VERSION ""

NS_ :

BS_:

BU_:

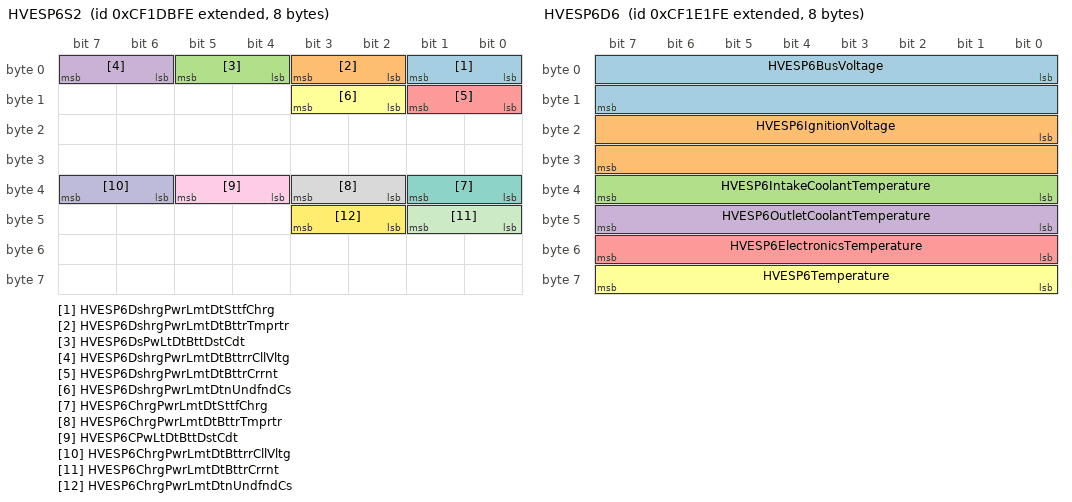
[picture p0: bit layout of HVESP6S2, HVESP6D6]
BO_ 2364660734 HVESP6S2: 8 Vector__XXX
 SG_ HVESP6DshrgPwrLmtDtSttfChrg : 0|2@1+ (1,0) [0|3] "" Vector__XXX
 SG_ HVESP6DshrgPwrLmtDtBttrTmprtr : 2|2@1+ (1,0) [0|3] "" Vector__XXX
 SG_ HVESP6DsPwLtDtBttDstCdt : 4|2@1+ (1,0) [0|3] "" Vector__XXX
 SG_ HVESP6DshrgPwrLmtDtBttrrCllVltg : 6|2@1+ (1,0) [0|3] "" Vector__XXX
 SG_ HVESP6DshrgPwrLmtDtBttrCrrnt : 8|2@1+ (1,0) [0|3] "" Vector__XXX
 SG_ HVESP6DshrgPwrLmtDtnUndfndCs : 10|2@1+ (1,0) [0|3] "" Vector__XXX
 SG_ HVESP6ChrgPwrLmtDtSttfChrg : 32|2@1+ (1,0) [0|3] "" Vector__XXX
 SG_ HVESP6ChrgPwrLmtDtBttrTmprtr : 34|2@1+ (1,0) [0|3] "" Vector__XXX
 SG_ HVESP6CPwLtDtBttDstCdt : 36|2@1+ (1,0) [0|3] "" Vector__XXX
 SG_ HVESP6ChrgPwrLmtDtBttrrCllVltg : 38|2@1+ (1,0) [0|3] "" Vector__XXX
 SG_ HVESP6ChrgPwrLmtDtBttrCrrnt : 40|2@1+ (1,0) [0|3] "" Vector__XXX
 SG_ HVESP6ChrgPwrLmtDtnUndfndCs : 42|2@1+ (1,0) [0|3] "" Vector__XXX

BO_ 2364660990 HVESP6D1: 8 Vector__XXX
 SG_ HVESP6AvailableDischargePower : 0|16@1+ (0.05,0) [0|3212.75] "kW" Vector__XXX
 SG_ HVESP6AvailableChargePower : 16|16@1+ (0.05,0) [0|3212.75] "kW" Vector__XXX
 SG_ HVESP6VoltageLevel : 32|16@1+ (0.05,0) [0|3212.75] "V" Vector__XXX
 SG_ HVESP6Current : 48|16@1+ (0.05,-1600) [-1600|1612.75] "A" Vector__XXX

BO_ 2364661246 HVESP6D2: 8 Vector__XXX
 SG_ HVESP6FastUpdateStateofCharge : 0|16@1+ (0.0015625,0) [0|100.3984375] "%" Vector__XXX
 SG_ HVESP6HighestCellVoltage : 16|16@1+ (0.001,0) [0|64.255] "V" Vector__XXX
 SG_ HVESP6LowestCellVoltage : 32|16@1+ (0.001,0) [0|64.255] "V" Vector__XXX
 SG_ HVESP6CllVltgDffrntlStts : 48|4@1+ (1,0) [0|15] "" Vector__XXX

BO_ 2364661502 HVESP6D3: 8 Vector__XXX
 SG_ HVESP6HighestCellTemperature : 0|16@1+ (0.03125,-273) [-273|1734.96875] "degC" Vector__XXX
 SG_ HVESP6LowestCellTemperature : 16|16@1+ (0.03125,-273) [-273|1734.96875] "degC" Vector__XXX
 SG_ HVESP6AverageCellTemperature : 32|16@1+ (0.03125,-273) [-273|1734.96875] "degC" Vector__XXX
 SG_ HVESP6CllTmprtrDffrntlStts : 48|2@1+ (1,0) [0|3] "" Vector__XXX

BO_ 2364661758 HVESP6D4: 8 Vector__XXX
 SG_ HVESP6DischargeCapacity : 0|16@1+ (0.01,0) [0|642.55] "Ah" Vector__XXX
 SG_ HVESP6ChargeCapacity : 16|16@1+ (0.01,0) [0|642.55] "Ah" Vector__XXX
 SG_ HVESP6CellBalancingCount : 32|16@1+ (1,0) [0|64255] "count" Vector__XXX

BO_ 2364662014 HVESP6D5: 8 Vector__XXX
 SG_ HVESP6DischargeCurrentLimit : 0|16@1+ (0.05,-1600) [-1600|1612.75] "A" Vector__XXX
 SG_ HVESP6ChargeCurrentLimit : 16|16@1+ (0.05,-1600) [-1600|1612.75] "A" Vector__XXX
 SG_ HVESP6LowestCellStateofCharge : 32|16@1+ (0.0015625,0) [0|100.3984375] "%" Vector__XXX
 SG_ HVESP6HighestCellStateofCharge : 48|16@1+ (0.0015625,0) [0|100.3984375] "%" Vector__XXX

BO_ 2364662270 HVESP6D6: 8 Vector__XXX
 SG_ HVESP6BusVoltage : 0|16@1+ (0.05,0) [0|3212.75] "V" Vector__XXX
 SG_ HVESP6IgnitionVoltage : 16|16@1+ (0.01,0) [0|642.55] "V" Vector__XXX
 SG_ HVESP6IntakeCoolantTemperature : 32|8@1+ (1,-40) [-40|210] "degC" Vector__XXX
 SG_ HVESP6OutletCoolantTemperature : 40|8@1+ (1,-40) [-40|210] "degC" Vector__XXX
 SG_ HVESP6ElectronicsTemperature : 48|8@1+ (1,-40) [-40|210] "degC" Vector__XXX
 SG_ HVESP6Temperature : 56|8@1+ (1,-40) [-40|210] "degC" Vector__XXX

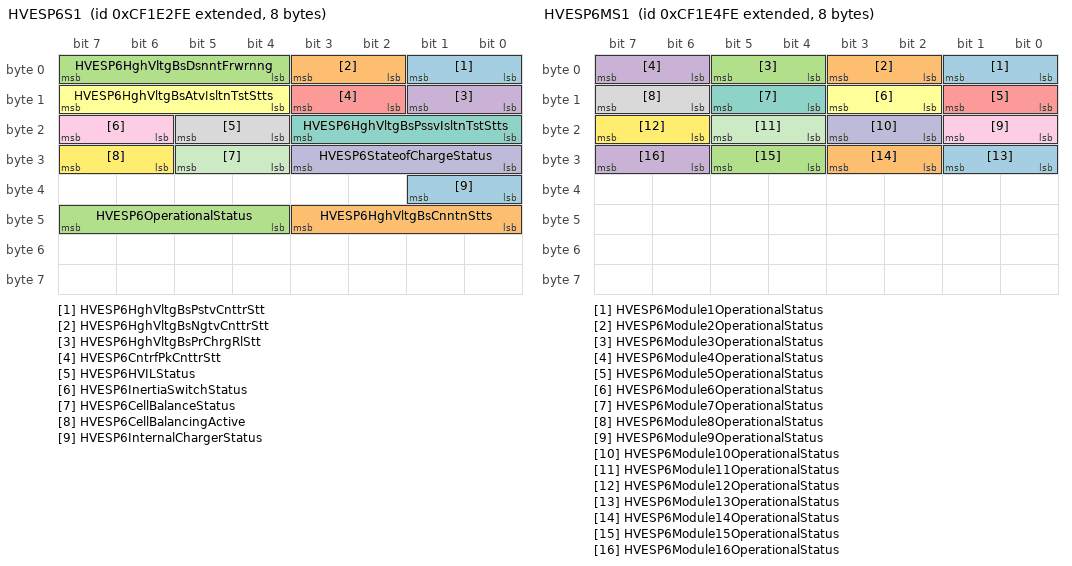
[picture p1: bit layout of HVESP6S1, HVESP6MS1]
BO_ 2364662526 HVESP6S1: 8 Vector__XXX
 SG_ HVESP6HghVltgBsPstvCnttrStt : 0|2@1+ (1,0) [0|3] "" Vector__XXX
 SG_ HVESP6HghVltgBsNgtvCnttrStt : 2|2@1+ (1,0) [0|3] "" Vector__XXX
 SG_ HVESP6HghVltgBsDsnntFrwrnng : 4|4@1+ (1,0) [0|15] "" Vector__XXX
 SG_ HVESP6HghVltgBsPrChrgRlStt : 8|2@1+ (1,0) [0|3] "" Vector__XXX
 SG_ HVESP6CntrfPkCnttrStt : 10|2@1+ (1,0) [0|3] "" Vector__XXX
 SG_ HVESP6HghVltgBsAtvIsltnTstStts : 12|4@1+ (1,0) [0|15] "" Vector__XXX
 SG_ HVESP6HghVltgBsPssvIsltnTstStts : 16|4@1+ (1,0) [0|15] "" Vector__XXX
 SG_ HVESP6HVILStatus : 20|2@1+ (1,0) [0|3] "" Vector__XXX
 SG_ HVESP6InertiaSwitchStatus : 22|2@1+ (1,0) [0|3] "" Vector__XXX
 SG_ HVESP6StateofChargeStatus : 24|4@1+ (1,0) [0|15] "" Vector__XXX
 SG_ HVESP6CellBalanceStatus : 28|2@1+ (1,0) [0|3] "" Vector__XXX
 SG_ HVESP6CellBalancingActive : 30|2@1+ (1,0) [0|3] "" Vector__XXX
 SG_ HVESP6InternalChargerStatus : 32|2@1+ (1,0) [0|3] "" Vector__XXX
 SG_ HVESP6HghVltgBsCnntnStts : 40|4@1+ (1,0) [0|15] "" Vector__XXX
 SG_ HVESP6OperationalStatus : 44|4@1+ (1,0) [0|15] "" Vector__XXX

BO_ 2364662782 HVESP6D7: 8 Vector__XXX
 SG_ HVESP6DischargeEnergyCapacity : 0|24@1+ (0.001,0) [0|16449.535] "kWh" Vector__XXX
 SG_ HVESP6ChargeEnergyCapacity : 24|24@1+ (0.001,0) [0|16449.535] "kWh" Vector__XXX
 SG_ HVESP6MaximumChargeVoltageLimit : 48|16@1+ (0.05,0) [0|3212.75] "V" Vector__XXX

BO_ 2364663038 HVESP6MS1: 8 Vector__XXX
 SG_ HVESP6Module1OperationalStatus : 0|2@1+ (1,0) [0|3] "" Vector__XXX
 SG_ HVESP6Module2OperationalStatus : 2|2@1+ (1,0) [0|3] "" Vector__XXX
 SG_ HVESP6Module3OperationalStatus : 4|2@1+ (1,0) [0|3] "" Vector__XXX
 SG_ HVESP6Module4OperationalStatus : 6|2@1+ (1,0) [0|3] "" Vector__XXX
 SG_ HVESP6Module5OperationalStatus : 8|2@1+ (1,0) [0|3] "" Vector__XXX
 SG_ HVESP6Module6OperationalStatus : 10|2@1+ (1,0) [0|3] "" Vector__XXX
 SG_ HVESP6Module7OperationalStatus : 12|2@1+ (1,0) [0|3] "" Vector__XXX
 SG_ HVESP6Module8OperationalStatus : 14|2@1+ (1,0) [0|3] "" Vector__XXX
 SG_ HVESP6Module9OperationalStatus : 16|2@1+ (1,0) [0|3] "" Vector__XXX
 SG_ HVESP6Module10OperationalStatus : 18|2@1+ (1,0) [0|3] "" Vector__XXX
 SG_ HVESP6Module11OperationalStatus : 20|2@1+ (1,0) [0|3] "" Vector__XXX
 SG_ HVESP6Module12OperationalStatus : 22|2@1+ (1,0) [0|3] "" Vector__XXX
 SG_ HVESP6Module13OperationalStatus : 24|2@1+ (1,0) [0|3] "" Vector__XXX
 SG_ HVESP6Module14OperationalStatus : 26|2@1+ (1,0) [0|3] "" Vector__XXX
 SG_ HVESP6Module15OperationalStatus : 28|2@1+ (1,0) [0|3] "" Vector__XXX
 SG_ HVESP6Module16OperationalStatus : 30|2@1+ (1,0) [0|3] "" Vector__XXX

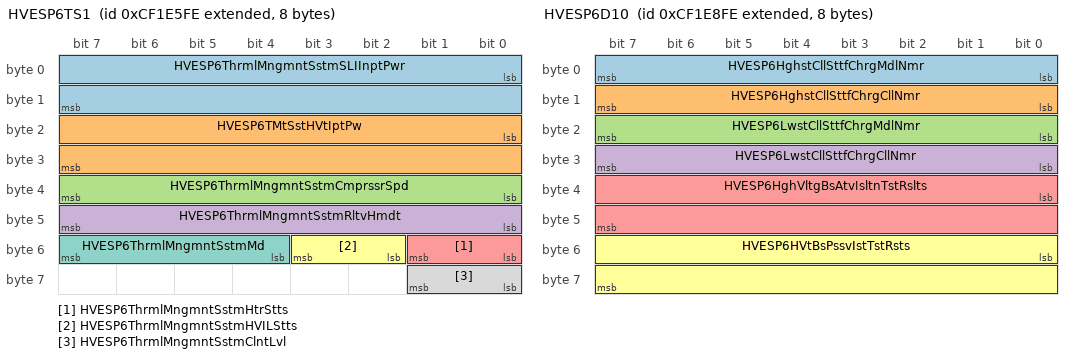
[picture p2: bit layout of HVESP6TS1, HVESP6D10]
BO_ 2364663294 HVESP6TS1: 8 Vector__XXX
 SG_ HVESP6ThrmlMngmntSstmSLIInptPwr : 0|16@1+ (0.5,0) [0|32127.5] "W" Vector__XXX
 SG_ HVESP6TMtSstHVtIptPw : 16|16@1+ (0.5,0) [0|32127.5] "W" Vector__XXX
 SG_ HVESP6ThrmlMngmntSstmCmprssrSpd : 32|8@1+ (32,0) [0|8000] "rpm" Vector__XXX
 SG_ HVESP6ThrmlMngmntSstmRltvHmdt : 40|8@1+ (0.4,0) [0|100] "%" Vector__XXX
 SG_ HVESP6ThrmlMngmntSstmHtrStts : 48|2@1+ (1,0) [0|3] "" Vector__XXX
 SG_ HVESP6ThrmlMngmntSstmHVILStts : 50|2@1+ (1,0) [0|3] "" Vector__XXX
 SG_ HVESP6ThrmlMngmntSstmMd : 52|4@1+ (1,0) [0|15] "" Vector__XXX
 SG_ HVESP6ThrmlMngmntSstmClntLvl : 56|2@1+ (1,0) [0|3] "" Vector__XXX

BO_ 2364663550 HVESP6D8: 8 Vector__XXX
 SG_ HVESP6HghstCllVltgMdlNmr : 0|8@1+ (1,0) [0|250] "count" Vector__XXX
 SG_ HVESP6HghstCllVltgCllNmr : 8|8@1+ (1,0) [0|250] "count" Vector__XXX
 SG_ HVESP6LwstCllVltgMdlNmr : 16|8@1+ (1,0) [0|250] "count" Vector__XXX
 SG_ HVESP6LwstCllVltgCllNmr : 24|8@1+ (1,0) [0|250] "count" Vector__XXX
 SG_ HVESP6AverageCellVoltage : 32|16@1+ (0.001,0) [0|64.255] "V" Vector__XXX

BO_ 2364663806 HVESP6D9: 8 Vector__XXX
 SG_ HVESP6HghstCllTmprtrMdlNmr : 0|8@1+ (1,0) [0|250] "count" Vector__XXX
 SG_ HVESP6HghstCllTmprtrCllNmr : 8|8@1+ (1,0) [0|250] "count" Vector__XXX
 SG_ HVESP6LwstCllTmprtrMdlNmr : 16|8@1+ (1,0) [0|250] "count" Vector__XXX
 SG_ HVESP6LwstCllTmprtrCllNmr : 24|8@1+ (1,0) [0|250] "count" Vector__XXX

BO_ 2364664062 HVESP6D10: 8 Vector__XXX
 SG_ HVESP6HghstCllSttfChrgMdlNmr : 0|8@1+ (1,0) [0|250] "count" Vector__XXX
 SG_ HVESP6HghstCllSttfChrgCllNmr : 8|8@1+ (1,0) [0|250] "count" Vector__XXX
 SG_ HVESP6LwstCllSttfChrgMdlNmr : 16|8@1+ (1,0) [0|250] "count" Vector__XXX
 SG_ HVESP6LwstCllSttfChrgCllNmr : 24|8@1+ (1,0) [0|250] "count" Vector__XXX
 SG_ HVESP6HghVltgBsAtvIsltnTstRslts : 32|16@1+ (0.1,0) [0|6425.5] "ohm/V" Vector__XXX
 SG_ HVESP6HVtBsPssvIstTstRsts : 48|16@1+ (0.1,0) [0|6425.5] "ohm/V" Vector__XXX

BO_ 2364664318 HVESP6D11: 8 Vector__XXX
 SG_ HVESP6BsVltgNgtvtChsssGrndVltg : 0|16@1+ (0.05,0) [0|3212.75] "V" Vector__XXX
 SG_ HVESP6VltgLvlNgtvtChsssGrndVltg : 16|16@1+ (0.05,0) [0|3212.75] "V" Vector__XXX

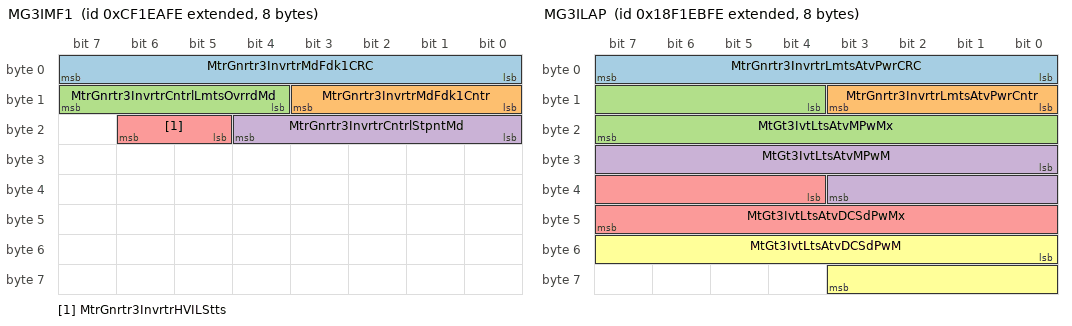
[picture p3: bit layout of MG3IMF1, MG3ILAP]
BO_ 2364664574 MG3IMF1: 8 Vector__XXX
 SG_ MtrGnrtr3InvrtrMdFdk1CRC : 0|8@1+ (1,0) [0|255] "count" Vector__XXX
 SG_ MtrGnrtr3InvrtrMdFdk1Cntr : 8|4@1+ (1,0) [0|15] "" Vector__XXX
 SG_ MtrGnrtr3InvrtrCntrlLmtsOvrrdMd : 12|4@1+ (1,0) [0|15] "" Vector__XXX
 SG_ MtrGnrtr3InvrtrCntrlStpntMd : 16|5@1+ (1,0) [0|31] "" Vector__XXX
 SG_ MtrGnrtr3InvrtrHVILStts : 21|2@1+ (1,0) [0|3] "" Vector__XXX

BO_ 2565991422 MG3ILAP: 8 Vector__XXX
 SG_ MtrGnrtr3InvrtrLmtsAtvPwrCRC : 0|8@1+ (1,0) [0|255] "count" Vector__XXX
 SG_ MtrGnrtr3InvrtrLmtsAtvPwrCntr : 8|4@1+ (1,0) [0|15] "" Vector__XXX
 SG_ MtGt3IvtLtsAtvMPwMx : 12|12@1+ (42370,-125) [-125|125.9375] "%" Vector__XXX
 SG_ MtGt3IvtLtsAtvMPwM : 24|12@1+ (42370,-125) [-125|125.9375] "%" Vector__XXX
 SG_ MtGt3IvtLtsAtvDCSdPwMx : 36|12@1+ (42370,-125) [-125|125.9375] "%" Vector__XXX
 SG_ MtGt3IvtLtsAtvDCSdPwM : 48|12@1+ (42370,-125) [-125|125.9375] "%" Vector__XXX

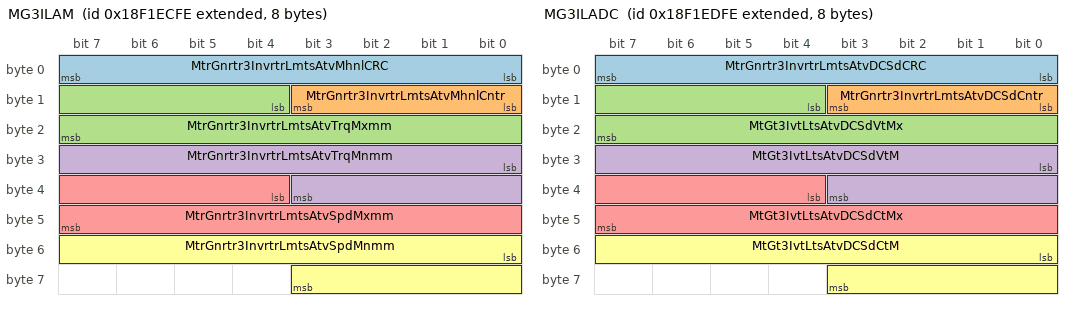
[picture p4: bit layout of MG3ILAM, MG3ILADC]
BO_ 2565991678 MG3ILAM: 8 Vector__XXX
 SG_ MtrGnrtr3InvrtrLmtsAtvMhnlCRC : 0|8@1+ (1,0) [0|255] "count" Vector__XXX
 SG_ MtrGnrtr3InvrtrLmtsAtvMhnlCntr : 8|4@1+ (1,0) [0|15] "" Vector__XXX
 SG_ MtrGnrtr3InvrtrLmtsAtvTrqMxmm : 12|12@1+ (42370,-125) [-125|125.9375] "%" Vector__XXX
 SG_ MtrGnrtr3InvrtrLmtsAtvTrqMnmm : 24|12@1+ (42370,-125) [-125|125.9375] "%" Vector__XXX
 SG_ MtrGnrtr3InvrtrLmtsAtvSpdMxmm : 36|12@1+ (42370,-125) [-125|125.9375] "%" Vector__XXX
 SG_ MtrGnrtr3InvrtrLmtsAtvSpdMnmm : 48|12@1+ (42370,-125) [-125|125.9375] "%" Vector__XXX

BO_ 2565991934 MG3ILADC: 8 Vector__XXX
 SG_ MtrGnrtr3InvrtrLmtsAtvDCSdCRC : 0|8@1+ (1,0) [0|255] "count" Vector__XXX
 SG_ MtrGnrtr3InvrtrLmtsAtvDCSdCntr : 8|4@1+ (1,0) [0|15] "" Vector__XXX
 SG_ MtGt3IvtLtsAtvDCSdVtMx : 12|12@1+ (42370,-125) [-125|125.9375] "%" Vector__XXX
 SG_ MtGt3IvtLtsAtvDCSdVtM : 24|12@1+ (42370,-125) [-125|125.9375] "%" Vector__XXX
 SG_ MtGt3IvtLtsAtvDCSdCtMx : 36|12@1+ (42370,-125) [-125|125.9375] "%" Vector__XXX
 SG_ MtGt3IvtLtsAtvDCSdCtM : 48|12@1+ (42370,-125) [-125|125.9375] "%" Vector__XXX

BO_ 2565992190 MG3ILV: 8 Vector__XXX
 SG_ MtrGnrtr3InvrtrSwthdIgntnVltg : 0|16@1+ (0.05,0) [0|3212.75] "V" Vector__XXX
 SG_ MtrGnrtr3InvrtrUnswthdSLIVltg : 16|16@1+ (0.05,0) [0|3212.75] "V" Vector__XXX

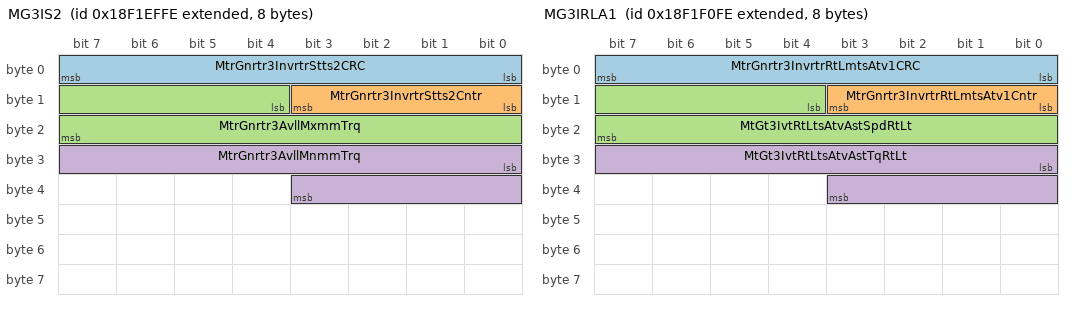
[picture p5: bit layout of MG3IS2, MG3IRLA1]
BO_ 2565992446 MG3IS2: 8 Vector__XXX
 SG_ MtrGnrtr3InvrtrStts2CRC : 0|8@1+ (1,0) [0|255] "count" Vector__XXX
 SG_ MtrGnrtr3InvrtrStts2Cntr : 8|4@1+ (1,0) [0|15] "" Vector__XXX
 SG_ MtrGnrtr3AvllMxmmTrq : 12|12@1+ (42370,-125) [-125|125.9375] "%" Vector__XXX
 SG_ MtrGnrtr3AvllMnmmTrq : 24|12@1+ (42370,-125) [-125|125.9375] "%" Vector__XXX

BO_ 2565992702 MG3IRLA1: 8 Vector__XXX
 SG_ MtrGnrtr3InvrtrRtLmtsAtv1CRC : 0|8@1+ (1,0) [0|255] "count" Vector__XXX
 SG_ MtrGnrtr3InvrtrRtLmtsAtv1Cntr : 8|4@1+ (1,0) [0|15] "" Vector__XXX
 SG_ MtGt3IvtRtLtsAtvAstSpdRtLt : 12|12@1+ (0.25,0) [0|1003.75] "%/s" Vector__XXX
 SG_ MtGt3IvtRtLtsAtvAstTqRtLt : 24|12@1+ (2,0) [0|8030] "%/s" Vector__XXX

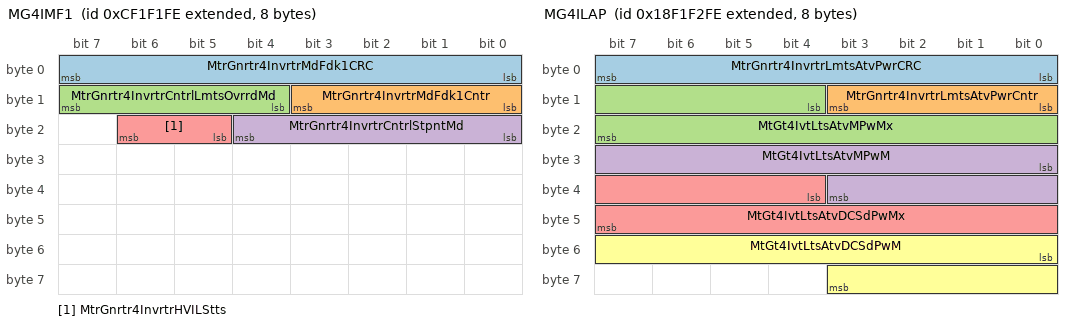
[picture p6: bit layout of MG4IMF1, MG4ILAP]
BO_ 2364666366 MG4IMF1: 8 Vector__XXX
 SG_ MtrGnrtr4InvrtrMdFdk1CRC : 0|8@1+ (1,0) [0|255] "count" Vector__XXX
 SG_ MtrGnrtr4InvrtrMdFdk1Cntr : 8|4@1+ (1,0) [0|15] "" Vector__XXX
 SG_ MtrGnrtr4InvrtrCntrlLmtsOvrrdMd : 12|4@1+ (1,0) [0|15] "" Vector__XXX
 SG_ MtrGnrtr4InvrtrCntrlStpntMd : 16|5@1+ (1,0) [0|31] "" Vector__XXX
 SG_ MtrGnrtr4InvrtrHVILStts : 21|2@1+ (1,0) [0|3] "" Vector__XXX

BO_ 2565993214 MG4ILAP: 8 Vector__XXX
 SG_ MtrGnrtr4InvrtrLmtsAtvPwrCRC : 0|8@1+ (1,0) [0|255] "count" Vector__XXX
 SG_ MtrGnrtr4InvrtrLmtsAtvPwrCntr : 8|4@1+ (1,0) [0|15] "" Vector__XXX
 SG_ MtGt4IvtLtsAtvMPwMx : 12|12@1+ (42370,-125) [-125|125.9375] "%" Vector__XXX
 SG_ MtGt4IvtLtsAtvMPwM : 24|12@1+ (42370,-125) [-125|125.9375] "%" Vector__XXX
 SG_ MtGt4IvtLtsAtvDCSdPwMx : 36|12@1+ (42370,-125) [-125|125.9375] "%" Vector__XXX
 SG_ MtGt4IvtLtsAtvDCSdPwM : 48|12@1+ (42370,-125) [-125|125.9375] "%" Vector__XXX

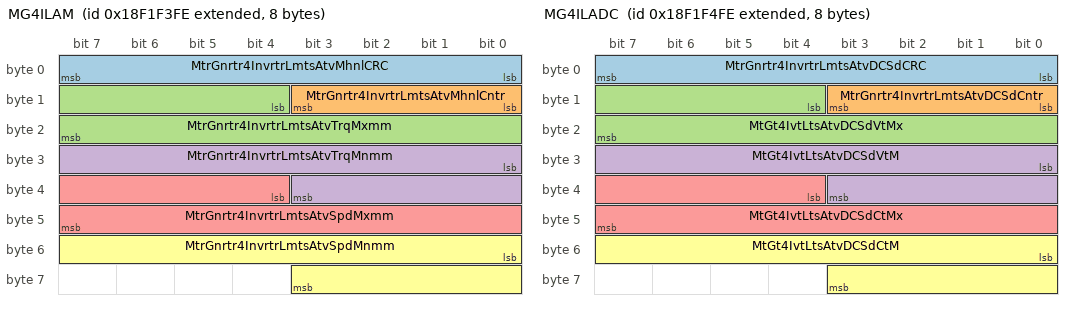
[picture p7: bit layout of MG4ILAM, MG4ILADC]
BO_ 2565993470 MG4ILAM: 8 Vector__XXX
 SG_ MtrGnrtr4InvrtrLmtsAtvMhnlCRC : 0|8@1+ (1,0) [0|255] "count" Vector__XXX
 SG_ MtrGnrtr4InvrtrLmtsAtvMhnlCntr : 8|4@1+ (1,0) [0|15] "" Vector__XXX
 SG_ MtrGnrtr4InvrtrLmtsAtvTrqMxmm : 12|12@1+ (42370,-125) [-125|125.9375] "%" Vector__XXX
 SG_ MtrGnrtr4InvrtrLmtsAtvTrqMnmm : 24|12@1+ (42370,-125) [-125|125.9375] "%" Vector__XXX
 SG_ MtrGnrtr4InvrtrLmtsAtvSpdMxmm : 36|12@1+ (42370,-125) [-125|125.9375] "%" Vector__XXX
 SG_ MtrGnrtr4InvrtrLmtsAtvSpdMnmm : 48|12@1+ (42370,-125) [-125|125.9375] "%" Vector__XXX

BO_ 2565993726 MG4ILADC: 8 Vector__XXX
 SG_ MtrGnrtr4InvrtrLmtsAtvDCSdCRC : 0|8@1+ (1,0) [0|255] "count" Vector__XXX
 SG_ MtrGnrtr4InvrtrLmtsAtvDCSdCntr : 8|4@1+ (1,0) [0|15] "" Vector__XXX
 SG_ MtGt4IvtLtsAtvDCSdVtMx : 12|12@1+ (42370,-125) [-125|125.9375] "%" Vector__XXX
 SG_ MtGt4IvtLtsAtvDCSdVtM : 24|12@1+ (42370,-125) [-125|125.9375] "%" Vector__XXX
 SG_ MtGt4IvtLtsAtvDCSdCtMx : 36|12@1+ (42370,-125) [-125|125.9375] "%" Vector__XXX
 SG_ MtGt4IvtLtsAtvDCSdCtM : 48|12@1+ (42370,-125) [-125|125.9375] "%" Vector__XXX

BO_ 2565993982 MG4ILV: 8 Vector__XXX
 SG_ MtrGnrtr4InvrtrSwthdIgntnVltg : 0|16@1+ (0.05,0) [0|3212.75] "V" Vector__XXX
 SG_ MtrGnrtr4InvrtrUnswthdSLIVltg : 16|16@1+ (0.05,0) [0|3212.75] "V" Vector__XXX

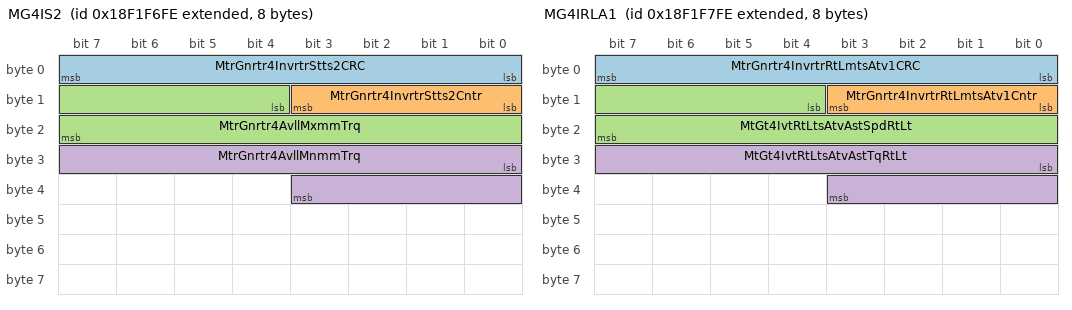
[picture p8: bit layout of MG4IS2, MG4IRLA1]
BO_ 2565994238 MG4IS2: 8 Vector__XXX
 SG_ MtrGnrtr4InvrtrStts2CRC : 0|8@1+ (1,0) [0|255] "count" Vector__XXX
 SG_ MtrGnrtr4InvrtrStts2Cntr : 8|4@1+ (1,0) [0|15] "" Vector__XXX
 SG_ MtrGnrtr4AvllMxmmTrq : 12|12@1+ (42370,-125) [-125|125.9375] "%" Vector__XXX
 SG_ MtrGnrtr4AvllMnmmTrq : 24|12@1+ (42370,-125) [-125|125.9375] "%" Vector__XXX

BO_ 2565994494 MG4IRLA1: 8 Vector__XXX
 SG_ MtrGnrtr4InvrtrRtLmtsAtv1CRC : 0|8@1+ (1,0) [0|255] "count" Vector__XXX
 SG_ MtrGnrtr4InvrtrRtLmtsAtv1Cntr : 8|4@1+ (1,0) [0|15] "" Vector__XXX
 SG_ MtGt4IvtRtLtsAtvAstSpdRtLt : 12|12@1+ (0.25,0) [0|1003.75] "%/s" Vector__XXX
 SG_ MtGt4IvtRtLtsAtvAstTqRtLt : 24|12@1+ (2,0) [0|8030] "%/s" Vector__XXX

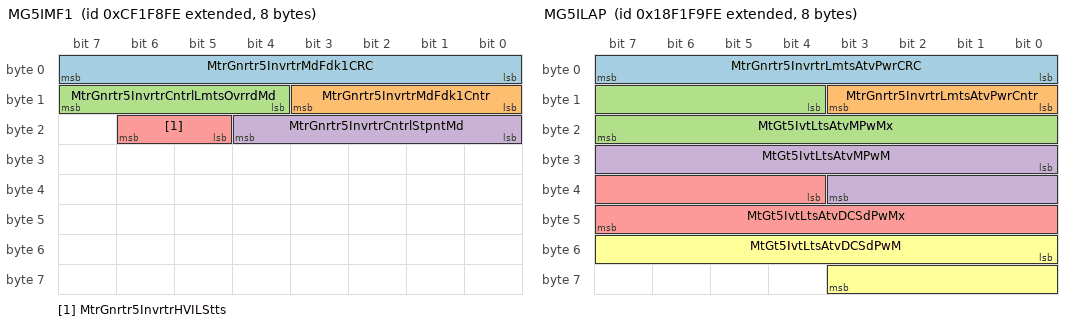
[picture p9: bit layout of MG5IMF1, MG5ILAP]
BO_ 2364668158 MG5IMF1: 8 Vector__XXX
 SG_ MtrGnrtr5InvrtrMdFdk1CRC : 0|8@1+ (1,0) [0|255] "count" Vector__XXX
 SG_ MtrGnrtr5InvrtrMdFdk1Cntr : 8|4@1+ (1,0) [0|15] "" Vector__XXX
 SG_ MtrGnrtr5InvrtrCntrlLmtsOvrrdMd : 12|4@1+ (1,0) [0|15] "" Vector__XXX
 SG_ MtrGnrtr5InvrtrCntrlStpntMd : 16|5@1+ (1,0) [0|31] "" Vector__XXX
 SG_ MtrGnrtr5InvrtrHVILStts : 21|2@1+ (1,0) [0|3] "" Vector__XXX

BO_ 2565995006 MG5ILAP: 8 Vector__XXX
 SG_ MtrGnrtr5InvrtrLmtsAtvPwrCRC : 0|8@1+ (1,0) [0|255] "count" Vector__XXX
 SG_ MtrGnrtr5InvrtrLmtsAtvPwrCntr : 8|4@1+ (1,0) [0|15] "" Vector__XXX
 SG_ MtGt5IvtLtsAtvMPwMx : 12|12@1+ (42370,-125) [-125|125.9375] "%" Vector__XXX
 SG_ MtGt5IvtLtsAtvMPwM : 24|12@1+ (42370,-125) [-125|125.9375] "%" Vector__XXX
 SG_ MtGt5IvtLtsAtvDCSdPwMx : 36|12@1+ (42370,-125) [-125|125.9375] "%" Vector__XXX
 SG_ MtGt5IvtLtsAtvDCSdPwM : 48|12@1+ (42370,-125) [-125|125.9375] "%" Vector__XXX

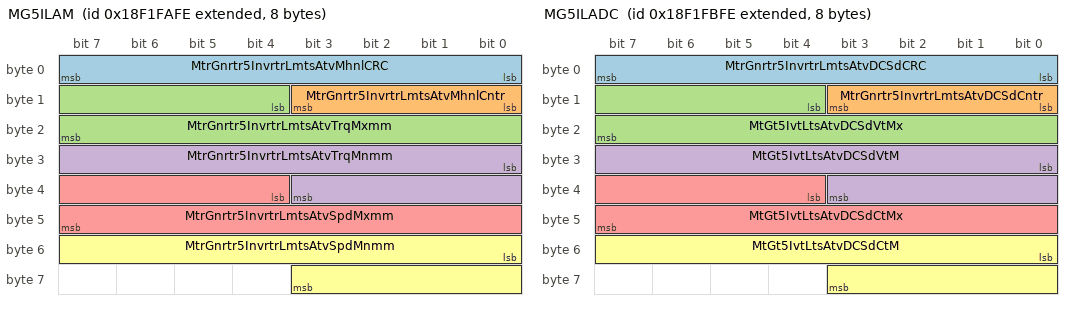
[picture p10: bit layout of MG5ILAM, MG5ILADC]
BO_ 2565995262 MG5ILAM: 8 Vector__XXX
 SG_ MtrGnrtr5InvrtrLmtsAtvMhnlCRC : 0|8@1+ (1,0) [0|255] "count" Vector__XXX
 SG_ MtrGnrtr5InvrtrLmtsAtvMhnlCntr : 8|4@1+ (1,0) [0|15] "" Vector__XXX
 SG_ MtrGnrtr5InvrtrLmtsAtvTrqMxmm : 12|12@1+ (42370,-125) [-125|125.9375] "%" Vector__XXX
 SG_ MtrGnrtr5InvrtrLmtsAtvTrqMnmm : 24|12@1+ (42370,-125) [-125|125.9375] "%" Vector__XXX
 SG_ MtrGnrtr5InvrtrLmtsAtvSpdMxmm : 36|12@1+ (42370,-125) [-125|125.9375] "%" Vector__XXX
 SG_ MtrGnrtr5InvrtrLmtsAtvSpdMnmm : 48|12@1+ (42370,-125) [-125|125.9375] "%" Vector__XXX

BO_ 2565995518 MG5ILADC: 8 Vector__XXX
 SG_ MtrGnrtr5InvrtrLmtsAtvDCSdCRC : 0|8@1+ (1,0) [0|255] "count" Vector__XXX
 SG_ MtrGnrtr5InvrtrLmtsAtvDCSdCntr : 8|4@1+ (1,0) [0|15] "" Vector__XXX
 SG_ MtGt5IvtLtsAtvDCSdVtMx : 12|12@1+ (42370,-125) [-125|125.9375] "%" Vector__XXX
 SG_ MtGt5IvtLtsAtvDCSdVtM : 24|12@1+ (42370,-125) [-125|125.9375] "%" Vector__XXX
 SG_ MtGt5IvtLtsAtvDCSdCtMx : 36|12@1+ (42370,-125) [-125|125.9375] "%" Vector__XXX
 SG_ MtGt5IvtLtsAtvDCSdCtM : 48|12@1+ (42370,-125) [-125|125.9375] "%" Vector__XXX

BO_ 2565995774 MG5ILV: 8 Vector__XXX
 SG_ MtrGnrtr5InvrtrSwthdIgntnVltg : 0|16@1+ (0.05,0) [0|3212.75] "V" Vector__XXX
 SG_ MtrGnrtr5InvrtrUnswthdSLIVltg : 16|16@1+ (0.05,0) [0|3212.75] "V" Vector__XXX

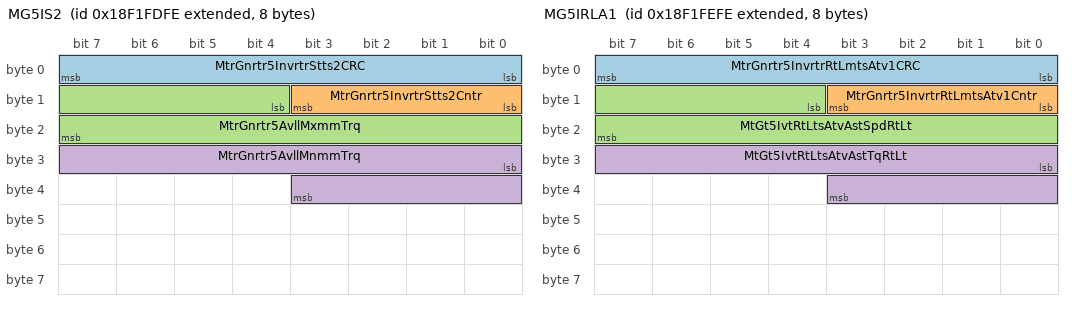
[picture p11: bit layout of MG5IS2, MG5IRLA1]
BO_ 2565996030 MG5IS2: 8 Vector__XXX
 SG_ MtrGnrtr5InvrtrStts2CRC : 0|8@1+ (1,0) [0|255] "count" Vector__XXX
 SG_ MtrGnrtr5InvrtrStts2Cntr : 8|4@1+ (1,0) [0|15] "" Vector__XXX
 SG_ MtrGnrtr5AvllMxmmTrq : 12|12@1+ (42370,-125) [-125|125.9375] "%" Vector__XXX
 SG_ MtrGnrtr5AvllMnmmTrq : 24|12@1+ (42370,-125) [-125|125.9375] "%" Vector__XXX

BO_ 2565996286 MG5IRLA1: 8 Vector__XXX
 SG_ MtrGnrtr5InvrtrRtLmtsAtv1CRC : 0|8@1+ (1,0) [0|255] "count" Vector__XXX
 SG_ MtrGnrtr5InvrtrRtLmtsAtv1Cntr : 8|4@1+ (1,0) [0|15] "" Vector__XXX
 SG_ MtGt5IvtRtLtsAtvAstSpdRtLt : 12|12@1+ (0.25,0) [0|1003.75] "%/s" Vector__XXX
 SG_ MtGt5IvtRtLtsAtvAstTqRtLt : 24|12@1+ (2,0) [0|8030] "%/s" Vector__XXX

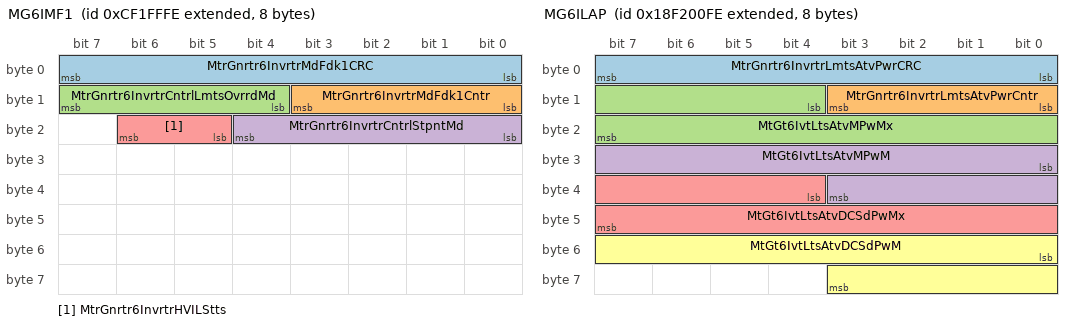
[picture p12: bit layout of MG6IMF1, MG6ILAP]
BO_ 2364669950 MG6IMF1: 8 Vector__XXX
 SG_ MtrGnrtr6InvrtrMdFdk1CRC : 0|8@1+ (1,0) [0|255] "count" Vector__XXX
 SG_ MtrGnrtr6InvrtrMdFdk1Cntr : 8|4@1+ (1,0) [0|15] "" Vector__XXX
 SG_ MtrGnrtr6InvrtrCntrlLmtsOvrrdMd : 12|4@1+ (1,0) [0|15] "" Vector__XXX
 SG_ MtrGnrtr6InvrtrCntrlStpntMd : 16|5@1+ (1,0) [0|31] "" Vector__XXX
 SG_ MtrGnrtr6InvrtrHVILStts : 21|2@1+ (1,0) [0|3] "" Vector__XXX

BO_ 2565996798 MG6ILAP: 8 Vector__XXX
 SG_ MtrGnrtr6InvrtrLmtsAtvPwrCRC : 0|8@1+ (1,0) [0|255] "count" Vector__XXX
 SG_ MtrGnrtr6InvrtrLmtsAtvPwrCntr : 8|4@1+ (1,0) [0|15] "" Vector__XXX
 SG_ MtGt6IvtLtsAtvMPwMx : 12|12@1+ (42370,-125) [-125|125.9375] "%" Vector__XXX
 SG_ MtGt6IvtLtsAtvMPwM : 24|12@1+ (42370,-125) [-125|125.9375] "%" Vector__XXX
 SG_ MtGt6IvtLtsAtvDCSdPwMx : 36|12@1+ (42370,-125) [-125|125.9375] "%" Vector__XXX
 SG_ MtGt6IvtLtsAtvDCSdPwM : 48|12@1+ (42370,-125) [-125|125.9375] "%" Vector__XXX

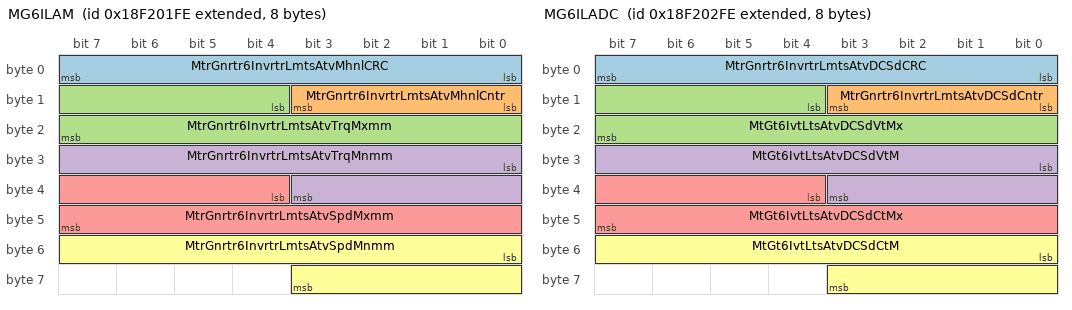
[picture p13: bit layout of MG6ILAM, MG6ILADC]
BO_ 2565997054 MG6ILAM: 8 Vector__XXX
 SG_ MtrGnrtr6InvrtrLmtsAtvMhnlCRC : 0|8@1+ (1,0) [0|255] "count" Vector__XXX
 SG_ MtrGnrtr6InvrtrLmtsAtvMhnlCntr : 8|4@1+ (1,0) [0|15] "" Vector__XXX
 SG_ MtrGnrtr6InvrtrLmtsAtvTrqMxmm : 12|12@1+ (42370,-125) [-125|125.9375] "%" Vector__XXX
 SG_ MtrGnrtr6InvrtrLmtsAtvTrqMnmm : 24|12@1+ (42370,-125) [-125|125.9375] "%" Vector__XXX
 SG_ MtrGnrtr6InvrtrLmtsAtvSpdMxmm : 36|12@1+ (42370,-125) [-125|125.9375] "%" Vector__XXX
 SG_ MtrGnrtr6InvrtrLmtsAtvSpdMnmm : 48|12@1+ (42370,-125) [-125|125.9375] "%" Vector__XXX

BO_ 2565997310 MG6ILADC: 8 Vector__XXX
 SG_ MtrGnrtr6InvrtrLmtsAtvDCSdCRC : 0|8@1+ (1,0) [0|255] "count" Vector__XXX
 SG_ MtrGnrtr6InvrtrLmtsAtvDCSdCntr : 8|4@1+ (1,0) [0|15] "" Vector__XXX
 SG_ MtGt6IvtLtsAtvDCSdVtMx : 12|12@1+ (42370,-125) [-125|125.9375] "%" Vector__XXX
 SG_ MtGt6IvtLtsAtvDCSdVtM : 24|12@1+ (42370,-125) [-125|125.9375] "%" Vector__XXX
 SG_ MtGt6IvtLtsAtvDCSdCtMx : 36|12@1+ (42370,-125) [-125|125.9375] "%" Vector__XXX
 SG_ MtGt6IvtLtsAtvDCSdCtM : 48|12@1+ (42370,-125) [-125|125.9375] "%" Vector__XXX

BO_ 2565997566 MG6ILV: 8 Vector__XXX
 SG_ MtrGnrtr6InvrtrSwthdIgntnVltg : 0|16@1+ (0.05,0) [0|3212.75] "V" Vector__XXX
 SG_ MtrGnrtr6InvrtrUnswthdSLIVltg : 16|16@1+ (0.05,0) [0|3212.75] "V" Vector__XXX

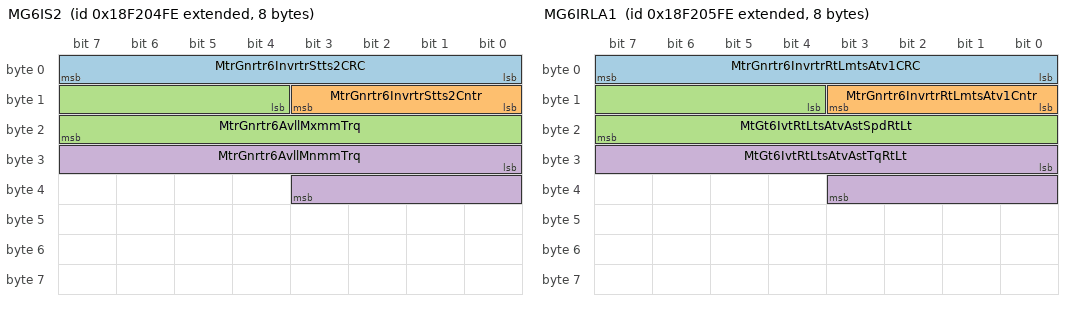
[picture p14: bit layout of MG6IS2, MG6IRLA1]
BO_ 2565997822 MG6IS2: 8 Vector__XXX
 SG_ MtrGnrtr6InvrtrStts2CRC : 0|8@1+ (1,0) [0|255] "count" Vector__XXX
 SG_ MtrGnrtr6InvrtrStts2Cntr : 8|4@1+ (1,0) [0|15] "" Vector__XXX
 SG_ MtrGnrtr6AvllMxmmTrq : 12|12@1+ (42370,-125) [-125|125.9375] "%" Vector__XXX
 SG_ MtrGnrtr6AvllMnmmTrq : 24|12@1+ (42370,-125) [-125|125.9375] "%" Vector__XXX

BO_ 2565998078 MG6IRLA1: 8 Vector__XXX
 SG_ MtrGnrtr6InvrtrRtLmtsAtv1CRC : 0|8@1+ (1,0) [0|255] "count" Vector__XXX
 SG_ MtrGnrtr6InvrtrRtLmtsAtv1Cntr : 8|4@1+ (1,0) [0|15] "" Vector__XXX
 SG_ MtGt6IvtRtLtsAtvAstSpdRtLt : 12|12@1+ (0.25,0) [0|1003.75] "%/s" Vector__XXX
 SG_ MtGt6IvtRtLtsAtvAstTqRtLt : 24|12@1+ (2,0) [0|8030] "%/s" Vector__XXX

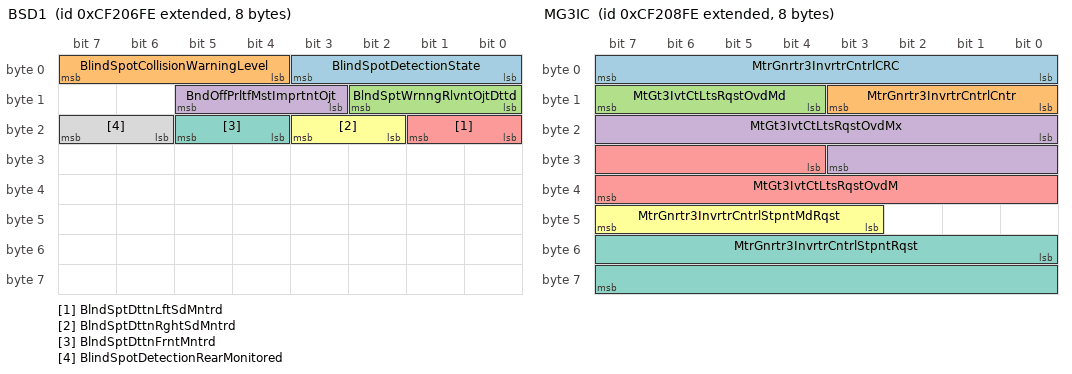
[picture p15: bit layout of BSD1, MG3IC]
BO_ 2364671742 BSD1: 8 Vector__XXX
 SG_ BlindSpotDetectionState : 0|4@1+ (1,0) [0|15] "" Vector__XXX
 SG_ BlindSpotCollisionWarningLevel : 4|4@1+ (1,0) [0|15] "" Vector__XXX
 SG_ BlndSptWrnngRlvntOjtDttd : 8|3@1+ (1,0) [0|7] "" Vector__XXX
 SG_ BndOffPrltfMstImprtntOjt : 11|3@1+ (1,0) [0|7] "" Vector__XXX
 SG_ BlndSptDttnLftSdMntrd : 16|2@1+ (1,0) [0|3] "" Vector__XXX
 SG_ BlndSptDttnRghtSdMntrd : 18|2@1+ (1,0) [0|3] "" Vector__XXX
 SG_ BlndSptDttnFrntMntrd : 20|2@1+ (1,0) [0|3] "" Vector__XXX
 SG_ BlindSpotDetectionRearMonitored : 22|2@1+ (1,0) [0|3] "" Vector__XXX

BO_ 2364671998 WINCH1: 8 Vector__XXX
 SG_ WinchMotorEncoderPosition : 0|16@1+ (1,0) [0|64255] "count" Vector__XXX
 SG_ WinchRevolutionCounter : 16|16@1+ (1,-32128) [-32128|32127] "count" Vector__XXX

BO_ 2364672254 MG3IC: 8 Vector__XXX
 SG_ MtrGnrtr3InvrtrCntrlCRC : 0|8@1+ (1,0) [0|255] "count" Vector__XXX
 SG_ MtrGnrtr3InvrtrCntrlCntr : 8|4@1+ (1,0) [0|15] "" Vector__XXX
 SG_ MtGt3IvtCtLtsRqstOvdMd : 12|4@1+ (1,0) [0|15] "" Vector__XXX
 SG_ MtGt3IvtCtLtsRqstOvdMx : 16|12@1+ (42370,-125) [-125|125.9375] "%" Vector__XXX
 SG_ MtGt3IvtCtLtsRqstOvdM : 28|12@1+ (42370,-125) [-125|125.9375] "%" Vector__XXX
 SG_ MtrGnrtr3InvrtrCntrlStpntMdRqst : 43|5@1+ (1,0) [0|31] "" Vector__XXX
 SG_ MtrGnrtr3InvrtrCntrlStpntRqst : 48|16@1+ (0.00390625,-125) [-125|125.99609375] "%" Vector__XXX

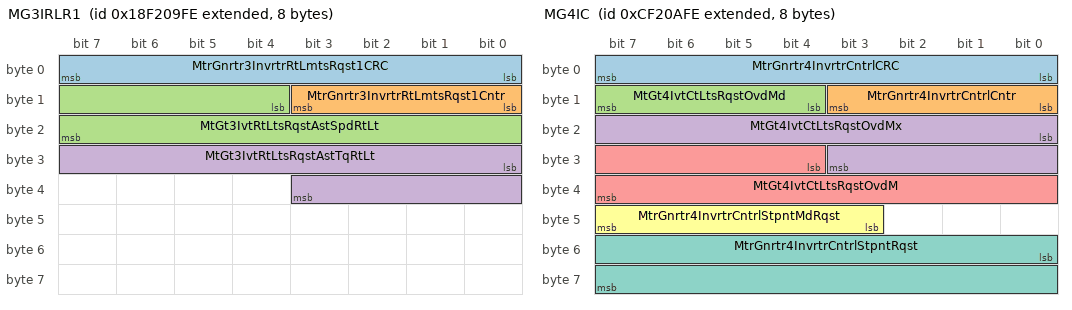
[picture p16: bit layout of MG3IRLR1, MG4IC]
BO_ 2565999102 MG3IRLR1: 8 Vector__XXX
 SG_ MtrGnrtr3InvrtrRtLmtsRqst1CRC : 0|8@1+ (1,0) [0|255] "count" Vector__XXX
 SG_ MtrGnrtr3InvrtrRtLmtsRqst1Cntr : 8|4@1+ (1,0) [0|15] "" Vector__XXX
 SG_ MtGt3IvtRtLtsRqstAstSpdRtLt : 12|12@1+ (0.25,0) [0|1003.75] "%/s" Vector__XXX
 SG_ MtGt3IvtRtLtsRqstAstTqRtLt : 24|12@1+ (2,0) [0|8030] "%/s" Vector__XXX

BO_ 2364672766 MG4IC: 8 Vector__XXX
 SG_ MtrGnrtr4InvrtrCntrlCRC : 0|8@1+ (1,0) [0|255] "count" Vector__XXX
 SG_ MtrGnrtr4InvrtrCntrlCntr : 8|4@1+ (1,0) [0|15] "" Vector__XXX
 SG_ MtGt4IvtCtLtsRqstOvdMd : 12|4@1+ (1,0) [0|15] "" Vector__XXX
 SG_ MtGt4IvtCtLtsRqstOvdMx : 16|12@1+ (42370,-125) [-125|125.9375] "%" Vector__XXX
 SG_ MtGt4IvtCtLtsRqstOvdM : 28|12@1+ (42370,-125) [-125|125.9375] "%" Vector__XXX
 SG_ MtrGnrtr4InvrtrCntrlStpntMdRqst : 43|5@1+ (1,0) [0|31] "" Vector__XXX
 SG_ MtrGnrtr4InvrtrCntrlStpntRqst : 48|16@1+ (0.00390625,-125) [-125|125.99609375] "%" Vector__XXX

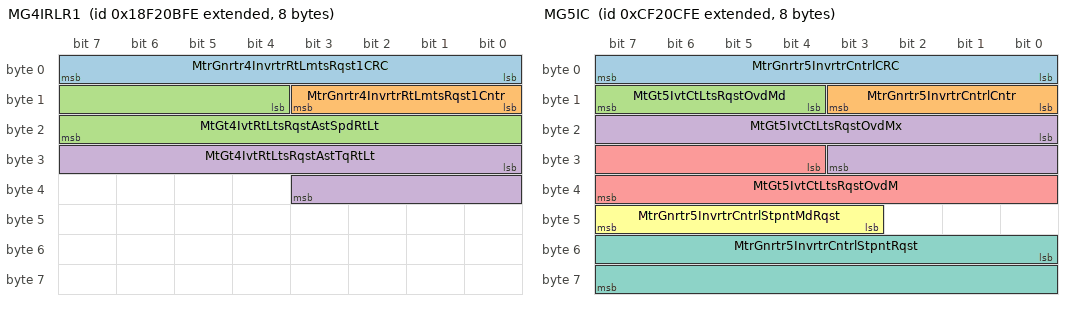
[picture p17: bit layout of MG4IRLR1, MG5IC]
BO_ 2565999614 MG4IRLR1: 8 Vector__XXX
 SG_ MtrGnrtr4InvrtrRtLmtsRqst1CRC : 0|8@1+ (1,0) [0|255] "count" Vector__XXX
 SG_ MtrGnrtr4InvrtrRtLmtsRqst1Cntr : 8|4@1+ (1,0) [0|15] "" Vector__XXX
 SG_ MtGt4IvtRtLtsRqstAstSpdRtLt : 12|12@1+ (0.25,0) [0|1003.75] "%/s" Vector__XXX
 SG_ MtGt4IvtRtLtsRqstAstTqRtLt : 24|12@1+ (2,0) [0|8030] "%/s" Vector__XXX

BO_ 2364673278 MG5IC: 8 Vector__XXX
 SG_ MtrGnrtr5InvrtrCntrlCRC : 0|8@1+ (1,0) [0|255] "count" Vector__XXX
 SG_ MtrGnrtr5InvrtrCntrlCntr : 8|4@1+ (1,0) [0|15] "" Vector__XXX
 SG_ MtGt5IvtCtLtsRqstOvdMd : 12|4@1+ (1,0) [0|15] "" Vector__XXX
 SG_ MtGt5IvtCtLtsRqstOvdMx : 16|12@1+ (42370,-125) [-125|125.9375] "%" Vector__XXX
 SG_ MtGt5IvtCtLtsRqstOvdM : 28|12@1+ (42370,-125) [-125|125.9375] "%" Vector__XXX
 SG_ MtrGnrtr5InvrtrCntrlStpntMdRqst : 43|5@1+ (1,0) [0|31] "" Vector__XXX
 SG_ MtrGnrtr5InvrtrCntrlStpntRqst : 48|16@1+ (0.00390625,-125) [-125|125.99609375] "%" Vector__XXX

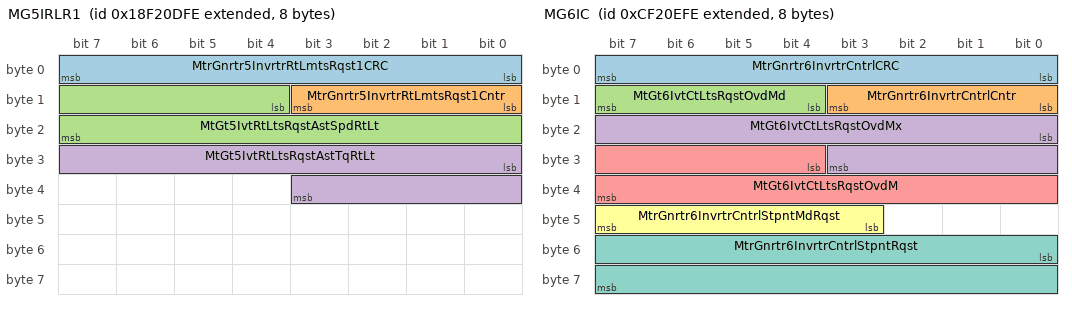
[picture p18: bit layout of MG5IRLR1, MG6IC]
BO_ 2566000126 MG5IRLR1: 8 Vector__XXX
 SG_ MtrGnrtr5InvrtrRtLmtsRqst1CRC : 0|8@1+ (1,0) [0|255] "count" Vector__XXX
 SG_ MtrGnrtr5InvrtrRtLmtsRqst1Cntr : 8|4@1+ (1,0) [0|15] "" Vector__XXX
 SG_ MtGt5IvtRtLtsRqstAstSpdRtLt : 12|12@1+ (0.25,0) [0|1003.75] "%/s" Vector__XXX
 SG_ MtGt5IvtRtLtsRqstAstTqRtLt : 24|12@1+ (2,0) [0|8030] "%/s" Vector__XXX

BO_ 2364673790 MG6IC: 8 Vector__XXX
 SG_ MtrGnrtr6InvrtrCntrlCRC : 0|8@1+ (1,0) [0|255] "count" Vector__XXX
 SG_ MtrGnrtr6InvrtrCntrlCntr : 8|4@1+ (1,0) [0|15] "" Vector__XXX
 SG_ MtGt6IvtCtLtsRqstOvdMd : 12|4@1+ (1,0) [0|15] "" Vector__XXX
 SG_ MtGt6IvtCtLtsRqstOvdMx : 16|12@1+ (42370,-125) [-125|125.9375] "%" Vector__XXX
 SG_ MtGt6IvtCtLtsRqstOvdM : 28|12@1+ (42370,-125) [-125|125.9375] "%" Vector__XXX
 SG_ MtrGnrtr6InvrtrCntrlStpntMdRqst : 43|5@1+ (1,0) [0|31] "" Vector__XXX
 SG_ MtrGnrtr6InvrtrCntrlStpntRqst : 48|16@1+ (0.00390625,-125) [-125|125.99609375] "%" Vector__XXX

BO_ 2566000638 MG6IRLR1: 8 Vector__XXX
 SG_ MtrGnrtr6InvrtrRtLmtsRqst1CRC : 0|8@1+ (1,0) [0|255] "count" Vector__XXX
 SG_ MtrGnrtr6InvrtrRtLmtsRqst1Cntr : 8|4@1+ (1,0) [0|15] "" Vector__XXX
 SG_ MtGt6IvtRtLtsRqstAstSpdRtLt : 12|12@1+ (0.25,0) [0|1003.75] "%/s" Vector__XXX
 SG_ MtGt6IvtRtLtsRqstAstTqRtLt : 24|12@1+ (2,0) [0|8030] "%/s" Vector__XXX

BO_ 2566574078 EVCC1D1: 200 Vector__XXX
 SG_ EVCC1ControlPilotmaximumvoltage : 0|16@1+ (0.05,-1606) [-1606|1606.75] "V" Vector__XXX
 SG_ EVCC1ControlPilotminimumvoltage : 16|16@1+ (0.05,-1606) [-1606|1606.75] "V" Vector__XXX
 SG_ EVCC1ControlPilotPWMfrequency : 32|16@1+ (1,0) [0|64255] "Hz" Vector__XXX
 SG_ EVCC1ControlPilotDutyCycle : 48|8@1+ (0.5,0) [0|125] "%" Vector__XXX
 SG_ EVCC1ControlPilotState : 56|4@1+ (1,0) [0|15] "" Vector__XXX
 SG_ EVCC1ControlPilotSubState : 60|4@1+ (1,0) [0|15] "" Vector__XXX
 SG_ EVCC1Proximitycircuitvoltage : 64|16@1+ (0.01,0) [0|642.55] "V" Vector__XXX
 SG_ EVCC1Inletconnectortemperature : 80|8@1+ (1,-40) [-40|210] "degC" Vector__XXX
 SG_ EVCC1CompatibilityCode : 88|4@1+ (1,0) [0|15] "" Vector__XXX

BO_ 2499465470 CDC2: 8 Vector__XXX
 SG_ Mirror1LeftRightSelection : 0|3@1+ (1,0) [0|7] "" Vector__XXX
 SG_ Mirror2LeftRightSelection : 3|3@1+ (1,0) [0|7] "" Vector__XXX
 SG_ MirrorPrimarySecondarySelection : 8|3@1+ (1,0) [0|7] "" Vector__XXX

BO_ 2499465726 EAI2: 8 Vector__XXX
 SG_ EngnClndrTmprtrAvrg : 0|16@1+ (0.03125,-273) [-273|1734.96875] "degC" Vector__XXX
 SG_ EngnClndrBnk1TmprtrAvrg : 16|16@1+ (0.03125,-273) [-273|1734.96875] "degC" Vector__XXX
 SG_ EngnClndrBnk2TmprtrAvrg : 32|16@1+ (0.03125,-273) [-273|1734.96875] "degC" Vector__XXX

BO_ 2566574846 TCI81: 8 Vector__XXX
 SG_ EngnTrhrgr3OlTmprtr : 0|16@1+ (0.03125,-273) [-273|1734.96875] "degC" Vector__XXX
 SG_ EngnTrhrgr4OlTmprtr : 16|16@1+ (0.03125,-273) [-273|1734.96875] "degC" Vector__XXX
 SG_ EngnTrhrgr5OlTmprtr : 32|16@1+ (0.03125,-273) [-273|1734.96875] "degC" Vector__XXX
 SG_ EngnTrhrgr6OlTmprtr : 48|16@1+ (0.03125,-273) [-273|1734.96875] "degC" Vector__XXX

BO_ 2566575102 ADSC: 8 Vector__XXX
 SG_ TSC1CntrlPrpsP7InhtCmmnd : 0|2@1+ (1,0) [0|3] "" Vector__XXX

BO_ 2566575358 EVSE1ACS2: 8 Vector__XXX
 SG_ EVSE1ACRMSCurrent : 0|16@1+ (0.05,-1600) [-1600|1612.75] "A" Vector__XXX
 SG_ EVSE1ACRMSVoltage : 16|16@1+ (0.05,0) [0|3212.75] "V" Vector__XXX

BO_ 2566575614 EVSE1ACS1: 8 Vector__XXX
 SG_ EVSE1ACRMSCurrentLimit : 0|16@1+ (0.0625,0) [0|4015.9375] "A" Vector__XXX

BO_ 2566575870 EVSE1S1: 8 Vector__XXX
 SG_ EVSE1ConnectorReleaseLatch : 0|2@1+ (1,0) [0|3] "" Vector__XXX
 SG_ EVSE1ManualOverride : 2|2@1+ (1,0) [0|3] "" Vector__XXX
 SG_ EVSE1ConnectorLockState : 4|3@1+ (1,0) [0|7] "" Vector__XXX

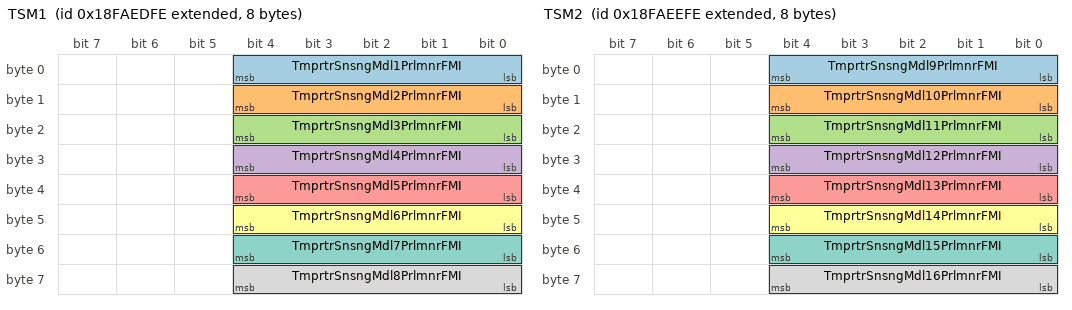
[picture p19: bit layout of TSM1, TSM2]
BO_ 2566581758 TSM1: 8 Vector__XXX
 SG_ TmprtrSnsngMdl1PrlmnrFMI : 0|5@1+ (1,0) [0|31] "binary" Vector__XXX
 SG_ TmprtrSnsngMdl2PrlmnrFMI : 8|5@1+ (1,0) [0|31] "binary" Vector__XXX
 SG_ TmprtrSnsngMdl3PrlmnrFMI : 16|5@1+ (1,0) [0|31] "binary" Vector__XXX
 SG_ TmprtrSnsngMdl4PrlmnrFMI : 24|5@1+ (1,0) [0|31] "binary" Vector__XXX
 SG_ TmprtrSnsngMdl5PrlmnrFMI : 32|5@1+ (1,0) [0|31] "binary" Vector__XXX
 SG_ TmprtrSnsngMdl6PrlmnrFMI : 40|5@1+ (1,0) [0|31] "binary" Vector__XXX
 SG_ TmprtrSnsngMdl7PrlmnrFMI : 48|5@1+ (1,0) [0|31] "binary" Vector__XXX
 SG_ TmprtrSnsngMdl8PrlmnrFMI : 56|5@1+ (1,0) [0|31] "binary" Vector__XXX

BO_ 2566582014 TSM2: 8 Vector__XXX
 SG_ TmprtrSnsngMdl9PrlmnrFMI : 0|5@1+ (1,0) [0|31] "binary" Vector__XXX
 SG_ TmprtrSnsngMdl10PrlmnrFMI : 8|5@1+ (1,0) [0|31] "binary" Vector__XXX
 SG_ TmprtrSnsngMdl11PrlmnrFMI : 16|5@1+ (1,0) [0|31] "binary" Vector__XXX
 SG_ TmprtrSnsngMdl12PrlmnrFMI : 24|5@1+ (1,0) [0|31] "binary" Vector__XXX
 SG_ TmprtrSnsngMdl13PrlmnrFMI : 32|5@1+ (1,0) [0|31] "binary" Vector__XXX
 SG_ TmprtrSnsngMdl14PrlmnrFMI : 40|5@1+ (1,0) [0|31] "binary" Vector__XXX
 SG_ TmprtrSnsngMdl15PrlmnrFMI : 48|5@1+ (1,0) [0|31] "binary" Vector__XXX
 SG_ TmprtrSnsngMdl16PrlmnrFMI : 56|5@1+ (1,0) [0|31] "binary" Vector__XXX

BO_ 2566582270 A2SCRSI3: 8 Vector__XXX
 SG_ Aftrtrtmnt2SCRNrmlzdCnvrsnEffn : 0|8@1+ (0.4,0) [0|100] "%" Vector__XXX

BO_ 2566582526 A1SCRSI3: 8 Vector__XXX
 SG_ Aftrtrtmnt1SCRNrmlzdCnvrsnEffn : 0|8@1+ (0.4,0) [0|100] "%" Vector__XXX

BO_ 2566582782 PSATL: 200 Vector__XXX
 SG_ HrdLftmPrplsnSstmAtvTm : 0|32@1+ (1,0) [0|4211081215] "s" Vector__XXX
 SG_ HrdLftmIdlPrplsnSstmAtvTm : 32|32@1+ (1,0) [0|4211081215] "s" Vector__XXX
 SG_ HrdLftmUrnPrplsnSstmAtvTm : 64|32@1+ (1,0) [0|4211081215] "s" Vector__XXX

BO_ 2566583038 PSATS: 200 Vector__XXX
 SG_ HrdStrd100HrRntPrplsnSstmAtvTm : 0|16@1+ (10,0) [0|642550] "s" Vector__XXX
 SG_ HrdStrd100HrIdlPrplsnSstmAtvTm : 16|16@1+ (10,0) [0|642550] "s" Vector__XXX
 SG_ HrdStrd100HrUrnPrplsnSstmAtvTm : 32|16@1+ (10,0) [0|642550] "s" Vector__XXX

BO_ 2566583294 PSATA: 200 Vector__XXX
 SG_ HrdAtv100HrPrplsnSstmAtvTm : 0|16@1+ (10,0) [0|642550] "s" Vector__XXX
 SG_ HrdAtv100HrIdlPrplsnSstmAtvTm : 16|16@1+ (10,0) [0|642550] "s" Vector__XXX
 SG_ HrdAtv100HrUrnPrplsnSstmAtvTm : 32|16@1+ (10,0) [0|642550] "s" Vector__XXX

BO_ 2566583550 HCDIOL: 200 Vector__XXX
 SG_ HdLtDstTvdCDptOptwtE : 0|32@1+ (5,0) [0|21055406075] "m" Vector__XXX
 SG_ HdLtDstTvdCDptOptwtER : 32|32@1+ (5,0) [0|21055406075] "m" Vector__XXX
 SG_ HdLtDstTvdDvStCIsOpt : 64|32@1+ (5,0) [0|21055406075] "m" Vector__XXX
 SG_ HrdLftmFlCnsmdnChrgDpltngOprtn : 96|32@1+ (0.5,0) [0|2105540607.5] "l" Vector__XXX
 SG_ HdLtFCsdDvStCIsOpt : 128|32@1+ (0.5,0) [0|2105540607.5] "l" Vector__XXX
 SG_ HdLtGdECsdCDptOptwtE : 160|32@1+ (1,0) [0|4211081215] "kWh" Vector__XXX
 SG_ HdLtGdECsdCDptOptwtER : 192|32@1+ (1,0) [0|4211081215] "kWh" Vector__XXX
 SG_ HrdLftmGrdEnrgntthBttr : 224|32@1+ (1,0) [0|4211081215] "kWh" Vector__XXX

BO_ 2566583806 HCDIOS: 200 Vector__XXX
 SG_ HdStd100HDstTvdCDptOptwtE : 0|16@1+ (0.25,0) [0|16063.75] "km" Vector__XXX
 SG_ HdStd100HDstTvdCDptOptwtER : 16|16@1+ (0.25,0) [0|16063.75] "km" Vector__XXX
 SG_ HdStd100HDstTvdDvStCIsOpt : 32|16@1+ (0.25,0) [0|16063.75] "km" Vector__XXX
 SG_ HdStd100HFCsdCDptOpt : 48|16@1+ (0.5,0) [0|32127.5] "l" Vector__XXX
 SG_ HdStd100HFCsdDvStCIsOpt : 64|16@1+ (0.5,0) [0|32127.5] "l" Vector__XXX
 SG_ HdStd100HGdECsdCDptOptwtE : 80|16@1+ (1,0) [0|64255] "kWh" Vector__XXX
 SG_ HdStd100HGdECsdCDptOptwtER : 96|16@1+ (1,0) [0|64255] "kWh" Vector__XXX
 SG_ HrdStrd100HrGrdEnrgntthBttr : 112|16@1+ (1,0) [0|64255] "kWh" Vector__XXX

BO_ 2566584062 HCDIOA: 200 Vector__XXX
 SG_ HdAtv100HDstTvdCDptOptwtE : 0|16@1+ (0.25,0) [0|16063.75] "km" Vector__XXX
 SG_ HdAtv100HDstTvdCDptOptwtER : 16|16@1+ (0.25,0) [0|16063.75] "km" Vector__XXX
 SG_ HdAtv100HDstTvdDvStCIsOpt : 32|16@1+ (0.25,0) [0|16063.75] "km" Vector__XXX
 SG_ HdAtv100HFCsdCDptOpt : 48|16@1+ (0.5,0) [0|32127.5] "l" Vector__XXX
 SG_ HdAtv100HFCsdDvStCIsOpt : 64|16@1+ (0.5,0) [0|32127.5] "l" Vector__XXX
 SG_ HdAtv100HGdECsdCDptOptwtE : 80|16@1+ (1,0) [0|64255] "kWh" Vector__XXX
 SG_ HdAtv100HGdECsdCDptOptwtER : 96|16@1+ (1,0) [0|64255] "kWh" Vector__XXX
 SG_ HrdAtv100HrGrdEnrgntthBttr : 112|16@1+ (1,0) [0|64255] "kWh" Vector__XXX

BO_ 2566584318 AT1HI3: 200 Vector__XXX
 SG_ Atttt1DPFRCptSttEVDst1 : 0|32@1+ (5,0) [0|21055406075] "m" Vector__XXX
 SG_ Atttt1DPFRCptEdEVDst1 : 32|32@1+ (5,0) [0|21055406075] "m" Vector__XXX
 SG_ Atttt1DPFRCptSttEVDst2 : 64|32@1+ (5,0) [0|21055406075] "m" Vector__XXX
 SG_ Atttt1DPFRCptEdEVDst2 : 96|32@1+ (0.125,0) [0|526385151.875] "km" Vector__XXX
 SG_ Atttt1DPFRCptSttEVDst3 : 128|32@1+ (5,0) [0|21055406075] "m" Vector__XXX
 SG_ Atttt1DPFRCptEdEVDst3 : 160|32@1+ (5,0) [0|21055406075] "m" Vector__XXX
 SG_ Atttt1TtERtWtNDEFDv : 192|32@1+ (1,0) [0|4211081215] "s" Vector__XXX
 SG_ Atttt1TtTSCRItBw200Css : 224|32@1+ (1,0) [0|4211081215] "s" Vector__XXX

BO_ 2566584830 ATNXMS2: 8 Vector__XXX
 SG_ Aftrtrtmnt1SCR2InltNOxMssFlw : 0|16@1+ (0.0001,0) [0|6.4255] "g/s" Vector__XXX
 SG_ Aftrtrtmnt1SCR2OtltNOxMssFlw : 16|16@1+ (0.0001,0) [0|6.4255] "g/s" Vector__XXX
 SG_ Aftrtrtmnt1SCR2MdldNH3StrgLvl : 32|16@1+ (1,0) [0|64255] "mg/l" Vector__XXX
 SG_ Aftrtrtmnt1SCR2TrgtNH3StrgLvl : 48|16@1+ (1,0) [0|64255] "mg/l" Vector__XXX

BO_ 2566585086 ATNXMS1: 8 Vector__XXX
 SG_ Atttt1SCR1EExstNOxMssFw : 0|16@1+ (0.0001,0) [0|6.4255] "g/s" Vector__XXX
 SG_ Aftrtrtmnt1SCR1TlppNOxMssFlw : 16|16@1+ (0.0001,0) [0|6.4255] "g/s" Vector__XXX
 SG_ Aftrtrtmnt1SCR1MdldAtlStrgLvl : 32|16@1+ (1,0) [0|64255] "mg/l" Vector__XXX
 SG_ Aftrtrtmnt1SCR1TrgtNH3StrgLvl : 48|16@1+ (1,0) [0|64255] "mg/l" Vector__XXX

BO_ 2566585342 EVAP1: 200 Vector__XXX
 SG_ EVAPSystemPurgePressure : 0|16@1+ (4,0) [0|257] "Pa" Vector__XXX
 SG_ EVAPSystemVaporPressure : 16|16@1+ (4,0) [0|257] "Pa" Vector__XXX
 SG_ EVAPSystemPurgeValveCommand : 32|8@1+ (0.4,0) [0|100] "%" Vector__XXX
 SG_ EVAPSystemPurgeValvePosition : 40|8@1+ (0.4,0) [0|100] "%" Vector__XXX

BO_ 2566585598 GHGTL: 200 Vector__XXX
 SG_ GHGTrkngLftmEngnRnTm : 0|32@1+ (1,0) [0|4211081215] "s" Vector__XXX
 SG_ GHGTrkngLftmVhlDstn : 32|32@1+ (5,0) [0|21055406075] "m" Vector__XXX
 SG_ GHGTrkngLftmVhlFlCnsmptn : 64|32@1+ (0.05,0) [0|210554060.75] "l" Vector__XXX
 SG_ GHGTrkngLftmEngnFlCnsmptn : 96|32@1+ (0.05,0) [0|210554060.75] "l" Vector__XXX
 SG_ GHGTrkngLftmEngnOtptEnrg : 128|32@1+ (1,0) [0|4211081215] "kWh" Vector__XXX
 SG_ GHGTrkngLftmPstvKntEnrgNmrtr : 160|32@1+ (5,0) [0|21055406075] "(km*km)/(h*h)" Vector__XXX
 SG_ GHGTrkngLftmUrnSpdRnTm : 192|32@1+ (1,0) [0|4211081215] "s" Vector__XXX
 SG_ GHGTrackingLifetimeIdleRunTime : 224|32@1+ (1,0) [0|4211081215] "s" Vector__XXX
 SG_ GHGTrkngLftmEngnIdlFlCnsmptn : 256|32@1+ (0.05,0) [0|210554060.75] "l" Vector__XXX
 SG_ GHGTrkngLftmEngnPwrTkOffRnTm : 288|32@1+ (1,0) [0|4211081215] "s" Vector__XXX
 SG_ GHGTLtEPwTOFCspt : 320|32@1+ (0.05,0) [0|210554060.75] "l" Vector__XXX
 SG_ GHGTLtAttEStdwTAtvtCt : 352|16@1+ (1,0) [0|64255] "count" Vector__XXX
 SG_ GHGTrkngLftmStpStrtThnlgRnTm : 384|32@1+ (1,0) [0|4211081215] "s" Vector__XXX

BO_ 2566585854 GHGTS1: 200 Vector__XXX
 SG_ GHGTrkngStrd100HrEngnRnTm : 0|16@1+ (10,0) [0|642550] "s" Vector__XXX
 SG_ GHGTrkngStrd100HrVhlDstn : 16|16@1+ (0.25,0) [0|16063.75] "km" Vector__XXX
 SG_ GHGTrkngStrd100HrVhlFlCnsmptn : 32|16@1+ (0.5,0) [0|32127.5] "l" Vector__XXX
 SG_ GHGTrkngStrd100HrEngnFlCnsmptn : 48|16@1+ (0.5,0) [0|32127.5] "l" Vector__XXX
 SG_ GHGTrkngStrd100HrEngnOtptEnrg : 64|16@1+ (1,0) [0|64255] "kWh" Vector__XXX
 SG_ GHGTStd100HPstvKtENt : 80|32@1+ (1,0) [0|4211081215] "(km*km)/(h*h)" Vector__XXX
 SG_ GHGTrkngStrd100HrUrnSpdRnTm : 112|16@1+ (10,0) [0|642550] "s" Vector__XXX
 SG_ GHGTrkngStrd100HrIdlRnTm : 128|16@1+ (10,0) [0|642550] "s" Vector__XXX
 SG_ GHGTStd100HEIdFCspt : 144|16@1+ (0.5,0) [0|32127.5] "l" Vector__XXX
 SG_ GHGTStd100HEPwTORT : 160|16@1+ (10,0) [0|642550] "s" Vector__XXX
 SG_ GHGTStd100HEPwTOFCspt : 176|16@1+ (0.5,0) [0|32127.5] "l" Vector__XXX
 SG_ GHGTStd100HAttEStdwTAtvtCt : 192|16@1+ (1,0) [0|64255] "count" Vector__XXX
 SG_ GHGTStd100HStpSttTRT : 208|16@1+ (10,0) [0|642550] "s" Vector__XXX

BO_ 2566586110 GHGTA1: 200 Vector__XXX
 SG_ GHGTrkngAtv100HrEngnRnTm : 0|16@1+ (10,0) [0|642550] "s" Vector__XXX
 SG_ GHGTrkngAtv100HrVhlDstn : 16|16@1+ (0.25,0) [0|16063.75] "km" Vector__XXX
 SG_ GHGTrkngAtv100HrVhlFlCnsmptn : 32|16@1+ (0.5,0) [0|32127.5] "l" Vector__XXX
 SG_ GHGTrkngAtv100HrEngnFlCnsmptn : 48|16@1+ (0.5,0) [0|32127.5] "l" Vector__XXX
 SG_ GHGTrkngAtv100HrEngnOtptEnrg : 64|16@1+ (1,0) [0|64255] "kWh" Vector__XXX
 SG_ GHGTAtv100HPstvKtENt : 80|32@1+ (1,0) [0|4211081215] "(km*km)/(h*h)" Vector__XXX
 SG_ GHGTrkngAtv100HrUrnSpdRnTm : 112|16@1+ (10,0) [0|642550] "s" Vector__XXX
 SG_ GHGTrkngAtv100HrIdlRnTm : 128|16@1+ (10,0) [0|642550] "s" Vector__XXX
 SG_ GHGTAtv100HEIdFCspt : 144|16@1+ (0.5,0) [0|32127.5] "l" Vector__XXX
 SG_ GHGTAtv100HEPwTORT : 160|16@1+ (10,0) [0|642550] "s" Vector__XXX
 SG_ GHGTAtv100HEPwTOFCspt : 176|16@1+ (0.5,0) [0|32127.5] "l" Vector__XXX
 SG_ GHGTAtv100HAttEStdwTAtvtCt : 192|16@1+ (1,0) [0|64255] "count" Vector__XXX
 SG_ GHGTAtv100HStpSttTRT : 208|16@1+ (10,0) [0|642550] "s" Vector__XXX

BO_ 2566587134 NTFCEA: 200 Vector__XXX
 SG_ NOxTEAtvtLtFCsptB1Tt : 0|32@1+ (0.05,0) [0|210554060.75] "l" Vector__XXX
 SG_ NOxTEAtvtLtFCsptB2 : 32|32@1+ (0.05,0) [0|210554060.75] "l" Vector__XXX
 SG_ NOxTEAtvtLtFCsptB3 : 64|32@1+ (0.05,0) [0|210554060.75] "l" Vector__XXX
 SG_ NOxTEAtvtLtFCsptB4 : 96|32@1+ (0.05,0) [0|210554060.75] "l" Vector__XXX
 SG_ NOxTEAtvtLtFCsptB5 : 128|32@1+ (0.05,0) [0|210554060.75] "l" Vector__XXX
 SG_ NOxTEAtvtLtFCsptB6 : 160|32@1+ (0.05,0) [0|210554060.75] "l" Vector__XXX
 SG_ NOxTEAtvtLtFCsptB7 : 192|32@1+ (0.05,0) [0|210554060.75] "l" Vector__XXX
 SG_ NOxTEAtvtLtFCsptB8 : 224|32@1+ (0.05,0) [0|210554060.75] "l" Vector__XXX
 SG_ NOxTEAtvtLtFCsptB9 : 256|32@1+ (0.05,0) [0|210554060.75] "l" Vector__XXX
 SG_ NOxTEAtvtLtFCsptB10 : 288|32@1+ (0.05,0) [0|210554060.75] "l" Vector__XXX
 SG_ NOxTEAtvtLtFCsptB11 : 320|32@1+ (0.05,0) [0|210554060.75] "l" Vector__XXX
 SG_ NOxTEAtvtLtFCsptB12 : 352|32@1+ (0.05,0) [0|210554060.75] "l" Vector__XXX
 SG_ NOxTEAtvtLtFCsptB13 : 384|32@1+ (0.05,0) [0|210554060.75] "l" Vector__XXX
 SG_ NOxTEAtvtLtFCsptB14 : 416|32@1+ (0.05,0) [0|210554060.75] "l" Vector__XXX
 SG_ NOxTEAtvtLtFCsptB15NTEBIN : 448|32@1+ (0.05,0) [0|210554060.75] "l" Vector__XXX
 SG_ NOxTEAtvtLtFCsptB16RB : 480|32@1+ (0.05,0) [0|210554060.75] "l" Vector__XXX
 SG_ NOxTEAtvtLtFCsptB17MILOB : 512|32@1+ (0.05,0) [0|210554060.75] "l" Vector__XXX

CM_ BO_ 2364660734 "High Voltage Energy Storage Pack 6 Status 2";
CM_ SG_ 2364660734 HVESP6DshrgPwrLmtDtSttfChrg "HVESP6 Discharge Power Limit Due to State of Charge: Indicates whether or not discharge power of this HVES instance is being limited due to state of charge.This parameter is for one of multiple packs in an HVESS.  If there is only one pack in the sys...";
CM_ SG_ 2364660734 HVESP6DshrgPwrLmtDtBttrTmprtr "HVESP6 Discharge Power Limit Due to Battery Temperature: Indicates whether or not discharge power of this HVES instance is being limited due to battery temperature.This parameter is for one of multiple packs in an HVESS.  If there is only one pack in...";
CM_ SG_ 2364660734 HVESP6DsPwLtDtBttDstCdt "HVESP6 Discharge Power Limit Due to Battery Diagnostic Condition: Indicates whether or not discharge power of this HVES instance is being limited due to a battery diagnostic condition.This parameter is for one of multiple packs in an HVESS.  If there...";
CM_ SG_ 2364660734 HVESP6DshrgPwrLmtDtBttrrCllVltg "HVESP6 Discharge Power Limit Due to Battery or Cell Voltage: Indicates whether or not discharge power of this HVES instance is being limited due to a battery or cell voltage level.This parameter is for one of multiple packs in an HVESS.  If there is ...";
CM_ SG_ 2364660734 HVESP6DshrgPwrLmtDtBttrCrrnt "HVESP6 Discharge Power Limit Due to Battery Current: Indicates whether or not discharge power of this HVES instance is being limited due to battery current.This parameter is for one of multiple packs in an HVESS.  If there is only one pack in the sys...";
CM_ SG_ 2364660734 HVESP6DshrgPwrLmtDtnUndfndCs "HVESP6 Discharge Power Limit Due to an Undefined Cause: Indicates whether or not discharge power of this HVES instance is being limited due to an undefined cause.This parameter is for one of multiple packs in an HVESS.  If there is only one pack in t...";
CM_ SG_ 2364660734 HVESP6ChrgPwrLmtDtSttfChrg "HVESP6 Charge Power Limit Due to State of Charge: Indicates whether or not charge power of this HVES instance is being limited due to state of charge.This parameter is for one of multiple packs in an HVESS.  If there is only one pack in the system, t...";
CM_ SG_ 2364660734 HVESP6ChrgPwrLmtDtBttrTmprtr "HVESP6 Charge Power Limit Due to Battery Temperature: Indicates whether or not charge power of this HVES instance is being limited due to battery temperature.This parameter is for one of multiple packs in an HVESS.  If there is only one pack in the s...";
CM_ SG_ 2364660734 HVESP6CPwLtDtBttDstCdt "HVESP6 Charge Power Limit Due to Battery Diagnostic Condition: Indicates whether or not charge power of this HVES instance is being limited due to a battery diagnostic condition.This parameter is for one of multiple packs in an HVESS.  If there is on...";
CM_ SG_ 2364660734 HVESP6ChrgPwrLmtDtBttrrCllVltg "HVESP6 Charge Power Limit Due to Battery or Cell Voltage: Indicates whether or not charge power of this HVES instance is being limited due to a battery or cell voltage level.This parameter is for one of multiple packs in an HVESS.  If there is only o...";
CM_ SG_ 2364660734 HVESP6ChrgPwrLmtDtBttrCrrnt "HVESP6 Charge Power Limit Due to Battery Current: Indicates whether or not charge power of this HVES instance is being limited due to battery current.This parameter is for one of multiple packs in an HVESS.  If there is only one pack in the system, t...";
CM_ SG_ 2364660734 HVESP6ChrgPwrLmtDtnUndfndCs "HVESP6 Charge Power Limit Due to an Undefined Cause: Indicates whether or not charge power of this HVES instance is being limited due to an undefined cause.This parameter is for one of multiple packs in an HVESS.  If there is only one pack in the sys...";
CM_ BO_ 2364660990 "High Voltage Energy Storage Pack 6 Data 1";
CM_ SG_ 2364660990 HVESP6AvailableDischargePower "HVESP6 Available Discharge Power: The rate at which this High Voltage Energy Storage Pack instance can currently provide energy for propulsion or other uses.This parameter is for one of multiple packs in an HVESS.  If there is only one pack in the sy...";
CM_ SG_ 2364660990 HVESP6AvailableChargePower "HVESP6 Available Charge Power: The rate at which this High Voltage Energy Storage Pack instance can currently receive energy from a regenerative or recharging system.This parameter is for one of multiple packs in an HVESS.  If there is only one pack ...";
CM_ SG_ 2364660990 HVESP6VoltageLevel "HVESP6 Voltage Level: The voltage level of this High Voltage Energy Storage Pack instance. This parameter should be synchronized with SPN 11633 (HVESP6 Current) such that a realized power value can be calculated.  If the HVES component physically con...";
CM_ SG_ 2364660990 HVESP6Current "HVESP6 Current: The current in or out of this High Voltage Energy Storage Pack instance. This parameter should be synchronized with SPN 11632 (HVESP6 Voltage Level) such that a realized power value can be calculated.  This parameter is defined from t...";
CM_ BO_ 2364661246 "High Voltage Energy Storage Pack 6 Data 2";
CM_ SG_ 2364661246 HVESP6FastUpdateStateofCharge "HVESP6 Fast Update State of Charge: Indicates this High Voltage Energy Storage Pack instance state of charge.  0% means no charge remaining, 100% means the system is fully charged in terms of physical limits of this energy storage pack instance.  Acc...";
CM_ SG_ 2364661246 HVESP6HighestCellVoltage "HVESP6 Highest Cell Voltage: The highest voltage level reported by any cell in this High Voltage Energy Storage Pack instance. If a single voltage sensor covers more than one cell, the value in this parameter is for the smallest group of cells measur...";
CM_ SG_ 2364661246 HVESP6LowestCellVoltage "HVESP6 Lowest Cell Voltage: The lowest voltage level reported by any cell in this High Voltage Energy Storage Pack instance. If a single voltage sensor covers more than one cell, the value in this parameter is for the smallest group of cells measured...";
CM_ SG_ 2364661246 HVESP6CllVltgDffrntlStts "HVESP6 Cell Voltage Differential Status: Indicates whether or not the differential between the highest and lowest cell voltages are within acceptable limits, according to this High Voltage Energy Storage Pack instance. The actual voltage differential...";
CM_ BO_ 2364661502 "High Voltage Energy Storage Pack 6 Data 3";
CM_ SG_ 2364661502 HVESP6HighestCellTemperature "HVESP6 Highest Cell Temperature: The highest temperature level reported by any cell in this High Voltage Energy Storage Pack instance.  If a single temperature sensor covers more than one cell, the value in this parameter is for the smallest group of...";
CM_ SG_ 2364661502 HVESP6LowestCellTemperature "HVESP6 Lowest Cell Temperature: The lowest temperature level reported by any cell in this High Voltage Energy Storage Pack instance.  If a single temperature sensor covers more than one cell, the value in this parameter is for the smallest group of c...";
CM_ SG_ 2364661502 HVESP6AverageCellTemperature "HVESP6 Average Cell Temperature: The average temperature level of all cells in this High Voltage Energy Storage Pack instance.This parameter is for one of multiple packs in an HVESS.  If there is only one pack in the system, the HVESS parameters shou...";
CM_ SG_ 2364661502 HVESP6CllTmprtrDffrntlStts "HVESP6 Cell Temperature Differential Status: Indicates whether or not the differential between the highest and lowest cell temperatures are within acceptable limits per this High Voltage Energy Storage Pack instance.  The actual temperature different...";
CM_ BO_ 2364661758 "High Voltage Energy Storage Pack 6 Data 4";
CM_ SG_ 2364661758 HVESP6DischargeCapacity "HVESP6 Discharge Capacity: The amount of stored electrical charge in this High Voltage Energy Storage Pack instance that is available for use by the hybrid system, i.e. “how full is the tank”.  See SPN 11670 (HVESP6 Discharge Energy Capacity) for kil...";
CM_ SG_ 2364661758 HVESP6ChargeCapacity "HVESP6 Charge Capacity: The amount of unused electrical charge storage in this High Voltage Energy Storage Pack instance that is available to be filled by charging, i.e. “how much empty space is remaining in the tank”.  See SPN 11671 (HVESP6 Charge E...";
CM_ SG_ 2364661758 HVESP6CellBalancingCount "HVESP6 Cell Balancing Count: The number of cells that are currently being balanced in this High Voltage Energy Storage Pack instance.This parameter is for one of multiple packs in an HVESS.  If there is only one pack in the system, the HVESS paramete...";
CM_ BO_ 2364662014 "High Voltage Energy Storage Pack 6 Data 5";
CM_ SG_ 2364662014 HVESP6DischargeCurrentLimit "HVESP6 Discharge Current Limit: The maximum permissible current flow out of this High Voltage Energy Storage Pack instance. This parameter is defined from the high voltage energy storage pack's point of view.A negative value represents current flowin...";
CM_ SG_ 2364662014 HVESP6ChargeCurrentLimit "HVESP6 Charge Current Limit: The maximum permissible current flow into this High Voltage Energy Storage Pack instance. This parameter is defined from the high voltage energy storage pack's point of view.A positive value represents current flowing int...";
CM_ SG_ 2364662014 HVESP6LowestCellStateofCharge "HVESP6 Lowest Cell State of Charge: Indicates the state of charge of the lowest-charged cell in this High Voltage Energy Storage Pack instance.  0% means no charge remaining, 100% means the cell is fully charged.   If a single state of charge value c...";
CM_ SG_ 2364662014 HVESP6HighestCellStateofCharge "HVESP6 Highest Cell State of Charge: Indicates the state of charge of the highest-charged cell in this High Voltage Energy Storage Pack instance.  0% means no charge remaining, 100% means the cell is fully charged.  If a single state of charge value ...";
CM_ BO_ 2364662270 "High Voltage Energy Storage Pack 6 Data 6";
CM_ SG_ 2364662270 HVESP6BusVoltage "HVESP6 Bus Voltage: The voltage level of the high voltage bus, as measured by this High Voltage Energy Storage Pack instance on the bus side (not the battery side) of its contactors.This parameter is for one of multiple packs in an HVESS.  If there i...";
CM_ SG_ 2364662270 HVESP6IgnitionVoltage "HVESP6 Ignition Voltage: The voltage level at the ignition input of this High Voltage Energy Storage Pack controller.This parameter is for one of multiple packs in an HVESS.  If there is only one pack in the system, the HVESS parameters should be use...";
CM_ SG_ 2364662270 HVESP6IntakeCoolantTemperature "HVESP6 Intake Coolant Temperature: The temperature of liquid coolant as it enters this High Voltage Energy Storage Pack instance.This parameter is for one of multiple packs in an HVESS.  If there is only one pack in the system, the HVESS parameters s...";
CM_ SG_ 2364662270 HVESP6OutletCoolantTemperature "HVESP6 Outlet Coolant Temperature: The temperature of liquid coolant as it exits this High Voltage Energy Storage Pack instance.This parameter is for one of multiple packs in an HVESS.  If there is only one pack in the system, the HVESS parameters sh...";
CM_ SG_ 2364662270 HVESP6ElectronicsTemperature "HVESP6 Electronics Temperature: The temperature of the electronics or control modules in this High Voltage Energy Storage Pack instance.  If there are multiple temperature sensors then this parameter would be set to the maximum sensor reading.This pa...";
CM_ SG_ 2364662270 HVESP6Temperature "HVESP6 Temperature: The temperature of this High Voltage Energy Storage Pack instance. The value may be determined from a unique sensor specifically for this purpose, or by aggregating various temperature sensor readings within the pack.This paramete...";
CM_ BO_ 2364662526 "High Voltage Energy Storage Pack 6 Status 1";
CM_ SG_ 2364662526 HVESP6HghVltgBsPstvCnttrStt "HVESP6 High-Voltage Bus (Positive) Contactor State: Position of this High Voltage Energy Storage Pack instance positive side bus contactor.  When this contactor is closed, the positive side of this HVES instance is connected to the positive side of t...";
CM_ SG_ 2364662526 HVESP6HghVltgBsNgtvCnttrStt "HVESP6 High-Voltage Bus (Negative) Contactor State: Position of this High Voltage Energy Storage Pack instance negative side bus contactor.  When this contactor is closed, the negative side of this HVES instance is connected to the negative side of t...";
CM_ SG_ 2364662526 HVESP6HghVltgBsDsnntFrwrnng "HVESP6 High-Voltage Bus Disconnect Forewarning: Indicates that this High Voltage Energy Storage Pack instance is about to disconnect from the high voltage bus due to unacceptable conditions.This parameter is for one of multiple packs in an HVESS. If ...";
CM_ SG_ 2364662526 HVESP6HghVltgBsPrChrgRlStt "HVESP6 High-Voltage Bus Pre-Charge Relay State: Position of the high-voltage bus contactor pre-charge relay.  When this relay is closed, this High Voltage Energy Storage Pack instance is bringing the high-voltage bus up to its operating level.This pa...";
CM_ SG_ 2364662526 HVESP6CntrfPkCnttrStt "HVESP6 Center of Pack Contactor State: Position of the center high-voltage contactor.  When this contactor is closed, the positive half of this High Voltage Energy Storage Pack instance is connected to the negative half.  If a system controls the pos...";
CM_ SG_ 2364662526 HVESP6HghVltgBsAtvIsltnTstStts "HVESP6 High-Voltage Bus Active Isolation Test Status: Status of the high-voltage bus electrical active isolation test as performed by this High Voltage Energy Storage Pack instance.This parameter is for one of multiple packs in an HVESS. If there is ...";
CM_ SG_ 2364662526 HVESP6HghVltgBsPssvIsltnTstStts "HVESP6 High-Voltage Bus Passive Isolation Test Status: Status of the high-voltage bus electrical passive isolation test as performed by this High Voltage Energy Storage Pack instance.This parameter is for one of multiple packs in an HVESS. If there i...";
CM_ SG_ 2364662526 HVESP6HVILStatus "HVESP6 HVIL Status: Status of the High Voltage Interlock Loop from the viewpoint of this High Voltage Energy Storage Pack instance.This parameter is for one of multiple packs in an HVESS. If there is only one pack in the system, the HVESS parameters ...";
CM_ SG_ 2364662526 HVESP6InertiaSwitchStatus "HVESP6 Inertia Switch Status: Switch indicating that an impact has been sensed by this High Voltage Energy Storage Pack instance. The impact indication may require action by another controller, or by this HVES instance itself.  For example, a control...";
CM_ SG_ 2364662526 HVESP6StateofChargeStatus "HVESP6 State of Charge Status: Status of this High Voltage Energy Storage Pack instance State of Charge (SOC).  Note:  A given HVES controller may not support all of the states.This parameter is for one of multiple packs in an HVESS.  If there is onl...";
CM_ SG_ 2364662526 HVESP6CellBalanceStatus "HVESP6 Cell Balance Status: Indicates whether or not the cells in this High Voltage Energy Storage Pack instance are balanced.This parameter is for one of multiple packs in an HVESS.  If there is only one pack in the system, the HVESS parameters shou...";
CM_ SG_ 2364662526 HVESP6CellBalancingActive "HVESP6 Cell Balancing Active: Indicates whether or not the cells in this High Voltage Energy Storage Pack instance are currently being balanced.This parameter is for one of multiple packs in an HVESS.  If there is only one pack in the system, the HVE...";
CM_ SG_ 2364662526 HVESP6InternalChargerStatus "HVESP6 Internal Charger Status: Indicates that the charger in this HVES instance is on.  External chargers may use the External Energy Source Connection Status (SPN 7898) and related SPs.This parameter is for one of multiple packs in an HVESS. If the...";
CM_ SG_ 2364662526 HVESP6HghVltgBsCnntnStts "HVESP6 High-Voltage Bus Connection Status: This parameter provides high level feedback on this High Voltage Energy Storage Pack instance high voltage bus connection.  For specific contactor information, see SPN 11655 (HVESP6 High-Voltage Bus (Positiv...";
CM_ SG_ 2364662526 HVESP6OperationalStatus "HVESP6 Operational Status: Provides feedback on where this High Voltage Energy Storage Pack instance is in its operating spectrum, and includes feedback in response to the Operation Consent [i.e. SPN 11615 (HVESP6 Operation Consent)] and Power Down C...";
CM_ BO_ 2364662782 "High Voltage Energy Storage Pack 6 Data 7";
CM_ SG_ 2364662782 HVESP6DischargeEnergyCapacity "HVESP6 Discharge Energy Capacity: The amount of stored electrical energy in this High Voltage Energy Storage Pack instance that is available for use by the hybrid system, i.e. “how full is the tank”.  See SPN 11642 (HVESP6 Discharge Capacity) for Amp...";
CM_ SG_ 2364662782 HVESP6ChargeEnergyCapacity "HVESP6 Charge Energy Capacity: The amount of unused electrical energy storage available to be filled by charging this High Voltage Energy Storage Pack instance, i.e. “how much empty space is remaining in the tank”.  See SPN 11643 (HVESP6 Charge Capac...";
CM_ SG_ 2364662782 HVESP6MaximumChargeVoltageLimit "HVESP6 Maximum Charge Voltage Limit: The maximum voltage level not to be exceeded while charging this High Voltage Energy Storage Pack instance.  If this parameter is not supported, the maximum charge voltage should be limited to SPN 11714 (HVESP6 Re...";
CM_ BO_ 2364663038 "High Voltage Energy Storage Pack 6 Module Status 1";
CM_ SG_ 2364663038 HVESP6Module1OperationalStatus "HVESP6 Module 1 Operational Status: Operational Status of Module 1 in this High Voltage Energy Storage Pack Instance.  Not Operational is used when the module is initializing or not able to function (e.g. internal module level monitors have failed). ...";
CM_ SG_ 2364663038 HVESP6Module2OperationalStatus "HVESP6 Module 2 Operational Status: Operational Status of Module 2 in this High Voltage Energy Storage Pack Instance.  Not Operational is used when the module is initializing or not able to function (e.g. internal module level monitors have failed). ...";
CM_ SG_ 2364663038 HVESP6Module3OperationalStatus "HVESP6 Module 3 Operational Status: Operational Status of Module 3 in this High Voltage Energy Storage Pack Instance.  Not Operational is used when the module is initializing or not able to function (e.g. internal module level monitors have failed). ...";
CM_ SG_ 2364663038 HVESP6Module4OperationalStatus "HVESP6 Module 4 Operational Status: Operational Status of Module 4 in this High Voltage Energy Storage Pack Instance.  Not Operational is used when the module is initializing or not able to function (e.g. internal module level monitors have failed). ...";
CM_ SG_ 2364663038 HVESP6Module5OperationalStatus "HVESP6 Module 5 Operational Status: Operational Status of Module 5 in this High Voltage Energy Storage Pack Instance.  Not Operational is used when the module is initializing or not able to function (e.g. internal module level monitors have failed). ...";
CM_ SG_ 2364663038 HVESP6Module6OperationalStatus "HVESP6 Module 6 Operational Status: Operational Status of Module 6 in this High Voltage Energy Storage Pack Instance.  Not Operational is used when the module is initializing or not able to function (e.g. internal module level monitors have failed). ...";
CM_ SG_ 2364663038 HVESP6Module7OperationalStatus "HVESP6 Module 7 Operational Status: Operational Status of Module 7 in this High Voltage Energy Storage Pack Instance.  Not Operational is used when the module is initializing or not able to function (e.g. internal module level monitors have failed). ...";
CM_ SG_ 2364663038 HVESP6Module8OperationalStatus "HVESP6 Module 8 Operational Status: Operational Status of Module 8 in this High Voltage Energy Storage Pack Instance.  Not Operational is used when the module is initializing or not able to function (e.g. internal module level monitors have failed). ...";
CM_ SG_ 2364663038 HVESP6Module9OperationalStatus "HVESP6 Module 9 Operational Status: Operational Status of Module 9 in this High Voltage Energy Storage Pack Instance.  Not Operational is used when the module is initializing or not able to function (e.g. internal module level monitors have failed). ...";
CM_ SG_ 2364663038 HVESP6Module10OperationalStatus "HVESP6 Module 10 Operational Status: Operational Status of Module 10 in this High Voltage Energy Storage Pack Instance.  Not Operational is used when the module is initializing or not able to function (e.g. internal module level monitors have failed)...";
CM_ SG_ 2364663038 HVESP6Module11OperationalStatus "HVESP6 Module 11 Operational Status: Operational Status of Module 11 in this High Voltage Energy Storage Pack Instance.  Not Operational is used when the module is initializing or not able to function (e.g. internal module level monitors have failed)...";
CM_ SG_ 2364663038 HVESP6Module12OperationalStatus "HVESP6 Module 12 Operational Status: Operational Status of Module 12 in this High Voltage Energy Storage Pack Instance.  Not Operational is used when the module is initializing or not able to function (e.g. internal module level monitors have failed)...";
CM_ SG_ 2364663038 HVESP6Module13OperationalStatus "HVESP6 Module 13 Operational Status: Operational Status of Module 13 in this High Voltage Energy Storage Pack Instance.  Not Operational is used when the module is initializing or not able to function (e.g. internal module level monitors have failed)...";
CM_ SG_ 2364663038 HVESP6Module14OperationalStatus "HVESP6 Module 14 Operational Status: Operational Status of Module 14 in this High Voltage Energy Storage Pack Instance.  Not Operational is used when the module is initializing or not able to function (e.g. internal module level monitors have failed)...";
CM_ SG_ 2364663038 HVESP6Module15OperationalStatus "HVESP6 Module 15 Operational Status: Operational Status of Module 15 in this High Voltage Energy Storage Pack Instance.  Not Operational is used when the module is initializing or not able to function (e.g. internal module level monitors have failed)...";
CM_ SG_ 2364663038 HVESP6Module16OperationalStatus "HVESP6 Module 16 Operational Status: Operational Status of Module 16 in this High Voltage Energy Storage Pack Instance.  Not Operational is used when the module is initializing or not able to function (e.g. internal module level monitors have failed)...";
CM_ BO_ 2364663294 "High Voltage Energy Storage Pack 6 Thermal Management System Status 1";
CM_ SG_ 2364663294 HVESP6ThrmlMngmntSstmSLIInptPwr "HVESP6 Thermal Management System SLI Input Power: This is the low-voltage power consumed by this HVES Thermal Management System (TMS).This parameter is for one of multiple packs in an HVESS.  If there is only one pack in the system, the HVESS paramet...";
CM_ SG_ 2364663294 HVESP6TMtSstHVtIptPw "HVESP6 Thermal Management System High-Voltage Input Power: This is the high-voltage power consumed by this HVES Thermal Management System (TMS).This parameter is for one of multiple packs in an HVESS.  If there is only one pack in the system, the HVE...";
CM_ SG_ 2364663294 HVESP6ThrmlMngmntSstmCmprssrSpd "HVESP6 Thermal Management System Compressor Speed: When this High Voltage Energy Storage Pack Thermal Management System is equipped with an active cooling system (e.g. air conditioner), this is the Compressor Speed.This parameter is for one of multip...";
CM_ SG_ 2364663294 HVESP6ThrmlMngmntSstmRltvHmdt "HVESP6 Thermal Management System Relative Humidty: When this High Voltage Energy Storage Pack Thermal Management System is equipped with a relative humidity sensor, this is the  measured Relative Humidity.This parameter is for one of multiple packs i...";
CM_ SG_ 2364663294 HVESP6ThrmlMngmntSstmHtrStts "HVESP6 Thermal Management System Heater Status: The state of this High Voltage Energy Storage Pack heaterThis parameter is for one of multiple packs in an HVESS.  If there is only one pack in the system, the HVESS parameters should be used. If there ...";
CM_ SG_ 2364663294 HVESP6ThrmlMngmntSstmHVILStts "HVESP6 Thermal Management System HVIL Status: In multiple HVES configurations, this is the status of the High Voltage Interlock Loop from the viewpoint of this Thermal Management System.00b = HVIL Closed01b = HVIL Open10b = Error11b = Not AvailableTh...";
CM_ SG_ 2364663294 HVESP6ThrmlMngmntSstmMd "HVESP6 Thermal Management System Mode: Indicates the operating mode of the Thermal Management System.  The heat transfer medium may be (e.g. liquid or air).  The cooling system may be fans, liquid coolant, or a combination of mediums.  The system may...";
CM_ SG_ 2364663294 HVESP6ThrmlMngmntSstmClntLvl "HVESP6 Thermal Management System Coolant Level: Indicates the coolant level in this HVES Thermal Management System (TMS).This parameter is for one of multiple packs in an HVESS.  If there is only one pack in the system, the HVESS parameters should be...";
CM_ BO_ 2364663550 "High Voltage Energy Storage Pack 6 Data 8";
CM_ SG_ 2364663550 HVESP6HghstCllVltgMdlNmr "HVESP6 Highest Cell Voltage Module Number: Identifies the location of the module containing SPN 11635 (HVESP6 Highest Cell Voltage).This parameter is for one of multiple packs in an HVESS.  If there is only one pack in the system, the HVESS parameter...";
CM_ SG_ 2364663550 HVESP6HghstCllVltgCllNmr "HVESP6 Highest Cell Voltage Cell Number: Identifies the location of SPN 11635 (HVESP6 Highest Cell Voltage) within SPN 11695 (HVESP6 Highest Cell Voltage Module Number).This parameter is for one of multiple packs in an HVESS.  If there is only one pa...";
CM_ SG_ 2364663550 HVESP6LwstCllVltgMdlNmr "HVESP6 Lowest Cell Voltage Module Number: Identifies the location of the module containing SPN 11636 (HVESP6 Lowest Cell Voltage).This parameter is for one of multiple packs in an HVESS.  If there is only one pack in the system, the HVESS parameters ...";
CM_ SG_ 2364663550 HVESP6LwstCllVltgCllNmr "HVESP6 Lowest Cell Voltage Cell Number: Identifies the location of SPN 11636 (HVESP6 Lowest Cell Voltage) within SPN 11697 (HVESP6 Lowest Cell Voltage Module Number).This parameter is for one of multiple packs in an HVESS.  If there is only one pack ...";
CM_ SG_ 2364663550 HVESP6AverageCellVoltage "HVESP6 Average Cell Voltage: The average cell voltage in this High Voltage Energy Storage Pack instance.This parameter is for one of multiple packs in an HVESS.  If there is only one pack in the system, the HVESS parameters should be used. If there a...";
CM_ BO_ 2364663806 "High Voltage Energy Storage Pack 6 Data 9";
CM_ SG_ 2364663806 HVESP6HghstCllTmprtrMdlNmr "HVESP6 Highest Cell Temperature Module Number: Identifies the location of the module containing SPN 11638 (HVESP6 Highest Cell Temperature).This parameter is for one of multiple packs in an HVESS.  If there is only one pack in the system, the HVESS p...";
CM_ SG_ 2364663806 HVESP6HghstCllTmprtrCllNmr "HVESP6 Highest Cell Temperature Cell Number: Identifies the location of SPN 11638 (HVESP6 Highest Cell Temperature) within SPN 11700 (HVESP6 Highest Cell Temperature Module Number).This parameter is for one of multiple packs in an HVESS.  If there is...";
CM_ SG_ 2364663806 HVESP6LwstCllTmprtrMdlNmr "HVESP6 Lowest Cell Temperature Module Number: Identifies the location of the module containing SPN 11639 (HVESP6 Lowest Cell Temperature).This parameter is for one of multiple packs in an HVESS.  If there is only one pack in the system, the HVESS par...";
CM_ SG_ 2364663806 HVESP6LwstCllTmprtrCllNmr "HVESP6 Lowest Cell Temperature Cell Number: Identifies the location of SPN 11639 (HVESP6 Lowest Cell Temperature) within SPN 11702 (HVESP6 Lowest Cell Temperature Module Number).This parameter is for one of multiple packs in an HVESS.  If there is on...";
CM_ BO_ 2364664062 "High Voltage Energy Storage Pack 6 Data 10";
CM_ SG_ 2364664062 HVESP6HghstCllSttfChrgMdlNmr "HVESP6 Highest Cell State of Charge Module Number: Identifies the location of the module containing SPN 11648 (HVESP6 Highest Cell State of Charge).This parameter is for one of multiple packs in an HVESS.  If there is only one pack in the system, the...";
CM_ SG_ 2364664062 HVESP6HghstCllSttfChrgCllNmr "HVESP6 Highest Cell State of Charge Cell Number: Identifies the location of SPN 11648 (HVESP6 Highest Cell State of Charge) within SPN 11704 (HVESP6 Highest Cell State of Charge Module Number).This parameter is for one of multiple packs in an HVESS. ...";
CM_ SG_ 2364664062 HVESP6LwstCllSttfChrgMdlNmr "HVESP6 Lowest Cell State of Charge Module Number: Identifies the location of the module containing SPN 11647 (HVESP6 Lowest Cell State of Charge).This parameter is for one of multiple packs in an HVESS.  If there is only one pack in the system, the H...";
CM_ SG_ 2364664062 HVESP6LwstCllSttfChrgCllNmr "HVESP6 Lowest Cell State of Charge Cell Number: Identifies the location of SPN 11647 (HVESP6 Lowest Cell State of Charge) within SPN 11706 (HVESP6 Lowest Cell State of Charge Module Number).This parameter is for one of multiple packs in an HVESS.  If...";
CM_ SG_ 2364664062 HVESP6HghVltgBsAtvIsltnTstRslts "HVESP6 High-Voltage Bus Active Isolation Test Results: The isolation resistance expressed in Ohms per Volt that resulted from the High-Voltage Bus Active Isolation Test.See SPN 11660 (HVESP6 High-Voltage Bus Active Isolation Test Status) for test sta...";
CM_ SG_ 2364664062 HVESP6HVtBsPssvIstTstRsts "HVESP6 High-Voltage Bus Passive Isolation Test Results: The isolation resistance expressed in Ohms per Volt that resulted from the High-Voltage Bus Passive Isolation Test.See SPN 11661 (HVESP6 High-Voltage Bus Passive Isolation Test Status) for test ...";
CM_ BO_ 2364664318 "High Voltage Energy Storage Pack 6 Data 11";
CM_ SG_ 2364664318 HVESP6BsVltgNgtvtChsssGrndVltg "HVESP6 Bus Voltage Negative to Chassis Ground Voltage: Voltage difference between the most negative terminal of the HVES battery and chassis measured on the hybrid system bus side (not the battery side) of any HVES contained output contactor.  This v...";
CM_ SG_ 2364664318 HVESP6VltgLvlNgtvtChsssGrndVltg "HVESP6 Voltage Level Negative to Chassis Ground Voltage: Voltage difference between the most negative terminal of the HVES battery and chassis measured at the battery side of any HVES contained output contactor.  This voltage may be used for system l...";
CM_ BO_ 2364664574 "Motor/Generator 3 Inverter Mode Feedback 1";
CM_ SG_ 2364664574 MtrGnrtr3InvrtrMdFdk1CRC "Motor/Generator 3 Inverter Mode Feedback 1 CRC: The CRC is defined as follows: • Length: 8 bits • Polynomial: x^8+x^5+x^3+x^2+x+1 • Initial Value: FFh • Input Data Reflection: Not reflected • Result Data Reflection: Not reflected • XOR value: FFhSAE ...";
CM_ SG_ 2364664574 MtrGnrtr3InvrtrMdFdk1Cntr "Motor/Generator 3 Inverter Mode Feedback 1 Counter: The message counter is used to detect situations where the transmitting ECU malfunction repeats the same frame all the time. The receiver of the information may use the counter parameter to detect t...";
CM_ SG_ 2364664574 MtrGnrtr3InvrtrCntrlLmtsOvrrdMd "Motor/Generator 3 Inverter Control Limits Override Mode: During normal operation this will have the same value as SPN 11810 [Control Limits Request Override Mode].  0 = Operating limits are not overridden.  If a limit was previously active, then it h...";
CM_ SG_ 2364664574 MtrGnrtr3InvrtrCntrlStpntMd "Motor/Generator 3 Inverter Control Setpoint Mode: Reports the inverter mode (See SPN 11813 [Control Setpoint Mode Request] for requested mode).Passive modes:  0 = Powered On - the inverter is commanded to be powered on and able to communicate, but th...";
CM_ SG_ 2364664574 MtrGnrtr3InvrtrHVILStts "Motor/Generator 3 Inverter HVIL Status: Reports the High Voltage Interlock Loop (HVIL) state.00b = HVIL Closed01b = HVIL Open10b = Error11b = Not Available";
CM_ BO_ 2565991422 "Motor/Generator 3 Inverter Limits Active Power";
CM_ SG_ 2565991422 MtrGnrtr3InvrtrLmtsAtvPwrCRC "Motor/Generator 3 Inverter Limits Active Power CRC: The CRC is defined as follows: • Length: 8 bits • Polynomial: x^8+x^5+x^3+x^2+x+1 • Initial Value: FFh • Input Data Reflection: Not reflected • Result Data Reflection: Not reflected • XOR value: FFh...";
CM_ SG_ 2565991422 MtrGnrtr3InvrtrLmtsAtvPwrCntr "Motor/Generator 3 Inverter Limits Active Power Counter: The message counter is used to detect situations where the transmitting ECU malfunction repeats the same frame all the time. The receiver of the information may use the counter parameter to dete...";
CM_ SG_ 2565991422 MtGt3IvtLtsAtvMPwMx "Motor/Generator 3 Inverter Limits Active Mechanical Power Maximum: The inverter keeps the mechanical motor power below this value.   This limit may be set in response to a Limits Request or determined by the inverter based on operating conditions.Ref...";
CM_ SG_ 2565991422 MtGt3IvtLtsAtvMPwM "Motor/Generator 3 Inverter Limits Active Mechanical Power Minimum: The inverter keeps the mechanical motor power above this value.   This limit may be set in response to a Limits Request or determined by the inverter based on operating conditions.Ref...";
CM_ SG_ 2565991422 MtGt3IvtLtsAtvDCSdPwMx "Motor/Generator 3 Inverter Limits Active DC Side Power Maximum: The inverter keeps the DC Side power below this value.   This limit may be set in response to a Limits Request or determined by the inverter based on operating conditions.Refer to SPN 11...";
CM_ SG_ 2565991422 MtGt3IvtLtsAtvDCSdPwM "Motor/Generator 3 Inverter Limits Active DC Side Power Minimum: The inverter keeps the DC side power above this value.   This limit may be set in response to a Limits Request or determined by the inverter based on operating conditions.Refer to SPN 11...";
CM_ BO_ 2565991678 "Motor/Generator 3 Inverter Limits Active Mechanical";
CM_ SG_ 2565991678 MtrGnrtr3InvrtrLmtsAtvMhnlCRC "Motor/Generator 3 Inverter Limits Active Mechanical CRC: The CRC is defined as follows: • Length: 8 bits • Polynomial: x^8+x^5+x^3+x^2+x+1 • Initial Value: FFh • Input Data Reflection: Not reflected • Result Data Reflection: Not reflected • XOR value...";
CM_ SG_ 2565991678 MtrGnrtr3InvrtrLmtsAtvMhnlCntr "Motor/Generator 3 Inverter Limits Active Mechanical Counter: The message counter is used to detect situations where the transmitting ECU malfunction repeats the same frame all the time. The receiver of the information may use the counter parameter to...";
CM_ SG_ 2565991678 MtrGnrtr3InvrtrLmtsAtvTrqMxmm "Motor/Generator 3 Inverter Limits Active Torque Maximum: The inverter keeps the motor torque below this value.  This limit may be set in response to a Limits Request or determined by the inverter based on operating conditions.Refer to SPN 11821 [Refe...";
CM_ SG_ 2565991678 MtrGnrtr3InvrtrLmtsAtvTrqMnmm "Motor/Generator 3 Inverter Limits Active Torque Minimum: The inverter keeps the motor torque above this value.  This limit may be set in response to a Limits Request or determined by the inverter based on operating conditions.Refer to SPN 11821 [Refe...";
CM_ SG_ 2565991678 MtrGnrtr3InvrtrLmtsAtvSpdMxmm "Motor/Generator 3 Inverter Limits Active Speed Maximum: The inverter keeps the motor speed below this value.  This limit may be set in response to a Limits Request or determined by the inverter based on operating conditions.Refer to SPN 11822 [Refere...";
CM_ SG_ 2565991678 MtrGnrtr3InvrtrLmtsAtvSpdMnmm "Motor/Generator 3 Inverter Limits Active Speed Minimum: The inverter keeps the motor Speed above this value.  This limit may be set in response to a Limits Request or determined by the inverter based on operating conditions.Refer to SPN 11822 [Refere...";
CM_ BO_ 2565991934 "Motor/Generator 3 Inverter Limits Active DC Side";
CM_ SG_ 2565991934 MtrGnrtr3InvrtrLmtsAtvDCSdCRC "Motor/Generator 3 Inverter Limits Active DC Side CRC: The CRC is defined as follows: • Length: 8 bits • Polynomial: x^8+x^5+x^3+x^2+x+1 • Initial Value: FFh • Input Data Reflection: Not reflected • Result Data Reflection: Not reflected • XOR value: F...";
CM_ SG_ 2565991934 MtrGnrtr3InvrtrLmtsAtvDCSdCntr "Motor/Generator 3 Inverter Limits Active DC Side Counter: The message counter is used to detect situations where the transmitting ECU malfunction repeats the same frame all the time. The receiver of the information may use the counter parameter to de...";
CM_ SG_ 2565991934 MtGt3IvtLtsAtvDCSdVtMx "Motor/Generator 3 Inverter Limits Active DC Side Voltage Maximum: The inverter keeps the DC side voltage below this value.  This limit may be set in response to a Limits Request or determined by the inverter based on operating conditions.Refer to SPN...";
CM_ SG_ 2565991934 MtGt3IvtLtsAtvDCSdVtM "Motor/Generator 3 Inverter Limits Active DC Side Voltage Minimum: The inverter keeps the DC side voltage above this value.  This limit may be set in response to a Limits Request or determined by the inverter based on operating conditions.Refer to SPN...";
CM_ SG_ 2565991934 MtGt3IvtLtsAtvDCSdCtMx "Motor/Generator 3 Inverter Limits Active DC Side Current Maximum: The inverter keeps the DC side current below this value.  This limit may be set in response to a Limits Request or determined by the inverter based on operating conditions. Refer to SP...";
CM_ SG_ 2565991934 MtGt3IvtLtsAtvDCSdCtM "Motor/Generator 3 Inverter Limits Active DC Side Current Minimum: The inverter keeps the DC side current above this value.  This limit may be set in response to a Limits Request or determined by the inverter based on operating conditions.Refer to SPN...";
CM_ BO_ 2565992190 "Motor/Generator 3 Inverter Low Voltage";
CM_ SG_ 2565992190 MtrGnrtr3InvrtrSwthdIgntnVltg "Motor/Generator 3 Inverter Switched Ignition Voltage: Switched Ignition voltage supplied to this instance of the inverter controller.";
CM_ SG_ 2565992190 MtrGnrtr3InvrtrUnswthdSLIVltg "Motor/Generator 3 Inverter Unswitched SLI Voltage: Continuously supplied SLI power to this instance of the inverter controller.";
CM_ BO_ 2565992446 "Motor/Generator 3 Inverter Status 2";
CM_ SG_ 2565992446 MtrGnrtr3InvrtrStts2CRC "Motor/Generator 3 Inverter Status 2 CRC: The CRC is defined as follows: • Length: 8 bits • Polynomial: x^8+x^5+x^3+x^2+x+1 • Initial Value: FFh • Input Data Reflection: Not reflected • Result Data Reflection: Not reflected • XOR value: FFhSAE makes n...";
CM_ SG_ 2565992446 MtrGnrtr3InvrtrStts2Cntr "Motor/Generator 3 Inverter Status 2 Counter: The message counter is used to detect situations where the transmitting ECU malfunction repeats the same frame all the time. The receiver of the information may use the counter parameter to detect this sit...";
CM_ SG_ 2565992446 MtrGnrtr3AvllMxmmTrq "Motor/Generator 3 Available Maximum Torque: This is an estimate of the maximum available motor torque including active deratings at the present motor speed.  This refers to the motor rotor output and excludes any gearbox that may be attached to the m...";
CM_ SG_ 2565992446 MtrGnrtr3AvllMnmmTrq "Motor/Generator 3 Available Minimum Torque: This is an estimate of the minimum available motor torque including active deratings at the present motor speed.  This refers to the motor rotor output and excludes any gearbox that may be attached to the m...";
CM_ BO_ 2565992702 "Motor/Generator 3 Inverter Rate Limits Active 1";
CM_ SG_ 2565992702 MtrGnrtr3InvrtrRtLmtsAtv1CRC "Motor/Generator 3 Inverter Rate Limits Active 1 CRC: The CRC is defined as follows: • Length: 8 bits • Polynomial: x^8+x^5+x^3+x^2+x+1 • Initial Value: FFh • Input Data Reflection: Not reflected • Result Data Reflection: Not reflected • XOR value: FF...";
CM_ SG_ 2565992702 MtrGnrtr3InvrtrRtLmtsAtv1Cntr "Motor/Generator 3 Inverter Rate Limits Active 1 Counter: The message counter is used to detect situations where the transmitting ECU malfunction repeats the same frame all the time. The receiver of the information may use the counter parameter to det...";
CM_ SG_ 2565992702 MtGt3IvtRtLtsAtvAstSpdRtLt "Motor/Generator 3 Inverter Rate Limits Active Absolute Speed Rate Limit: The active maximum rate of change for the absolute motor speed  (i.e. |d(speed)|/dt) in all control modes of this motor/generator inverter instance. Refer to SPN 11822 [Referenc...";
CM_ SG_ 2565992702 MtGt3IvtRtLtsAtvAstTqRtLt "Motor/Generator 3 Inverter Rate Limits Active Absolute Torque Rate Limit: The active maximum rate of change for the absolute motor torque (i.e. |d(torque)|/dt) in all control modes of this motor/generator inverter instance. Refer to SPN 11821 [Refere...";
CM_ BO_ 2364666366 "Motor/Generator 4 Inverter Mode Feedback 1";
CM_ SG_ 2364666366 MtrGnrtr4InvrtrMdFdk1CRC "Motor/Generator 4 Inverter Mode Feedback 1 CRC: The CRC is defined as follows: • Length: 8 bits • Polynomial: x^8+x^5+x^3+x^2+x+1 • Initial Value: FFh • Input Data Reflection: Not reflected • Result Data Reflection: Not reflected • XOR value: FFhSAE ...";
CM_ SG_ 2364666366 MtrGnrtr4InvrtrMdFdk1Cntr "Motor/Generator 4 Inverter Mode Feedback 1 Counter: The message counter is used to detect situations where the transmitting ECU malfunction repeats the same frame all the time. The receiver of the information may use the counter parameter to detect t...";
CM_ SG_ 2364666366 MtrGnrtr4InvrtrCntrlLmtsOvrrdMd "Motor/Generator 4 Inverter Control Limits Override Mode: During normal operation this will have the same value as SPN 11928 [Control Limits Request Override Mode].  0 = Operating limits are not overridden.  If a limit was previously active, then it h...";
CM_ SG_ 2364666366 MtrGnrtr4InvrtrCntrlStpntMd "Motor/Generator 4 Inverter Control Setpoint Mode: Reports the inverter mode (See SPN 11931 [Control Setpoint Mode Request] for requested mode).Passive modes:  0 = Powered On - the inverter is commanded to be powered on and able to communicate, but th...";
CM_ SG_ 2364666366 MtrGnrtr4InvrtrHVILStts "Motor/Generator 4 Inverter HVIL Status: Reports the High Voltage Interlock Loop (HVIL) state.00b = HVIL Closed01b = HVIL Open10b = Error11b = Not Available";
CM_ BO_ 2565993214 "Motor/Generator 4 Inverter Limits Active Power";
CM_ SG_ 2565993214 MtrGnrtr4InvrtrLmtsAtvPwrCRC "Motor/Generator 4 Inverter Limits Active Power CRC: The CRC is defined as follows: • Length: 8 bits • Polynomial: x^8+x^5+x^3+x^2+x+1 • Initial Value: FFh • Input Data Reflection: Not reflected • Result Data Reflection: Not reflected • XOR value: FFh...";
CM_ SG_ 2565993214 MtrGnrtr4InvrtrLmtsAtvPwrCntr "Motor/Generator 4 Inverter Limits Active Power Counter: The message counter is used to detect situations where the transmitting ECU malfunction repeats the same frame all the time. The receiver of the information may use the counter parameter to dete...";
CM_ SG_ 2565993214 MtGt4IvtLtsAtvMPwMx "Motor/Generator 4 Inverter Limits Active Mechanical Power Maximum: The inverter keeps the mechanical motor power below this value.   This limit may be set in response to a Limits Request or determined by the inverter based on operating conditions.Ref...";
CM_ SG_ 2565993214 MtGt4IvtLtsAtvMPwM "Motor/Generator 4 Inverter Limits Active Mechanical Power Minimum: The inverter keeps the mechanical motor power above this value.   This limit may be set in response to a Limits Request or determined by the inverter based on operating conditions.Ref...";
CM_ SG_ 2565993214 MtGt4IvtLtsAtvDCSdPwMx "Motor/Generator 4 Inverter Limits Active DC Side Power Maximum: The inverter keeps the DC Side power below this value.   This limit may be set in response to a Limits Request or determined by the inverter based on operating conditions.Refer to SPN 11...";
CM_ SG_ 2565993214 MtGt4IvtLtsAtvDCSdPwM "Motor/Generator 4 Inverter Limits Active DC Side Power Minimum: The inverter keeps the DC side power above this value.   This limit may be set in response to a Limits Request or determined by the inverter based on operating conditions.Refer to SPN 11...";
CM_ BO_ 2565993470 "Motor/Generator 4 Inverter Limits Active Mechanical";
CM_ SG_ 2565993470 MtrGnrtr4InvrtrLmtsAtvMhnlCRC "Motor/Generator 4 Inverter Limits Active Mechanical CRC: The CRC is defined as follows: • Length: 8 bits • Polynomial: x^8+x^5+x^3+x^2+x+1 • Initial Value: FFh • Input Data Reflection: Not reflected • Result Data Reflection: Not reflected • XOR value...";
CM_ SG_ 2565993470 MtrGnrtr4InvrtrLmtsAtvMhnlCntr "Motor/Generator 4 Inverter Limits Active Mechanical Counter: The message counter is used to detect situations where the transmitting ECU malfunction repeats the same frame all the time. The receiver of the information may use the counter parameter to...";
CM_ SG_ 2565993470 MtrGnrtr4InvrtrLmtsAtvTrqMxmm "Motor/Generator 4 Inverter Limits Active Torque Maximum: The inverter keeps the motor torque below this value.  This limit may be set in response to a Limits Request or determined by the inverter based on operating conditions.Refer to SPN 11939 [Refe...";
CM_ SG_ 2565993470 MtrGnrtr4InvrtrLmtsAtvTrqMnmm "Motor/Generator 4 Inverter Limits Active Torque Minimum: The inverter keeps the motor torque above this value.  This limit may be set in response to a Limits Request or determined by the inverter based on operating conditions.Refer to SPN 11939 [Refe...";
CM_ SG_ 2565993470 MtrGnrtr4InvrtrLmtsAtvSpdMxmm "Motor/Generator 4 Inverter Limits Active Speed Maximum: The inverter keeps the motor speed below this value.  This limit may be set in response to a Limits Request or determined by the inverter based on operating conditions.Refer to SPN 11940 [Refere...";
CM_ SG_ 2565993470 MtrGnrtr4InvrtrLmtsAtvSpdMnmm "Motor/Generator 4 Inverter Limits Active Speed Minimum: The inverter keeps the motor Speed above this value.  This limit may be set in response to a Limits Request or determined by the inverter based on operating conditions.Refer to SPN 11940 [Refere...";
CM_ BO_ 2565993726 "Motor/Generator 4 Inverter Limits Active DC Side";
CM_ SG_ 2565993726 MtrGnrtr4InvrtrLmtsAtvDCSdCRC "Motor/Generator 4 Inverter Limits Active DC Side CRC: The CRC is defined as follows: • Length: 8 bits • Polynomial: x^8+x^5+x^3+x^2+x+1 • Initial Value: FFh • Input Data Reflection: Not reflected • Result Data Reflection: Not reflected • XOR value: F...";
CM_ SG_ 2565993726 MtrGnrtr4InvrtrLmtsAtvDCSdCntr "Motor/Generator 4 Inverter Limits Active DC Side Counter: The message counter is used to detect situations where the transmitting ECU malfunction repeats the same frame all the time. The receiver of the information may use the counter parameter to de...";
CM_ SG_ 2565993726 MtGt4IvtLtsAtvDCSdVtMx "Motor/Generator 4 Inverter Limits Active DC Side Voltage Maximum: The inverter keeps the DC side voltage below this value.  This limit may be set in response to a Limits Request or determined by the inverter based on operating conditions.Refer to SPN...";
CM_ SG_ 2565993726 MtGt4IvtLtsAtvDCSdVtM "Motor/Generator 4 Inverter Limits Active DC Side Voltage Minimum: The inverter keeps the DC side voltage above this value.  This limit may be set in response to a Limits Request or determined by the inverter based on operating conditions.Refer to SPN...";
CM_ SG_ 2565993726 MtGt4IvtLtsAtvDCSdCtMx "Motor/Generator 4 Inverter Limits Active DC Side Current Maximum: The inverter keeps the DC side current below this value.  This limit may be set in response to a Limits Request or determined by the inverter based on operating conditions. Refer to SP...";
CM_ SG_ 2565993726 MtGt4IvtLtsAtvDCSdCtM "Motor/Generator 4 Inverter Limits Active DC Side Current Minimum: The inverter keeps the DC side current above this value.  This limit may be set in response to a Limits Request or determined by the inverter based on operating conditions.Refer to SPN...";
CM_ BO_ 2565993982 "Motor/Generator 4 Inverter Low Voltage";
CM_ SG_ 2565993982 MtrGnrtr4InvrtrSwthdIgntnVltg "Motor/Generator 4 Inverter Switched Ignition Voltage: Switched Ignition voltage supplied to this instance of the inverter controller.";
CM_ SG_ 2565993982 MtrGnrtr4InvrtrUnswthdSLIVltg "Motor/Generator 4 Inverter Unswitched SLI Voltage: Continuously supplied SLI power to this instance of the inverter controller.";
CM_ BO_ 2565994238 "Motor/Generator 4 Inverter Status 2";
CM_ SG_ 2565994238 MtrGnrtr4InvrtrStts2CRC "Motor/Generator 4 Inverter Status 2 CRC: The CRC is defined as follows: • Length: 8 bits • Polynomial: x^8+x^5+x^3+x^2+x+1 • Initial Value: FFh • Input Data Reflection: Not reflected • Result Data Reflection: Not reflected • XOR value: FFhSAE makes n...";
CM_ SG_ 2565994238 MtrGnrtr4InvrtrStts2Cntr "Motor/Generator 4 Inverter Status 2 Counter: The message counter is used to detect situations where the transmitting ECU malfunction repeats the same frame all the time. The receiver of the information may use the counter parameter to detect this sit...";
CM_ SG_ 2565994238 MtrGnrtr4AvllMxmmTrq "Motor/Generator 4 Available Maximum Torque: This is an estimate of the maximum available motor torque including active deratings at the present motor speed.  This refers to the motor rotor output and excludes any gearbox that may be attached to the m...";
CM_ SG_ 2565994238 MtrGnrtr4AvllMnmmTrq "Motor/Generator 4 Available Minimum Torque: This is an estimate of the minimum available motor torque including active deratings at the present motor speed.  This refers to the motor rotor output and excludes any gearbox that may be attached to the m...";
CM_ BO_ 2565994494 "Motor/Generator 4 Inverter Rate Limits Active 1";
CM_ SG_ 2565994494 MtrGnrtr4InvrtrRtLmtsAtv1CRC "Motor/Generator 4 Inverter Rate Limits Active 1 CRC: The CRC is defined as follows: • Length: 8 bits • Polynomial: x^8+x^5+x^3+x^2+x+1 • Initial Value: FFh • Input Data Reflection: Not reflected • Result Data Reflection: Not reflected • XOR value: FF...";
CM_ SG_ 2565994494 MtrGnrtr4InvrtrRtLmtsAtv1Cntr "Motor/Generator 4 Inverter Rate Limits Active 1 Counter: The message counter is used to detect situations where the transmitting ECU malfunction repeats the same frame all the time. The receiver of the information may use the counter parameter to det...";
CM_ SG_ 2565994494 MtGt4IvtRtLtsAtvAstSpdRtLt "Motor/Generator 4 Inverter Rate Limits Active Absolute Speed Rate Limit: The active maximum rate of change for the absolute motor speed  (i.e. |d(speed)|/dt) in all control modes of this motor/generator inverter instance. Refer to SPN 11940 [Referenc...";
CM_ SG_ 2565994494 MtGt4IvtRtLtsAtvAstTqRtLt "Motor/Generator 4 Inverter Rate Limits Active Absolute Torque Rate Limit: The active maximum rate of change for the absolute motor torque (i.e. |d(torque)|/dt) in all control modes of this motor/generator inverter instance. Refer to SPN 11939 [Refere...";
CM_ BO_ 2364668158 "Motor/Generator 5 Inverter Mode Feedback 1";
CM_ SG_ 2364668158 MtrGnrtr5InvrtrMdFdk1CRC "Motor/Generator 5 Inverter Mode Feedback 1 CRC: The CRC is defined as follows: • Length: 8 bits • Polynomial: x^8+x^5+x^3+x^2+x+1 • Initial Value: FFh • Input Data Reflection: Not reflected • Result Data Reflection: Not reflected • XOR value: FFhSAE ...";
CM_ SG_ 2364668158 MtrGnrtr5InvrtrMdFdk1Cntr "Motor/Generator 5 Inverter Mode Feedback 1 Counter: The message counter is used to detect situations where the transmitting ECU malfunction repeats the same frame all the time. The receiver of the information may use the counter parameter to detect t...";
CM_ SG_ 2364668158 MtrGnrtr5InvrtrCntrlLmtsOvrrdMd "Motor/Generator 5 Inverter Control Limits Override Mode: During normal operation this will have the same value as SPN 12046 [Control Limits Request Override Mode].  0 = Operating limits are not overridden.  If a limit was previously active, then it h...";
CM_ SG_ 2364668158 MtrGnrtr5InvrtrCntrlStpntMd "Motor/Generator 5 Inverter Control Setpoint Mode: Reports the inverter mode (See SPN 12049 [Control Setpoint Mode Request] for requested mode).Passive modes:  0 = Powered On - the inverter is commanded to be powered on and able to communicate, but th...";
CM_ SG_ 2364668158 MtrGnrtr5InvrtrHVILStts "Motor/Generator 5 Inverter HVIL Status: Reports the High Voltage Interlock Loop (HVIL) state.00b = HVIL Closed01b = HVIL Open10b = Error11b = Not Available";
CM_ BO_ 2565995006 "Motor/Generator 5 Inverter Limits Active Power";
CM_ SG_ 2565995006 MtrGnrtr5InvrtrLmtsAtvPwrCRC "Motor/Generator 5 Inverter Limits Active Power CRC: The CRC is defined as follows: • Length: 8 bits • Polynomial: x^8+x^5+x^3+x^2+x+1 • Initial Value: FFh • Input Data Reflection: Not reflected • Result Data Reflection: Not reflected • XOR value: FFh...";
CM_ SG_ 2565995006 MtrGnrtr5InvrtrLmtsAtvPwrCntr "Motor/Generator 5 Inverter Limits Active Power Counter: The message counter is used to detect situations where the transmitting ECU malfunction repeats the same frame all the time. The receiver of the information may use the counter parameter to dete...";
CM_ SG_ 2565995006 MtGt5IvtLtsAtvMPwMx "Motor/Generator 5 Inverter Limits Active Mechanical Power Maximum: The inverter keeps the mechanical motor power below this value.   This limit may be set in response to a Limits Request or determined by the inverter based on operating conditions.Ref...";
CM_ SG_ 2565995006 MtGt5IvtLtsAtvMPwM "Motor/Generator 5 Inverter Limits Active Mechanical Power Minimum: The inverter keeps the mechanical motor power above this value.   This limit may be set in response to a Limits Request or determined by the inverter based on operating conditions.Ref...";
CM_ SG_ 2565995006 MtGt5IvtLtsAtvDCSdPwMx "Motor/Generator 5 Inverter Limits Active DC Side Power Maximum: The inverter keeps the DC Side power below this value.   This limit may be set in response to a Limits Request or determined by the inverter based on operating conditions.Refer to SPN 12...";
CM_ SG_ 2565995006 MtGt5IvtLtsAtvDCSdPwM "Motor/Generator 5 Inverter Limits Active DC Side Power Minimum: The inverter keeps the DC side power above this value.   This limit may be set in response to a Limits Request or determined by the inverter based on operating conditions.Refer to SPN 12...";
CM_ BO_ 2565995262 "Motor/Generator 5 Inverter Limits Active Mechanical";
CM_ SG_ 2565995262 MtrGnrtr5InvrtrLmtsAtvMhnlCRC "Motor/Generator 5 Inverter Limits Active Mechanical CRC: The CRC is defined as follows: • Length: 8 bits • Polynomial: x^8+x^5+x^3+x^2+x+1 • Initial Value: FFh • Input Data Reflection: Not reflected • Result Data Reflection: Not reflected • XOR value...";
CM_ SG_ 2565995262 MtrGnrtr5InvrtrLmtsAtvMhnlCntr "Motor/Generator 5 Inverter Limits Active Mechanical Counter: The message counter is used to detect situations where the transmitting ECU malfunction repeats the same frame all the time. The receiver of the information may use the counter parameter to...";
CM_ SG_ 2565995262 MtrGnrtr5InvrtrLmtsAtvTrqMxmm "Motor/Generator 5 Inverter Limits Active Torque Maximum: The inverter keeps the motor torque below this value.  This limit may be set in response to a Limits Request or determined by the inverter based on operating conditions.Refer to SPN 12057 [Refe...";
CM_ SG_ 2565995262 MtrGnrtr5InvrtrLmtsAtvTrqMnmm "Motor/Generator 5 Inverter Limits Active Torque Minimum: The inverter keeps the motor torque above this value.  This limit may be set in response to a Limits Request or determined by the inverter based on operating conditions.Refer to SPN 12057 [Refe...";
CM_ SG_ 2565995262 MtrGnrtr5InvrtrLmtsAtvSpdMxmm "Motor/Generator 5 Inverter Limits Active Speed Maximum: The inverter keeps the motor speed below this value.  This limit may be set in response to a Limits Request or determined by the inverter based on operating conditions.Refer to SPN 12058 [Refere...";
CM_ SG_ 2565995262 MtrGnrtr5InvrtrLmtsAtvSpdMnmm "Motor/Generator 5 Inverter Limits Active Speed Minimum: The inverter keeps the motor Speed above this value.  This limit may be set in response to a Limits Request or determined by the inverter based on operating conditions.Refer to SPN 12058 [Refere...";
CM_ BO_ 2565995518 "Motor/Generator 5 Inverter Limits Active DC Side";
CM_ SG_ 2565995518 MtrGnrtr5InvrtrLmtsAtvDCSdCRC "Motor/Generator 5 Inverter Limits Active DC Side CRC: The CRC is defined as follows: • Length: 8 bits • Polynomial: x^8+x^5+x^3+x^2+x+1 • Initial Value: FFh • Input Data Reflection: Not reflected • Result Data Reflection: Not reflected • XOR value: F...";
CM_ SG_ 2565995518 MtrGnrtr5InvrtrLmtsAtvDCSdCntr "Motor/Generator 5 Inverter Limits Active DC Side Counter: The message counter is used to detect situations where the transmitting ECU malfunction repeats the same frame all the time. The receiver of the information may use the counter parameter to de...";
CM_ SG_ 2565995518 MtGt5IvtLtsAtvDCSdVtMx "Motor/Generator 5 Inverter Limits Active DC Side Voltage Maximum: The inverter keeps the DC side voltage below this value.  This limit may be set in response to a Limits Request or determined by the inverter based on operating conditions.Refer to SPN...";
CM_ SG_ 2565995518 MtGt5IvtLtsAtvDCSdVtM "Motor/Generator 5 Inverter Limits Active DC Side Voltage Minimum: The inverter keeps the DC side voltage above this value.  This limit may be set in response to a Limits Request or determined by the inverter based on operating conditions.Refer to SPN...";
CM_ SG_ 2565995518 MtGt5IvtLtsAtvDCSdCtMx "Motor/Generator 5 Inverter Limits Active DC Side Current Maximum: The inverter keeps the DC side current below this value.  This limit may be set in response to a Limits Request or determined by the inverter based on operating conditions. Refer to SP...";
CM_ SG_ 2565995518 MtGt5IvtLtsAtvDCSdCtM "Motor/Generator 5 Inverter Limits Active DC Side Current Minimum: The inverter keeps the DC side current above this value.  This limit may be set in response to a Limits Request or determined by the inverter based on operating conditions.Refer to SPN...";
CM_ BO_ 2565995774 "Motor/Generator 5 Inverter Low Voltage";
CM_ SG_ 2565995774 MtrGnrtr5InvrtrSwthdIgntnVltg "Motor/Generator 5 Inverter Switched Ignition Voltage: Switched Ignition voltage supplied to this instance of the inverter controller.";
CM_ SG_ 2565995774 MtrGnrtr5InvrtrUnswthdSLIVltg "Motor/Generator 5 Inverter Unswitched SLI Voltage: Continuously supplied SLI power to this instance of the inverter controller.";
CM_ BO_ 2565996030 "Motor/Generator 5 Inverter Status 2";
CM_ SG_ 2565996030 MtrGnrtr5InvrtrStts2CRC "Motor/Generator 5 Inverter Status 2 CRC: The CRC is defined as follows: • Length: 8 bits • Polynomial: x^8+x^5+x^3+x^2+x+1 • Initial Value: FFh • Input Data Reflection: Not reflected • Result Data Reflection: Not reflected • XOR value: FFhSAE makes n...";
CM_ SG_ 2565996030 MtrGnrtr5InvrtrStts2Cntr "Motor/Generator 5 Inverter Status 2 Counter: The message counter is used to detect situations where the transmitting ECU malfunction repeats the same frame all the time. The receiver of the information may use the counter parameter to detect this sit...";
CM_ SG_ 2565996030 MtrGnrtr5AvllMxmmTrq "Motor/Generator 5 Available Maximum Torque: This is an estimate of the maximum available motor torque including active deratings at the present motor speed.  This refers to the motor rotor output and excludes any gearbox that may be attached to the m...";
CM_ SG_ 2565996030 MtrGnrtr5AvllMnmmTrq "Motor/Generator 5 Available Minimum Torque: This is an estimate of the minimum available motor torque including active deratings at the present motor speed.  This refers to the motor rotor output and excludes any gearbox that may be attached to the m...";
CM_ BO_ 2565996286 "Motor/Generator 5 Inverter Rate Limits Active 1";
CM_ SG_ 2565996286 MtrGnrtr5InvrtrRtLmtsAtv1CRC "Motor/Generator 5 Inverter Rate Limits Active 1 CRC: The CRC is defined as follows: • Length: 8 bits • Polynomial: x^8+x^5+x^3+x^2+x+1 • Initial Value: FFh • Input Data Reflection: Not reflected • Result Data Reflection: Not reflected • XOR value: FF...";
CM_ SG_ 2565996286 MtrGnrtr5InvrtrRtLmtsAtv1Cntr "Motor/Generator 5 Inverter Rate Limits Active 1 Counter: The message counter is used to detect situations where the transmitting ECU malfunction repeats the same frame all the time. The receiver of the information may use the counter parameter to det...";
CM_ SG_ 2565996286 MtGt5IvtRtLtsAtvAstSpdRtLt "Motor/Generator 5 Inverter Rate Limits Active Absolute Speed Rate Limit: The active maximum rate of change for the absolute motor speed  (i.e. |d(speed)|/dt) in all control modes of this motor/generator inverter instance. Refer to SPN 12058 [Referenc...";
CM_ SG_ 2565996286 MtGt5IvtRtLtsAtvAstTqRtLt "Motor/Generator 5 Inverter Rate Limits Active Absolute Torque Rate Limit: The active maximum rate of change for the absolute motor torque (i.e. |d(torque)|/dt) in all control modes of this motor/generator inverter instance. Refer to SPN 12057 [Refere...";
CM_ BO_ 2364669950 "Motor/Generator 6 Inverter Mode Feedback 1";
CM_ SG_ 2364669950 MtrGnrtr6InvrtrMdFdk1CRC "Motor/Generator 6 Inverter Mode Feedback 1 CRC: The CRC is defined as follows: • Length: 8 bits • Polynomial: x^8+x^5+x^3+x^2+x+1 • Initial Value: FFh • Input Data Reflection: Not reflected • Result Data Reflection: Not reflected • XOR value: FFhSAE ...";
CM_ SG_ 2364669950 MtrGnrtr6InvrtrMdFdk1Cntr "Motor/Generator 6 Inverter Mode Feedback 1 Counter: The message counter is used to detect situations where the transmitting ECU malfunction repeats the same frame all the time. The receiver of the information may use the counter parameter to detect t...";
CM_ SG_ 2364669950 MtrGnrtr6InvrtrCntrlLmtsOvrrdMd "Motor/Generator 6 Inverter Control Limits Override Mode: During normal operation this will have the same value as SPN 12164 [Control Limits Request Override Mode].  0 = Operating limits are not overridden.  If a limit was previously active, then it h...";
CM_ SG_ 2364669950 MtrGnrtr6InvrtrCntrlStpntMd "Motor/Generator 6 Inverter Control Setpoint Mode: Reports the inverter mode (See SPN 12167 [Control Setpoint Mode Request] for requested mode).Passive modes:  0 = Powered On - the inverter is commanded to be powered on and able to communicate, but th...";
CM_ SG_ 2364669950 MtrGnrtr6InvrtrHVILStts "Motor/Generator 6 Inverter HVIL Status: Reports the High Voltage Interlock Loop (HVIL) state.00b = HVIL Closed01b = HVIL Open10b = Error11b = Not Available";
CM_ BO_ 2565996798 "Motor/Generator 6 Inverter Limits Active Power";
CM_ SG_ 2565996798 MtrGnrtr6InvrtrLmtsAtvPwrCRC "Motor/Generator 6 Inverter Limits Active Power CRC: The CRC is defined as follows: • Length: 8 bits • Polynomial: x^8+x^5+x^3+x^2+x+1 • Initial Value: FFh • Input Data Reflection: Not reflected • Result Data Reflection: Not reflected • XOR value: FFh...";
CM_ SG_ 2565996798 MtrGnrtr6InvrtrLmtsAtvPwrCntr "Motor/Generator 6 Inverter Limits Active Power Counter: The message counter is used to detect situations where the transmitting ECU malfunction repeats the same frame all the time. The receiver of the information may use the counter parameter to dete...";
CM_ SG_ 2565996798 MtGt6IvtLtsAtvMPwMx "Motor/Generator 6 Inverter Limits Active Mechanical Power Maximum: The inverter keeps the mechanical motor power below this value.   This limit may be set in response to a Limits Request or determined by the inverter based on operating conditions.Ref...";
CM_ SG_ 2565996798 MtGt6IvtLtsAtvMPwM "Motor/Generator 6 Inverter Limits Active Mechanical Power Minimum: The inverter keeps the mechanical motor power above this value.   This limit may be set in response to a Limits Request or determined by the inverter based on operating conditions.Ref...";
CM_ SG_ 2565996798 MtGt6IvtLtsAtvDCSdPwMx "Motor/Generator 6 Inverter Limits Active DC Side Power Maximum: The inverter keeps the DC Side power below this value.   This limit may be set in response to a Limits Request or determined by the inverter based on operating conditions.Refer to SPN 12...";
CM_ SG_ 2565996798 MtGt6IvtLtsAtvDCSdPwM "Motor/Generator 6 Inverter Limits Active DC Side Power Minimum: The inverter keeps the DC side power above this value.   This limit may be set in response to a Limits Request or determined by the inverter based on operating conditions.Refer to SPN 12...";
CM_ BO_ 2565997054 "Motor/Generator 6 Inverter Limits Active Mechanical";
CM_ SG_ 2565997054 MtrGnrtr6InvrtrLmtsAtvMhnlCRC "Motor/Generator 6 Inverter Limits Active Mechanical CRC: The CRC is defined as follows: • Length: 8 bits • Polynomial: x^8+x^5+x^3+x^2+x+1 • Initial Value: FFh • Input Data Reflection: Not reflected • Result Data Reflection: Not reflected • XOR value...";
CM_ SG_ 2565997054 MtrGnrtr6InvrtrLmtsAtvMhnlCntr "Motor/Generator 6 Inverter Limits Active Mechanical Counter: The message counter is used to detect situations where the transmitting ECU malfunction repeats the same frame all the time. The receiver of the information may use the counter parameter to...";
CM_ SG_ 2565997054 MtrGnrtr6InvrtrLmtsAtvTrqMxmm "Motor/Generator 6 Inverter Limits Active Torque Maximum: The inverter keeps the motor torque below this value.  This limit may be set in response to a Limits Request or determined by the inverter based on operating conditions.Refer to SPN 12175 [Refe...";
CM_ SG_ 2565997054 MtrGnrtr6InvrtrLmtsAtvTrqMnmm "Motor/Generator 6 Inverter Limits Active Torque Minimum: The inverter keeps the motor torque above this value.  This limit may be set in response to a Limits Request or determined by the inverter based on operating conditions.Refer to SPN 12175 [Refe...";
CM_ SG_ 2565997054 MtrGnrtr6InvrtrLmtsAtvSpdMxmm "Motor/Generator 6 Inverter Limits Active Speed Maximum: The inverter keeps the motor speed below this value.  This limit may be set in response to a Limits Request or determined by the inverter based on operating conditions.Refer to SPN 12176 [Refere...";
CM_ SG_ 2565997054 MtrGnrtr6InvrtrLmtsAtvSpdMnmm "Motor/Generator 6 Inverter Limits Active Speed Minimum: The inverter keeps the motor Speed above this value.  This limit may be set in response to a Limits Request or determined by the inverter based on operating conditions.Refer to SPN 12176 [Refere...";
CM_ BO_ 2565997310 "Motor/Generator 6 Inverter Limits Active DC Side";
CM_ SG_ 2565997310 MtrGnrtr6InvrtrLmtsAtvDCSdCRC "Motor/Generator 6 Inverter Limits Active DC Side CRC: The CRC is defined as follows: • Length: 8 bits • Polynomial: x^8+x^5+x^3+x^2+x+1 • Initial Value: FFh • Input Data Reflection: Not reflected • Result Data Reflection: Not reflected • XOR value: F...";
CM_ SG_ 2565997310 MtrGnrtr6InvrtrLmtsAtvDCSdCntr "Motor/Generator 6 Inverter Limits Active DC Side Counter: The message counter is used to detect situations where the transmitting ECU malfunction repeats the same frame all the time. The receiver of the information may use the counter parameter to de...";
CM_ SG_ 2565997310 MtGt6IvtLtsAtvDCSdVtMx "Motor/Generator 6 Inverter Limits Active DC Side Voltage Maximum: The inverter keeps the DC side voltage below this value.  This limit may be set in response to a Limits Request or determined by the inverter based on operating conditions.Refer to SPN...";
CM_ SG_ 2565997310 MtGt6IvtLtsAtvDCSdVtM "Motor/Generator 6 Inverter Limits Active DC Side Voltage Minimum: The inverter keeps the DC side voltage above this value.  This limit may be set in response to a Limits Request or determined by the inverter based on operating conditions.Refer to SPN...";
CM_ SG_ 2565997310 MtGt6IvtLtsAtvDCSdCtMx "Motor/Generator 6 Inverter Limits Active DC Side Current Maximum: The inverter keeps the DC side current below this value.  This limit may be set in response to a Limits Request or determined by the inverter based on operating conditions. Refer to SP...";
CM_ SG_ 2565997310 MtGt6IvtLtsAtvDCSdCtM "Motor/Generator 6 Inverter Limits Active DC Side Current Minimum: The inverter keeps the DC side current above this value.  This limit may be set in response to a Limits Request or determined by the inverter based on operating conditions.Refer to SPN...";
CM_ BO_ 2565997566 "Motor/Generator 6 Inverter Low Voltage";
CM_ SG_ 2565997566 MtrGnrtr6InvrtrSwthdIgntnVltg "Motor/Generator 6 Inverter Switched Ignition Voltage: Switched Ignition voltage supplied to this instance of the inverter controller.";
CM_ SG_ 2565997566 MtrGnrtr6InvrtrUnswthdSLIVltg "Motor/Generator 6 Inverter Unswitched SLI Voltage: Continuously supplied SLI power to this instance of the inverter controller.";
CM_ BO_ 2565997822 "Motor/Generator 6 Inverter Status 2";
CM_ SG_ 2565997822 MtrGnrtr6InvrtrStts2CRC "Motor/Generator 6 Inverter Status 2 CRC: The CRC is defined as follows: • Length: 8 bits • Polynomial: x^8+x^5+x^3+x^2+x+1 • Initial Value: FFh • Input Data Reflection: Not reflected • Result Data Reflection: Not reflected • XOR value: FFhSAE makes n...";
CM_ SG_ 2565997822 MtrGnrtr6InvrtrStts2Cntr "Motor/Generator 6 Inverter Status 2 Counter: The message counter is used to detect situations where the transmitting ECU malfunction repeats the same frame all the time. The receiver of the information may use the counter parameter to detect this sit...";
CM_ SG_ 2565997822 MtrGnrtr6AvllMxmmTrq "Motor/Generator 6 Available Maximum Torque: This is an estimate of the maximum available motor torque including active deratings at the present motor speed.  This refers to the motor rotor output and excludes any gearbox that may be attached to the m...";
CM_ SG_ 2565997822 MtrGnrtr6AvllMnmmTrq "Motor/Generator 6 Available Minimum Torque: This is an estimate of the minimum available motor torque including active deratings at the present motor speed.  This refers to the motor rotor output and excludes any gearbox that may be attached to the m...";
CM_ BO_ 2565998078 "Motor/Generator 6 Inverter Rate Limits Active 1";
CM_ SG_ 2565998078 MtrGnrtr6InvrtrRtLmtsAtv1CRC "Motor/Generator 6 Inverter Rate Limits Active 1 CRC: The CRC is defined as follows: • Length: 8 bits • Polynomial: x^8+x^5+x^3+x^2+x+1 • Initial Value: FFh • Input Data Reflection: Not reflected • Result Data Reflection: Not reflected • XOR value: FF...";
CM_ SG_ 2565998078 MtrGnrtr6InvrtrRtLmtsAtv1Cntr "Motor/Generator 6 Inverter Rate Limits Active 1 Counter: The message counter is used to detect situations where the transmitting ECU malfunction repeats the same frame all the time. The receiver of the information may use the counter parameter to det...";
CM_ SG_ 2565998078 MtGt6IvtRtLtsAtvAstSpdRtLt "Motor/Generator 6 Inverter Rate Limits Active Absolute Speed Rate Limit: The active maximum rate of change for the absolute motor speed  (i.e. |d(speed)|/dt) in all control modes of this motor/generator inverter instance. Refer to SPN 12176 [Referenc...";
CM_ SG_ 2565998078 MtGt6IvtRtLtsAtvAstTqRtLt "Motor/Generator 6 Inverter Rate Limits Active Absolute Torque Rate Limit: The active maximum rate of change for the absolute motor torque (i.e. |d(torque)|/dt) in all control modes of this motor/generator inverter instance. Refer to SPN 12175 [Refere...";
CM_ BO_ 2364671742 "Blind Spot Detection 1";
CM_ SG_ 2364671742 BlindSpotDetectionState "Blind Spot Detection State: Current operational state of the blind spot detection function. 0000b = system is not ready (initialization not finished) 0001b = system is temporarily not available (e.g. due to boundary conditions necessary for operation...";
CM_ SG_ 2364671742 BlindSpotCollisionWarningLevel "Blind Spot Collision Warning Level: To implement different human machine interface (HMI) concepts, e.g. visual only, visual/audible, different warning tones etc., the object detection provides different levels of collision warning. 0000b = no warning...";
CM_ SG_ 2364671742 BlndSptWrnngRlvntOjtDttd "Blind Spot Warning Relevant Object Detected: Indication if the blind spot detection system (BSD) is monitoring a relevant object.000b = No relevant object monitored 001b = Single relevant object is being monitored 010b = Multiple relevant objects are...";
CM_ SG_ 2364671742 BndOffPrltfMstImprtntOjt "Bend-Off Probability of Most Important Object: Probabilty if the most important monitored relevant object might start a bend-off maneuver (e.g. turning), which could clear the travelling path of the host vehicle. 000b = no indication for a bend-off m...";
CM_ SG_ 2364671742 BlndSptDttnLftSdMntrd "Blind Spot Detection Left Side Monitored: Indicates if left side area is monitored by the blind spot detection system. This signal can be used to trigger the correct warning(s) in the human machine interface (HMI).00b = Not being monitored 01b = Moni...";
CM_ SG_ 2364671742 BlndSptDttnRghtSdMntrd "Blind Spot Detection Right Side Monitored: Indicates if right side area is monitored by the blind spot detection system. This signal can be used to trigger the correct warning(s) in the human machine interface (HMI).00b = Not being monitored 01b = Mo...";
CM_ SG_ 2364671742 BlndSptDttnFrntMntrd "Blind Spot Detection Front Monitored: Indicates if front area is monitored by the blind spot detection system. This signal can be used to trigger the correct warning(s) in the human machine interface (HMI).00b = Not being monitored 01b = Monitored10b...";
CM_ SG_ 2364671742 BlindSpotDetectionRearMonitored "Blind Spot Detection Rear Monitored: Indicates if rear area is monitored by the blind spot detection system. This signal can be used to trigger the correct warning(s) in the human machine interface (HMI).00b = Not being monitored 01b = Monitored10b =...";
CM_ BO_ 2364671998 "Winch Information 1";
CM_ SG_ 2364671998 WinchMotorEncoderPosition "Winch Motor Encoder Position: Angular position of the winch motor shaft where 0 represents the initial position, with the value incrementing up to 32767 before rolling over to 0 at one complete revolution.  Likewise, the value decrements for reverse ...";
CM_ SG_ 2364671998 WinchRevolutionCounter "Winch Revolution Counter: Count of complete revolutions since reset. Value increments in forward direction and decrements in reverse direction.";
CM_ BO_ 2364672254 "Motor/Generator 3 Inverter Control";
CM_ SG_ 2364672254 MtrGnrtr3InvrtrCntrlCRC "Motor/Generator 3 Inverter Control CRC: The CRC is defined as follows:  • Length: 8 bits  • Polynomial: x^8+x^5+x^3+x^2+x+1  • Initial Value: FFh  • Input Data Reflection: Not reflected  • Result Data Reflection: Not reflected  • XOR value: FFhSAE ma...";
CM_ SG_ 2364672254 MtrGnrtr3InvrtrCntrlCntr "Motor/Generator 3 Inverter Control Counter: The message counter is used to detect situations where the transmitting ECU malfunction repeats the same frame all the time. The receiver of the information may use the counter parameter to detect this situ...";
CM_ SG_ 2364672254 MtGt3IvtCtLtsRqstOvdMd "Motor/Generator 3 Inverter Control Limits Request Override Mode: This parameter provides a way to temporarily override limits that are being received by the inverter in other messages.  It allows a specific type of limit to be transmitted at a high r...";
CM_ SG_ 2364672254 MtGt3IvtCtLtsRqstOvdMx "Motor/Generator 3 Inverter Control Limits Request Override Maximum: The Maximum limit requested by this parameter depends on the value of SPN 11810 [Control Limits Request Override Mode].In normal operating conditions, the inverter operating limits a...";
CM_ SG_ 2364672254 MtGt3IvtCtLtsRqstOvdM "Motor/Generator 3 Inverter Control Limits Request Override Minimum : The Minimum limit requested by this parameter depends on the value of SPN 11810 [Control Limits Request Override Mode].In normal operating conditions, the inverter operating limits ...";
CM_ SG_ 2364672254 MtrGnrtr3InvrtrCntrlStpntMdRqst "Motor/Generator 3 Inverter Control Setpoint Mode Request: Requests the modes for this instance of the inverter.  See SPN 11818 [Control Setpoint Mode] for the feedback to this request.Passive modes:  Modes where the inverter does not actively control...";
CM_ SG_ 2364672254 MtrGnrtr3InvrtrCntrlStpntRqst "Motor/Generator 3 Inverter Control Setpoint Request: Requests the set point for this inverter.  The type of set point requested by this parameter depends on the value of SPN 11813 [Control Setpoint Mode Request] as follows:Passive Modes: In any Passi...";
CM_ BO_ 2565999102 "Motor/Generator 3 Inverter Rate Limits Request 1";
CM_ SG_ 2565999102 MtrGnrtr3InvrtrRtLmtsRqst1CRC "Motor/Generator 3 Inverter Rate Limits Request 1 CRC: The CRC is defined as follows: • Length: 8 bits • Polynomial: x^8+x^5+x^3+x^2+x+1 • Initial Value: FFh • Input Data Reflection: Not reflected • Result Data Reflection: Not reflected • XOR value: F...";
CM_ SG_ 2565999102 MtrGnrtr3InvrtrRtLmtsRqst1Cntr "Motor/Generator 3 Inverter Rate Limits Request 1 Counter: The message counter is used to detect situations where the transmitting ECU malfunction repeats the same frame all the time. The receiver of the information may use the counter parameter to de...";
CM_ SG_ 2565999102 MtGt3IvtRtLtsRqstAstSpdRtLt "Motor/Generator 3 Inverter Rate Limits Request Absolute Speed Rate Limit: The maximum rate of change for the absolute motor speed  (i.e. |d(speed)|/dt) in all control modes. Refer to SPN 11822 [Reference Speed] to convert %/sec to RPM/sec. Request a ...";
CM_ SG_ 2565999102 MtGt3IvtRtLtsRqstAstTqRtLt "Motor/Generator 3 Inverter Rate Limits Request Absolute Torque Rate Limit: The maximum rate of change for the absolute motor torque (i.e. |d(torque)|/dt) in all control modes. Refer to SPN 11821 [Reference Torque] to convert %/sec to Nm/sec. Request ...";
CM_ BO_ 2364672766 "Motor/Generator 4 Inverter Control";
CM_ SG_ 2364672766 MtrGnrtr4InvrtrCntrlCRC "Motor/Generator 4 Inverter Control CRC: The CRC is defined as follows:  • Length: 8 bits  • Polynomial: x^8+x^5+x^3+x^2+x+1  • Initial Value: FFh  • Input Data Reflection: Not reflected  • Result Data Reflection: Not reflected  • XOR value: FFhSAE ma...";
CM_ SG_ 2364672766 MtrGnrtr4InvrtrCntrlCntr "Motor/Generator 4 Inverter Control Counter: The message counter is used to detect situations where the transmitting ECU malfunction repeats the same frame all the time. The receiver of the information may use the counter parameter to detect this situ...";
CM_ SG_ 2364672766 MtGt4IvtCtLtsRqstOvdMd "Motor/Generator 4 Inverter Control Limits Request Override Mode: This parameter provides a way to temporarily override limits that are being received by the inverter in other messages.  It allows a specific type of limit to be transmitted at a high r...";
CM_ SG_ 2364672766 MtGt4IvtCtLtsRqstOvdMx "Motor/Generator 4 Inverter Control Limits Request Override Maximum: The Maximum limit requested by this parameter depends on the value of SPN 11928 [Control Limits Request Override Mode].In normal operating conditions, the inverter operating limits a...";
CM_ SG_ 2364672766 MtGt4IvtCtLtsRqstOvdM "Motor/Generator 4 Inverter Control Limits Request Override Minimum : The Minimum limit requested by this parameter depends on the value of SPN 11928 [Control Limits Request Override Mode].In normal operating conditions, the inverter operating limits ...";
CM_ SG_ 2364672766 MtrGnrtr4InvrtrCntrlStpntMdRqst "Motor/Generator 4 Inverter Control Setpoint Mode Request: Requests the modes for this instance of the inverter.  See SPN 11936 [Control Setpoint Mode] for the feedback to this request.Passive modes:  Modes where the inverter does not actively control...";
CM_ SG_ 2364672766 MtrGnrtr4InvrtrCntrlStpntRqst "Motor/Generator 4 Inverter Control Setpoint Request: Requests the set point for this inverter.  The type of set point requested by this parameter depends on the value of SPN 11931 [Control Setpoint Mode Request] as follows:Passive Modes: In any Passi...";
CM_ BO_ 2565999614 "Motor/Generator 4 Inverter Rate Limits Request 1";
CM_ SG_ 2565999614 MtrGnrtr4InvrtrRtLmtsRqst1CRC "Motor/Generator 4 Inverter Rate Limits Request 1 CRC: The CRC is defined as follows: • Length: 8 bits • Polynomial: x^8+x^5+x^3+x^2+x+1 • Initial Value: FFh • Input Data Reflection: Not reflected • Result Data Reflection: Not reflected • XOR value: F...";
CM_ SG_ 2565999614 MtrGnrtr4InvrtrRtLmtsRqst1Cntr "Motor/Generator 4 Inverter Rate Limits Request 1 Counter: The message counter is used to detect situations where the transmitting ECU malfunction repeats the same frame all the time. The receiver of the information may use the counter parameter to de...";
CM_ SG_ 2565999614 MtGt4IvtRtLtsRqstAstSpdRtLt "Motor/Generator 4 Inverter Rate Limits Request Absolute Speed Rate Limit: The maximum rate of change for the absolute motor speed  (i.e. |d(speed)|/dt) in all control modes. Refer to SPN 11940 [Reference Speed] to convert %/sec to RPM/sec. Request a ...";
CM_ SG_ 2565999614 MtGt4IvtRtLtsRqstAstTqRtLt "Motor/Generator 4 Inverter Rate Limits Request Absolute Torque Rate Limit: The maximum rate of change for the absolute motor torque (i.e. |d(torque)|/dt) in all control modes. Refer to SPN 11939 [Reference Torque] to convert %/sec to Nm/sec. Request ...";
CM_ BO_ 2364673278 "Motor/Generator 5 Inverter Control";
CM_ SG_ 2364673278 MtrGnrtr5InvrtrCntrlCRC "Motor/Generator 5 Inverter Control CRC: The CRC is defined as follows:  • Length: 8 bits  • Polynomial: x^8+x^5+x^3+x^2+x+1  • Initial Value: FFh  • Input Data Reflection: Not reflected  • Result Data Reflection: Not reflected  • XOR value: FFhSAE ma...";
CM_ SG_ 2364673278 MtrGnrtr5InvrtrCntrlCntr "Motor/Generator 5 Inverter Control Counter: The message counter is used to detect situations where the transmitting ECU malfunction repeats the same frame all the time. The receiver of the information may use the counter parameter to detect this situ...";
CM_ SG_ 2364673278 MtGt5IvtCtLtsRqstOvdMd "Motor/Generator 5 Inverter Control Limits Request Override Mode: This parameter provides a way to temporarily override limits that are being received by the inverter in other messages.  It allows a specific type of limit to be transmitted at a high r...";
CM_ SG_ 2364673278 MtGt5IvtCtLtsRqstOvdMx "Motor/Generator 5 Inverter Control Limits Request Override Maximum: The Maximum limit requested by this parameter depends on the value of SPN 12046 [Control Limits Request Override Mode].In normal operating conditions, the inverter operating limits a...";
CM_ SG_ 2364673278 MtGt5IvtCtLtsRqstOvdM "Motor/Generator 5 Inverter Control Limits Request Override Minimum : The Minimum limit requested by this parameter depends on the value of SPN 12046 [Control Limits Request Override Mode].In normal operating conditions, the inverter operating limits ...";
CM_ SG_ 2364673278 MtrGnrtr5InvrtrCntrlStpntMdRqst "Motor/Generator 5 Inverter Control Setpoint Mode Request: Requests the modes for this instance of the inverter.  See SPN 12054 [Control Setpoint Mode] for the feedback to this request.Passive modes:  Modes where the inverter does not actively control...";
CM_ SG_ 2364673278 MtrGnrtr5InvrtrCntrlStpntRqst "Motor/Generator 5 Inverter Control Setpoint Request: Requests the set point for this inverter.  The type of set point requested by this parameter depends on the value of SPN 12049 [Control Setpoint Mode Request] as follows:Passive Modes: In any Passi...";
CM_ BO_ 2566000126 "Motor/Generator 5 Inverter Rate Limits Request 1";
CM_ SG_ 2566000126 MtrGnrtr5InvrtrRtLmtsRqst1CRC "Motor/Generator 5 Inverter Rate Limits Request 1 CRC: The CRC is defined as follows: • Length: 8 bits • Polynomial: x^8+x^5+x^3+x^2+x+1 • Initial Value: FFh • Input Data Reflection: Not reflected • Result Data Reflection: Not reflected • XOR value: F...";
CM_ SG_ 2566000126 MtrGnrtr5InvrtrRtLmtsRqst1Cntr "Motor/Generator 5 Inverter Rate Limits Request 1 Counter: The message counter is used to detect situations where the transmitting ECU malfunction repeats the same frame all the time. The receiver of the information may use the counter parameter to de...";
CM_ SG_ 2566000126 MtGt5IvtRtLtsRqstAstSpdRtLt "Motor/Generator 5 Inverter Rate Limits Request Absolute Speed Rate Limit: The maximum rate of change for the absolute motor speed  (i.e. |d(speed)|/dt) in all control modes. Refer to SPN 12058 [Reference Speed] to convert %/sec to RPM/sec. Request a ...";
CM_ SG_ 2566000126 MtGt5IvtRtLtsRqstAstTqRtLt "Motor/Generator 5 Inverter Rate Limits Request Absolute Torque Rate Limit: The maximum rate of change for the absolute motor torque (i.e. |d(torque)|/dt) in all control modes. Refer to SPN 12057 [Reference Torque] to convert %/sec to Nm/sec. Request ...";
CM_ BO_ 2364673790 "Motor/Generator 6 Inverter Control";
CM_ SG_ 2364673790 MtrGnrtr6InvrtrCntrlCRC "Motor/Generator 6 Inverter Control CRC: The CRC is defined as follows:  • Length: 8 bits  • Polynomial: x^8+x^5+x^3+x^2+x+1  • Initial Value: FFh  • Input Data Reflection: Not reflected  • Result Data Reflection: Not reflected  • XOR value: FFhSAE ma...";
CM_ SG_ 2364673790 MtrGnrtr6InvrtrCntrlCntr "Motor/Generator 6 Inverter Control Counter: The message counter is used to detect situations where the transmitting ECU malfunction repeats the same frame all the time. The receiver of the information may use the counter parameter to detect this situ...";
CM_ SG_ 2364673790 MtGt6IvtCtLtsRqstOvdMd "Motor/Generator 6 Inverter Control Limits Request Override Mode: This parameter provides a way to temporarily override limits that are being received by the inverter in other messages.  It allows a specific type of limit to be transmitted at a high r...";
CM_ SG_ 2364673790 MtGt6IvtCtLtsRqstOvdMx "Motor/Generator 6 Inverter Control Limits Request Override Maximum: The Maximum limit requested by this parameter depends on the value of SPN 12164 [Control Limits Request Override Mode].In normal operating conditions, the inverter operating limits a...";
CM_ SG_ 2364673790 MtGt6IvtCtLtsRqstOvdM "Motor/Generator 6 Inverter Control Limits Request Override Minimum : The Minimum limit requested by this parameter depends on the value of SPN 12164 [Control Limits Request Override Mode].In normal operating conditions, the inverter operating limits ...";
CM_ SG_ 2364673790 MtrGnrtr6InvrtrCntrlStpntMdRqst "Motor/Generator 6 Inverter Control Setpoint Mode Request: Requests the modes for this instance of the inverter.  See SPN 12172 [Control Setpoint Mode] for the feedback to this request.Passive modes:  Modes where the inverter does not actively control...";
CM_ SG_ 2364673790 MtrGnrtr6InvrtrCntrlStpntRqst "Motor/Generator 6 Inverter Control Setpoint Request: Requests the set point for this inverter.  The type of set point requested by this parameter depends on the value of SPN 12167 [Control Setpoint Mode Request] as follows:Passive Modes: In any Passi...";
CM_ BO_ 2566000638 "Motor/Generator 6 Inverter Rate Limits Request 1";
CM_ SG_ 2566000638 MtrGnrtr6InvrtrRtLmtsRqst1CRC "Motor/Generator 6 Inverter Rate Limits Request 1 CRC: The CRC is defined as follows: • Length: 8 bits • Polynomial: x^8+x^5+x^3+x^2+x+1 • Initial Value: FFh • Input Data Reflection: Not reflected • Result Data Reflection: Not reflected • XOR value: F...";
CM_ SG_ 2566000638 MtrGnrtr6InvrtrRtLmtsRqst1Cntr "Motor/Generator 6 Inverter Rate Limits Request 1 Counter: The message counter is used to detect situations where the transmitting ECU malfunction repeats the same frame all the time. The receiver of the information may use the counter parameter to de...";
CM_ SG_ 2566000638 MtGt6IvtRtLtsRqstAstSpdRtLt "Motor/Generator 6 Inverter Rate Limits Request Absolute Speed Rate Limit: The maximum rate of change for the absolute motor speed  (i.e. |d(speed)|/dt) in all control modes. Refer to SPN 12176 [Reference Speed] to convert %/sec to RPM/sec. Request a ...";
CM_ SG_ 2566000638 MtGt6IvtRtLtsRqstAstTqRtLt "Motor/Generator 6 Inverter Rate Limits Request Absolute Torque Rate Limit: The maximum rate of change for the absolute motor torque (i.e. |d(torque)|/dt) in all control modes. Refer to SPN 12175 [Reference Torque] to convert %/sec to Nm/sec. Request ...";
CM_ BO_ 2566574078 "EVCC1 Diagnostic Data 1";
CM_ SG_ 2566574078 EVCC1ControlPilotmaximumvoltage "EVCC1 Control Pilot maximum voltage.: The control pilot from the off-board EVSE is either a DC signal or a square wave. This parameter contains the DC value or the maximum voltage of the square wave.";
CM_ SG_ 2566574078 EVCC1ControlPilotminimumvoltage "EVCC1 Control Pilot minimum voltage.: The control pilot from the off-board EVSE is either a DC signal or a square wave. This parameter contains the DC value or the minimum voltage of the square wave.";
CM_ SG_ 2566574078 EVCC1ControlPilotPWMfrequency "EVCC1 Control Pilot PWM frequency: The control pilot from the off-board EVSE is either a DC signal or a square wave. This parameter contains either zero when a DC value or the frequency when a square wave.";
CM_ SG_ 2566574078 EVCC1ControlPilotDutyCycle "EVCC1 Control Pilot Duty Cycle: The control pilot from the off-board EVSE is either a DC signal or a square wave. This parameter contains the duty cycle of the PWM square wave. ";
CM_ SG_ 2566574078 EVCC1ControlPilotState "EVCC1 Control Pilot State: Indicates the EVSE state as determined by the peak voltage level of the Control Pilot and representing states A to F as defined by IEC-61851 and J1772.0000b = State A, EVSE Disconnected0001b = State B, EVSE Connected, Power...";
CM_ SG_ 2566574078 EVCC1ControlPilotSubState "EVCC1 Control Pilot Sub-State: Indicates the EVSE sub-state as determined by the frequency of the Control Pilot as defined by IEC-61851 and J1772.0000b = Sub-state 1 - DC Level, EVSE not ready/able to enable power0001b = Sub-state 2 - Valid PWM, EVSE...";
CM_ SG_ 2566574078 EVCC1Proximitycircuitvoltage "EVCC1 Proximity circuit voltage: The cable from the EVSE may contain a resistive proximity circuit.  Resistors are built into both the cable and inlet sides of the connectors and are supplied from a DC source.The voltage interpretation will depend on...";
CM_ SG_ 2566574078 EVCC1Inletconnectortemperature "EVCC1 Inlet connector temperature: Temperature reading at the vehicle inlet connector.";
CM_ SG_ 2566574078 EVCC1CompatibilityCode "EVCC1 Compatibility Code: Indicates incompatability between the vehicle and the EVSE.0000b = EVSE is compatible0001b = Digital Communications. The EVSE has attempted to establish commuications but the protocol is not supported by the EVCC.0010b = Ven...";
CM_ BO_ 2499465470 "Cab Door Control 2";
CM_ SG_ 2499465470 Mirror1LeftRightSelection "Mirror 1 Left/Right Selection: Indicates the position of a switch that selects between left or right mirror control. Signal may be used to provide visual indication of selected mirror.000b = No Mirror Selected (Neutral Position)001b = Mirror 1 Left S...";
CM_ SG_ 2499465470 Mirror2LeftRightSelection "Mirror 2 Left/Right Selection: Indicates the position of a switch that selects between left or right mirror control. Signal may be used to provide visual indication of selected mirror.000b = No Mirror Selected (Neutral Position)001b = Mirror 2 Left S...";
CM_ SG_ 2499465470 MirrorPrimarySecondarySelection "Mirror Primary/Secondary Selection: Indicates the position of a switch that selects between primary and secondary mirror sets. Signal may be used to provide visual indication of selected mirror.000b = No Mirror Selected (Neutral Position)001b = Prima...";
CM_ BO_ 2499465726 "Engine Average Information 2";
CM_ SG_ 2499465726 EngnClndrTmprtrAvrg "Engine Cylinder Temperature Average: The calculated average temperature based upon all of the engine cylinder temperatures measured at the head of each cylinder. This is the average temperature based upon the measurements in each of the engine cylind...";
CM_ SG_ 2499465726 EngnClndrBnk1TmprtrAvrg "Engine Cylinder Bank 1 Temperature Average: The calculated average temperature based upon all of the Bank 1 (left bank) engine cylinders measured at the head of each cylinder. This is the average temperature measurement of each of the engine cylinder...";
CM_ SG_ 2499465726 EngnClndrBnk2TmprtrAvrg "Engine Cylinder Bank 2 Temperature Average: The calculated average temperature based upon all of the Bank 2 (right bank) engine cylinders measured at the head of each cylinder. This is the average temperature measurement of each of the engine cylinde...";
CM_ BO_ 2566574846 "Turbocharger Information 8";
CM_ SG_ 2566574846 EngnTrhrgr3OlTmprtr "Engine Turbocharger 3 Oil Temperature: Temperature of the lubricant for the third turbocharger.";
CM_ SG_ 2566574846 EngnTrhrgr4OlTmprtr "Engine Turbocharger 4 Oil Temperature: Temperature of the lubricant for the fourth turbocharger.";
CM_ SG_ 2566574846 EngnTrhrgr5OlTmprtr "Engine Turbocharger 5 Oil Temperature: Temperature of the lubricant for the fifth turbocharger.";
CM_ SG_ 2566574846 EngnTrhrgr6OlTmprtr "Engine Turbocharger 6 Oil Temperature: Temperature of the lubricant for the sixth turbocharger.";
CM_ BO_ 2566575102 "Automated Driving System Control";
CM_ SG_ 2566575102 TSC1CntrlPrpsP7InhtCmmnd "TSC1 Control Purpose P7 Inhibit Command: Signal which indicates sending TSC1 Control Purpose P7 is inhibited or not. Devices shall not send TSC1 Control Purpose P7 when the received SPN 12868 (TSC1 Control Purpose P7 Inhibit Command) is 01b. If those...";
CM_ BO_ 2566575358 "EVSE 1 AC Status 2";
CM_ SG_ 2566575358 EVSE1ACRMSCurrent "EVSE1 AC RMS Current: AC RMS current being drawn from the EVSE.Negative values indicate power being drained from the vehicle and returned to the grid.";
CM_ SG_ 2566575358 EVSE1ACRMSVoltage "EVSE1 AC RMS Voltage: AC RMS Voltage of this connected EVSE supply.";
CM_ BO_ 2566575614 "EVSE 1 AC Status 1";
CM_ SG_ 2566575614 EVSE1ACRMSCurrentLimit "EVSE1 AC RMS Current Limit: Maximum AC RMS current that can be supplied by this EVSE.";
CM_ BO_ 2566575870 "EVSE 1 Status 1";
CM_ SG_ 2566575870 EVSE1ConnectorReleaseLatch "EVSE1 Connector Release Latch: Indicates the Release Latch status of this EVSE Connector.J1772 and IEC-61851-1 describes a momentary push-to-break switch (S3) that will be opened when the Release Latch is operated prior to removal of the connector.00...";
CM_ SG_ 2566575870 EVSE1ManualOverride "EVSE1 Manual Override: Indicates the state of a manual override switch on the vehicle, if present. The switch may be used to disable charging and unlock the the connector.00b = Manual override not active01b = Manual override active10b = Error11b = No...";
CM_ SG_ 2566575870 EVSE1ConnectorLockState "EVSE1 Connector Lock State: Indicates the state of this EVSE Connector Lock (if present).000b = Unlocked001b = Locked010b = In transition to/from Locked011b = Reserved100b = Reserved101b = No locking mechanism is available on this vehicle110b = Error...";
CM_ BO_ 2566581758 "Temperature Sensing Module 1";
CM_ SG_ 2566581758 TmprtrSnsngMdl1PrlmnrFMI "Temperature Sensing Module 1 Preliminary FMI: Used to identify the applicable J1939-73 FMI detected in the Temperature Sensing Module 1 by the manufacturer's software. When there are multiple failures, the most severe is transmitted.  A value of 31 i...";
CM_ SG_ 2566581758 TmprtrSnsngMdl2PrlmnrFMI "Temperature Sensing Module 2 Preliminary FMI: Used to identify the applicable J1939-73 FMI detected in the Temperature Sensing Module 2 by the manufacturer's software. When there are multiple failures, the most severe is transmitted.  A value of 31 i...";
CM_ SG_ 2566581758 TmprtrSnsngMdl3PrlmnrFMI "Temperature Sensing Module 3 Preliminary FMI: Used to identify the applicable J1939-73 FMI detected in the Temperature Sensing Module 3 by the manufacturer's software. When there are multiple failures, the most severe is transmitted.  A value of 31 i...";
CM_ SG_ 2566581758 TmprtrSnsngMdl4PrlmnrFMI "Temperature Sensing Module 4 Preliminary FMI: Used to identify the applicable J1939-73 FMI detected in the Temperature Sensing Module 4 by the manufacturer's software. When there are multiple failures, the most severe is transmitted.  A value of 31 i...";
CM_ SG_ 2566581758 TmprtrSnsngMdl5PrlmnrFMI "Temperature Sensing Module 5 Preliminary FMI: Used to identify the applicable J1939-73 FMI detected in the Temperature Sensing Module 5 by the manufacturer's software. When there are multiple failures, the most severe is transmitted.  A value of 31 i...";
CM_ SG_ 2566581758 TmprtrSnsngMdl6PrlmnrFMI "Temperature Sensing Module 6 Preliminary FMI: Used to identify the applicable J1939-73 FMI detected in the Temperature Sensing Module 6 by the manufacturer's software. When there are multiple failures, the most severe is transmitted.  A value of 31 i...";
CM_ SG_ 2566581758 TmprtrSnsngMdl7PrlmnrFMI "Temperature Sensing Module 7 Preliminary FMI: Used to identify the applicable J1939-73 FMI detected in the Temperature Sensing Module 7 by the manufacturer's software. When there are multiple failures, the most severe is transmitted.  A value of 31 i...";
CM_ SG_ 2566581758 TmprtrSnsngMdl8PrlmnrFMI "Temperature Sensing Module 8 Preliminary FMI: Used to identify the applicable J1939-73 FMI detected in the Temperature Sensing Module 8 by the manufacturer's software. When there are multiple failures, the most severe is transmitted.  A value of 31 i...";
CM_ BO_ 2566582014 "Temperature Sensing Module 2";
CM_ SG_ 2566582014 TmprtrSnsngMdl9PrlmnrFMI "Temperature Sensing Module 9 Preliminary FMI: Used to identify the applicable J1939-73 FMI detected in the Temperature Sensing Module 9 by the manufacturer's software. When there are multiple failures, the most severe is transmitted.  A value of 31 i...";
CM_ SG_ 2566582014 TmprtrSnsngMdl10PrlmnrFMI "Temperature Sensing Module 10 Preliminary FMI: Used to identify the applicable J1939-73 FMI detected in the Temperature Sensing Module 10 by the manufacturer's software. When there are multiple failures, the most severe is transmitted.  A value of 31...";
CM_ SG_ 2566582014 TmprtrSnsngMdl11PrlmnrFMI "Temperature Sensing Module 11 Preliminary FMI: Used to identify the applicable J1939-73 FMI detected in the Temperature Sensing Module 11 by the manufacturer's software. When there are multiple failures, the most severe is transmitted.  A value of 31...";
CM_ SG_ 2566582014 TmprtrSnsngMdl12PrlmnrFMI "Temperature Sensing Module 12 Preliminary FMI: Used to identify the applicable J1939-73 FMI detected in the Temperature Sensing Module 12 by the manufacturer's software. When there are multiple failures, the most severe is transmitted.  A value of 31...";
CM_ SG_ 2566582014 TmprtrSnsngMdl13PrlmnrFMI "Temperature Sensing Module 13 Preliminary FMI: Used to identify the applicable J1939-73 FMI detected in the Temperature Sensing Module 13 by the manufacturer's software. When there are multiple failures, the most severe is transmitted.  A value of 31...";
CM_ SG_ 2566582014 TmprtrSnsngMdl14PrlmnrFMI "Temperature Sensing Module 14 Preliminary FMI: Used to identify the applicable J1939-73 FMI detected in the Temperature Sensing Module 14 by the manufacturer's software. When there are multiple failures, the most severe is transmitted.  A value of 31...";
CM_ SG_ 2566582014 TmprtrSnsngMdl15PrlmnrFMI "Temperature Sensing Module 15 Preliminary FMI: Used to identify the applicable J1939-73 FMI detected in the Temperature Sensing Module 15 by the manufacturer's software. When there are multiple failures, the most severe is transmitted.  A value of 31...";
CM_ SG_ 2566582014 TmprtrSnsngMdl16PrlmnrFMI "Temperature Sensing Module 16 Preliminary FMI: Used to identify the applicable J1939-73 FMI detected in the Temperature Sensing Module 16 by the manufacturer's software. When there are multiple failures, the most severe is transmitted.  A value of 31...";
CM_ BO_ 2566582270 "Aftertreatment 2 SCR Service Information 3";
CM_ SG_ 2566582270 Aftrtrtmnt2SCRNrmlzdCnvrsnEffn "Aftertreatment 2 SCR Normalized Conversion Efficiency: The ratio of measured SCR Catalyst conversion efficiency to the estimated nominal SCR Catalyst conversion efficiency, represented as a percentage.";
CM_ BO_ 2566582526 "Aftertreatment 1 SCR Service Information 3";
CM_ SG_ 2566582526 Aftrtrtmnt1SCRNrmlzdCnvrsnEffn "Aftertreatment 1 SCR Normalized Conversion Efficiency: The ratio of measured SCR Catalyst conversion efficiency to the estimated nominal SCR Catalyst conversion efficiency, represented as a percentage.";
CM_ BO_ 2566582782 "PSA Times Lifetime Hours";
CM_ SG_ 2566582782 HrdLftmPrplsnSstmAtvTm "Hybrid Lifetime Propulsion System Active Time : Total propulsion system active time during the lifetime of the vehicle. OBD requires all hybrids to support this parameter. ";
CM_ SG_ 2566582782 HrdLftmIdlPrplsnSstmAtvTm "Hybrid Lifetime Idle Propulsion System Active Time : Total idle propulsion system active time (v <= 1.6 km/h) during the lifetime of the vehicle. OBD requires all hybrids to support this parameter.";
CM_ SG_ 2566582782 HrdLftmUrnPrplsnSstmAtvTm "Hybrid Lifetime Urban Propulsion System Active Time : Total urban (1.6 km/h < v <= 60 km/h) propulsion system active time during the lifetime of the vehicle. OBD requires all hybrids to support this parameter.";
CM_ BO_ 2566583038 "PSA Times Stored 100 Hours";
CM_ SG_ 2566583038 HrdStrd100HrRntPrplsnSstmAtvTm "Hybrid Stored 100 Hour Recent Propulsion System Active Time : Most recent stored cumulative propulsion system active time during 100 hours of vehicle operation. OBD requires all hybrids to support this parameter. ";
CM_ SG_ 2566583038 HrdStrd100HrIdlPrplsnSstmAtvTm "Hybrid Stored 100 Hour Idle Propulsion System Active Time: Most recent stored cumulative idle (v <= 1.6 km/h) propulsion system active time during 100 hours of vehicle operation. OBD requires all hybrids to support this parameter.";
CM_ SG_ 2566583038 HrdStrd100HrUrnPrplsnSstmAtvTm "Hybrid Stored 100 Hour Urban Propulsion System Active Time : Most recent stored cumulative urban (1.6 km/h < v <= 60 km/h) propulsion system active time during 100 hours of vehicle operation. OBD requires all hybrids to support this parameter.";
CM_ BO_ 2566583294 "PSA Times Active 100 Hours";
CM_ SG_ 2566583294 HrdAtv100HrPrplsnSstmAtvTm "Hybrid Active 100 Hour Propulsion System Active Time : Cumulative propulsion system active time during recent operation (time < 100 hours). OBD requires all hybrids to support this parameter.";
CM_ SG_ 2566583294 HrdAtv100HrIdlPrplsnSstmAtvTm "Hybrid Active 100 Hour Idle Propulsion System Active Time : Cumulative idle (v <= 1.6 km/h) propulsion system active time during recent operation (time < 100 hours). OBD requires all hybrids to support this parameter.";
CM_ SG_ 2566583294 HrdAtv100HrUrnPrplsnSstmAtvTm "Hybrid Active 100 Hour Urban Propulsion System Active Time : Cumulative urban  (1.6 km/h < v <= 60 km/h) propulsion system active time during recent operation (time < 100 hours). OBD requires all hybrids to support this parameter.";
CM_ BO_ 2566583550 "Hybrid Charge Depleting or Increasing Operation Lifetime Hours";
CM_ SG_ 2566583550 HdLtDstTvdCDptOptwtE "Hybrid Lifetime Distance Traveled in Charge Depleting Operation with Engine off : Total distance traveled while in charge depleting operation with engine off during the lifetime of the vehicle. OBD requires hybrids that are plugin vehicles to support...";
CM_ SG_ 2566583550 HdLtDstTvdCDptOptwtER "Hybrid Lifetime Distance Traveled in Charge Depleting Operation with Engine Running : Total distance traveled while in charge depleting operation with engine running during the lifetime of the vehicle. OBD requires hybrids that are plugin vehicles to...";
CM_ SG_ 2566583550 HdLtDstTvdDvStCIsOpt "Hybrid Lifetime Distance Traveled in Driver-Selectable Charge Increasing Operation : Total distance traveled while in driver-selectable charge increasing operation during the lifetime of the vehicle. OBD requires hybrids that are plugin vehicles to s...";
CM_ SG_ 2566583550 HrdLftmFlCnsmdnChrgDpltngOprtn "Hybrid Lifetime Fuel Consumed in Charge Depleting Operation : Total fuel consumption during charge-depleting operation during the lifetime of the vehicle. OBD requires hybrids that are plugin vehicles to support this parameter.  ";
CM_ SG_ 2566583550 HdLtFCsdDvStCIsOpt "Hybrid Lifetime Fuel Consumed in Driver-Selectable Charge Increasing Operation : Total fuel consumption during driver-selectable charge increasing operation during the lifetime of the vehicle. OBD requires hybrids that are plugin vehicles to support ...";
CM_ SG_ 2566583550 HdLtGdECsdCDptOptwtE "Hybrid Lifetime Grid Energy Consumed in Charge Depleting Operation with Engine off : Total grid energy supplied by the battery pack in charge depleting operation with engine off during the lifetime of the vehicle. OBD requires hybrids that are plugin...";
CM_ SG_ 2566583550 HdLtGdECsdCDptOptwtER "Hybrid Lifetime Grid Energy Consumed in Charge Depleting Operation with Engine Running : Total grid energy supplied by the battery pack in charge depleting operation with engine running during the lifetime of the vehicle. OBD requires hybrids that ar...";
CM_ SG_ 2566583550 HrdLftmGrdEnrgntthBttr "Hybrid Lifetime Grid Energy into the Battery : Total grid energy into the battery during the lifetime of the vehicle. OBD requires hybrids that are plugin vehicles to support this parameter.  ";
CM_ BO_ 2566583806 "Hybrid Charge Depleting or Increasing Operation Stored 100 Hours";
CM_ SG_ 2566583806 HdStd100HDstTvdCDptOptwtE "Hybrid Stored 100 Hour Distance Traveled in Charge Depleting Operation with Engine off : Most recent stored 100-hour cumulative distance traveled while in charge depleting operation with engine off. OBD requires hybrids that are plugin vehicles to su...";
CM_ SG_ 2566583806 HdStd100HDstTvdCDptOptwtER "Hybrid Stored 100 Hour Distance Traveled in Charge Depleting Operation with Engine Running : Most recent stored 100-hour cumulative distance traveled while in charge depleting operation with engine running. OBD requires hybrids that are plugin vehicl...";
CM_ SG_ 2566583806 HdStd100HDstTvdDvStCIsOpt "Hybrid Stored 100 Hour Distance Traveled in Driver-Selectable Charge Increasing Operation : Most recent stored 100-hour cumulative distance traveled while in driver-selectable charge increasing operation. OBD requires hybrids that are plugin vehicles...";
CM_ SG_ 2566583806 HdStd100HFCsdCDptOpt "Hybrid Stored 100 Hour Fuel Consumed in Charge Depleting Operation : Most recent stored 100-hour cumulative fuel consumed during charge-depleting operation. OBD requires hybrids that are plugin vehicles to support this parameter.  ";
CM_ SG_ 2566583806 HdStd100HFCsdDvStCIsOpt "Hybrid Stored 100 Hour Fuel Consumed in Driver-Selectable Charge Increasing Operation : Most recent stored 100-hour cumulative fuel consumed during charge-depleting operation. OBD requires hybrids that are plugin vehicles to support this parameter.  ";
CM_ SG_ 2566583806 HdStd100HGdECsdCDptOptwtE "Hybrid Stored 100 Hour Grid Energy Consumed in Charge Depleting Operation with Engine off : Most recent stored 100-hour cumulative grid energy consumed during charge depleting operation with engine off. OBD requires hybrids that are plugin vehicles t...";
CM_ SG_ 2566583806 HdStd100HGdECsdCDptOptwtER "Hybrid Stored 100 Hour Grid Energy Consumed in Charge Depleting Operation with Engine Running : Most recent stored 100-hour cumulative grid energy consumed during charge depleting operation with engine running. OBD requires hybrids that are plugin ve...";
CM_ SG_ 2566583806 HrdStrd100HrGrdEnrgntthBttr "Hybrid Stored 100 Hour Grid Energy into the Battery : Most recent stored 100-hour cumulative grid energy into the Battery. OBD requires hybrids that are plugin vehicles to support this parameter.  ";
CM_ BO_ 2566584062 "Hybrid Charge Depleting or Increasing Operation Active 100 Hours";
CM_ SG_ 2566584062 HdAtv100HDstTvdCDptOptwtE "Hybrid Active 100 Hour Distance Traveled in Charge Depleting Operation with Engine off : Cumulative distance traveled while in charge depleting operation with engine off during recent operation (time < 100 hours). OBD requires hybrids that are plugin...";
CM_ SG_ 2566584062 HdAtv100HDstTvdCDptOptwtER "Hybrid Active 100 Hour Distance Traveled in Charge Depleting Operation with Engine Running : Cumulative distance traveled while in charge depleting operation with engine running during recent operation (time < 100 hours). OBD requires hybrids that ar...";
CM_ SG_ 2566584062 HdAtv100HDstTvdDvStCIsOpt "Hybrid Active 100 Hour Distance Traveled in Driver-Selectable Charge Increasing Operation : Cumulative distance traveled while in driver-selectable charge increasing operation during recent operation (time < 100 hours). OBD requires hybrids that are ...";
CM_ SG_ 2566584062 HdAtv100HFCsdCDptOpt "Hybrid Active 100 Hour Fuel Consumed in Charge Depleting Operation : Cumulative fuel consumption during charge-depleting operation during recent operation (time < 100 hours). OBD requires hybrids that are plugin vehicles to support this parameter.  ";
CM_ SG_ 2566584062 HdAtv100HFCsdDvStCIsOpt "Hybrid Active 100 Hour Fuel Consumed in Driver-Selectable Charge Increasing Operation : Cumulative fuel consumption during driver-selectable charge increasing operation during recent operation (time < 100 hours). OBD requires hybrids that are plugin ...";
CM_ SG_ 2566584062 HdAtv100HGdECsdCDptOptwtE "Hybrid Active 100 Hour Grid Energy Consumed in Charge Depleting Operation with Engine off : Cumulative grid energy supplied by the battery pack in charge depleting operation with engine off during recent operation (time < 100 hours). OBD requires hyb...";
CM_ SG_ 2566584062 HdAtv100HGdECsdCDptOptwtER "Hybrid Active 100 Hour Grid Energy Consumed in Charge Depleting Operation with Engine Running : Cumulative grid energy supplied by the battery pack in charge depleting operation with engine running during recent operation (time < 100 hours). OBD requ...";
CM_ SG_ 2566584062 HrdAtv100HrGrdEnrgntthBttr "Hybrid Active 100 Hour Grid Energy into the Battery : Cumulative grid energy into the battery during recent operation (time < 100 hours). OBD requires hybrids that are plugin vehicles to support this parameter.  ";
CM_ BO_ 2566584318 "Aftertreatment 1 Historical Information 3";
CM_ SG_ 2566584318 Atttt1DPFRCptSttEVDst1 "Aftertreatment 1 DPF Regen Complete Starting Engine Vehicle Distance 1: The engine vehicle distance for the initiation of instance one of the last 3 complete DPF regenerations. Note: Engine vehicle distance data need not be presented in ascending ord...";
CM_ SG_ 2566584318 Atttt1DPFRCptEdEVDst1 "Aftertreatment 1 DPF Regen Complete Ending Engine Vehicle Distance 1: The engine vehicle distance for the completion of instance one of the last 3 complete DPF regenerations. Note: Engine vehicle distance data need not be presented in ascending order...";
CM_ SG_ 2566584318 Atttt1DPFRCptSttEVDst2 "Aftertreatment 1 DPF Regen Complete Starting Engine Vehicle Distance 2: The engine vehicle distance for the initiation of instance two of the last 3 complete DPF regenerations. Note: Engine vehicle distance data need not be presented in ascending ord...";
CM_ SG_ 2566584318 Atttt1DPFRCptEdEVDst2 "Aftertreatment 1 DPF Regen Complete Ending Engine Vehicle Distance 2: The engine vehicle distance for the completion of instance two of the last 3 complete DPF regenerations. Note: Engine vehicle distance data need not be presented in ascending order...";
CM_ SG_ 2566584318 Atttt1DPFRCptSttEVDst3 "Aftertreatment 1 DPF Regen Complete Starting Engine Vehicle Distance 3: The engine vehicle distance for the initiation of instance three of the last 3 complete DPF regenerations. Note: Engine vehicle distance data need not be presented in ascending o...";
CM_ SG_ 2566584318 Atttt1DPFRCptEdEVDst3 "Aftertreatment 1 DPF Regen Complete Ending Engine Vehicle Distance 3: The engine vehicle distance for the completion of instance three of the last 3 complete DPF regenerations.Note: Engine vehicle distance data need not be presented in ascending orde...";
CM_ SG_ 2566584318 Atttt1TtERtWtNDEFDv "Aftertreatment 1 Total Engine Runtime With No DEF Delivery: Total engine run time with no delivery of reductant (e.g., diesel exhaust fluid) used to control NOx emissions due to insufficient exhaust temperature, DEF quality, Insufficent DEF quantity,...";
CM_ SG_ 2566584318 Atttt1TtTSCRItBw200Css "Aftertreatment 1 Total Time SCR Inlet Below 200 Celsius: Total engine run time with exhaust temperature below 200 degrees Celsius as measured just upstream of the NOx converting catalyst. Note: If an engine has more than one NOx converting catalyst, ...";
CM_ BO_ 2566584830 "Aftertreatment 1 SCR 2 NOx Mass and NH3 Storage";
CM_ SG_ 2566584830 Aftrtrtmnt1SCR2InltNOxMssFlw "Aftertreatment 1 SCR 2 Inlet NOx Mass Flow: The mass flow of the NOx in the engine exhaust stream before the second NOx converting catalyst in aftertreatment 1.This SP provides the NOx mass flow for the outlet of the first SCR catalyst for systems wi...";
CM_ SG_ 2566584830 Aftrtrtmnt1SCR2OtltNOxMssFlw "Aftertreatment 1 SCR 2 Outlet NOx Mass Flow: The mass flow of the NOx in the engine exhaust stream after the NOx converting catalyst in aftertreatment 2.This SP shall be omitted for aftertreatment systems with exhaust flow through sequential SCR cata...";
CM_ SG_ 2566584830 Aftrtrtmnt1SCR2MdldNH3StrgLvl "Aftertreatment 1 SCR 2 Modeled NH3 Storage Level: The modeled or actual NH3 storage level in the second SCR catalyst in aftertreatment 1.";
CM_ SG_ 2566584830 Aftrtrtmnt1SCR2TrgtNH3StrgLvl "Aftertreatment 1 SCR 2 Target NH3 Storage Level: The target NH3 storage level in the second SCR catalyst in aftertreatment 1.";
CM_ BO_ 2566585086 "Aftertreatment 1 SCR 1 NOx Mass and NH3 Storage";
CM_ SG_ 2566585086 Atttt1SCR1EExstNOxMssFw "Aftertreatment 1 SCR 1 Engine Exhaust NOx Mass Flow: The mass flow of the NOx in the engine exhaust stream before the NOx converting catalyst in aftertreatment 1.If there is only one sensor that provides the engine outlet NOx mass flow in a system wi...";
CM_ SG_ 2566585086 Aftrtrtmnt1SCR1TlppNOxMssFlw "Aftertreatment 1 SCR 1 Tailpipe NOx Mass Flow: The mass flow of the NOx in the engine exhaust stream after all NOx converting catalysts in aftertreatment 1.For systems with a second, parallel flow SCR catalyst, SPN 12755 shall be used to provide the ...";
CM_ SG_ 2566585086 Aftrtrtmnt1SCR1MdldAtlStrgLvl "Aftertreatment 1 SCR 1 Modeled/Actual Storage Level: The modeled or actual NH3 storage level in the first SCR catalyst in aftertreatment 1.";
CM_ SG_ 2566585086 Aftrtrtmnt1SCR1TrgtNH3StrgLvl "Aftertreatment 1 SCR 1 Target NH3 Storage Level: The target NH3 storage level in the first SCR catalyst in aftertreatment 1.";
CM_ BO_ 2566585342 "Evaporative System Pressure and Control";
CM_ SG_ 2566585342 EVAPSystemPurgePressure "EVAP System Purge Pressure: Absolute pressure of the purge element measured in the EVAP System.";
CM_ SG_ 2566585342 EVAPSystemVaporPressure "EVAP System Vapor Pressure : Absolute pressure of the fuel vapor measured in the EVAP System.";
CM_ SG_ 2566585342 EVAPSystemPurgeValveCommand "EVAP System Purge Valve Command: Commanded relative position of the EVAP System Purge Valve ";
CM_ SG_ 2566585342 EVAPSystemPurgeValvePosition "EVAP System Purge Valve Position: Relative position of the EVAP System Purge Valve";
CM_ BO_ 2566585598 "GHG Tracking Lifetime Array Data";
CM_ SG_ 2566585598 GHGTrkngLftmEngnRnTm "GHG Tracking Lifetime Engine Run Time: Accumulated engine run time over the lifetime of the vehicle for GHG Tracking.  ";
CM_ SG_ 2566585598 GHGTrkngLftmVhlDstn "GHG Tracking Lifetime Vehicle Distance: Accumulated vehicle distance over the lifetime of the vehicle for GHG Tracking.  ";
CM_ SG_ 2566585598 GHGTrkngLftmVhlFlCnsmptn "GHG Tracking Lifetime Vehicle Fuel Consumption: Accumulated vehicle fuel consumption over the lifetime of the vehicle for GHG Tracking.  ";
CM_ SG_ 2566585598 GHGTrkngLftmEngnFlCnsmptn "GHG Tracking Lifetime Engine Fuel Consumption: Accumulated engine fuel consumption over the lifetime of the vehicle for GHG Tracking.  ";
CM_ SG_ 2566585598 GHGTrkngLftmEngnOtptEnrg "GHG Tracking Lifetime Engine Output Energy: Accumulated engine output energy over the lifetime of the vehicle for GHG Tracking.  ";
CM_ SG_ 2566585598 GHGTrkngLftmPstvKntEnrgNmrtr "GHG Tracking Lifetime Positive Kinetic Energy Numerator: Accumulated positive kinetic energy numerator (as delta-V-squared) over the lifetime of the vehicle for GHG Tracking.    The PKE Denominator is provided by GHG Tracking Lifetime Vehicle Distanc...";
CM_ SG_ 2566585598 GHGTrkngLftmUrnSpdRnTm "GHG Tracking Lifetime Urban Speed Run Time: Accumulated time at urban vehicle speeds (1.6 km/h < v <= 60 km/h) over the lifetime of the vehicle for GHG Tracking.";
CM_ SG_ 2566585598 GHGTrackingLifetimeIdleRunTime "GHG Tracking Lifetime Idle Run Time: Accumulated engine run time under idle conditions (v <= 1.6 km/h) over the lifetime of the vehicle for GHG Tracking.";
CM_ SG_ 2566585598 GHGTrkngLftmEngnIdlFlCnsmptn "GHG Tracking Lifetime Engine Idle Fuel Consumption: Accumulated fuel consumption under idle conditions (v <= 1.6 km/h) over the lifetime of the vehicle for GHG Tracking.";
CM_ SG_ 2566585598 GHGTrkngLftmEngnPwrTkOffRnTm "GHG Tracking Lifetime Engine Power Take Off Run Time: Accumulated engine runtime under power take off [PTO] governor control over the lifetime of the vehicle for GHG Tracking.  ";
CM_ SG_ 2566585598 GHGTLtEPwTOFCspt "GHG Tracking Lifetime Engine Power Take Off Fuel Consumption: Accumulated fuel consumption under power take off [PTO] governor control over the lifetime of the vehicle for GHG Tracking.  ";
CM_ SG_ 2566585598 GHGTLtAttEStdwTAtvtCt "GHG Tracking Lifetime Automatic Engine Shutdown Technology Activation Count: Accumulated activation counts of the automatic engine [idle] shutdown (AES) system over the lifetime of the vehicle for GHG Tracking.  ";
CM_ SG_ 2566585598 GHGTrkngLftmStpStrtThnlgRnTm "GHG Tracking Lifetime Stop-Start Technology Run Time: Accumulated time where the stop start system is commanding the engine off over the lifetime of the vehicle for GHG Tracking.  ";
CM_ BO_ 2566585854 "GHG Tracking Stored 100 Hour Array Data";
CM_ SG_ 2566585854 GHGTrkngStrd100HrEngnRnTm "GHG Tracking Stored 100 Hour Engine Run Time: Accumulated engine run time over the prior 100 hour period for GHG Tracking.  ";
CM_ SG_ 2566585854 GHGTrkngStrd100HrVhlDstn "GHG Tracking Stored 100 Hour Vehicle Distance: Accumulated vehicle distance over the prior 100 hour period for GHG Tracking.  ";
CM_ SG_ 2566585854 GHGTrkngStrd100HrVhlFlCnsmptn "GHG Tracking Stored 100 Hour Vehicle Fuel Consumption: Accumulated vehicle fuel consumption over the prior 100 hour period for GHG Tracking.  ";
CM_ SG_ 2566585854 GHGTrkngStrd100HrEngnFlCnsmptn "GHG Tracking Stored 100 Hour Engine Fuel Consumption: Accumulated engine fuel consumption over the prior 100 hour period for GHG Tracking.  ";
CM_ SG_ 2566585854 GHGTrkngStrd100HrEngnOtptEnrg "GHG Tracking Stored 100 Hour Engine Output Energy: Accumulated engine output energy over the prior 100 hour period for GHG Tracking.  ";
CM_ SG_ 2566585854 GHGTStd100HPstvKtENt "GHG Tracking Stored 100 Hour Positive Kinetic Energy Numerator: Accumulated positive kinetic energy numerator (as delta-V-squared) over the prior 100 hour period for GHG Tracking.  The PKE denominator is GHG Tracking Stored 100 Hour Vehicle Distance....";
CM_ SG_ 2566585854 GHGTrkngStrd100HrUrnSpdRnTm "GHG Tracking Stored 100 Hour Urban Speed Run Time: Accumulated time at urban vehicle speeds (1.6 km/h < v <= 60 km/h) over the prior 100 hour period for GHG Tracking.";
CM_ SG_ 2566585854 GHGTrkngStrd100HrIdlRnTm "GHG Tracking Stored 100 Hour Idle Run Time: Accumulated engine run time under idle conditions (v <= 1.6 km/h) over the prior 100 hour period for GHG Tracking.";
CM_ SG_ 2566585854 GHGTStd100HEIdFCspt "GHG Tracking Stored 100 Hour Engine Idle Fuel Consumption: Accumulated fuel consumption under idle conditions (v <= 1.6 km/h) over the prior 100 hour period for GHG Tracking.";
CM_ SG_ 2566585854 GHGTStd100HEPwTORT "GHG Tracking Stored 100 Hour Engine Power Take Off Run Time: Accumulated engine runtime under power take off [PTO] governor control over the prior 100 hour period for GHG Tracking.  ";
CM_ SG_ 2566585854 GHGTStd100HEPwTOFCspt "GHG Tracking Stored 100 Hour Engine Power Take Off Fuel Consumption: Accumulated fuel consumption under power take off [PTO] governor control over the prior 100 hour period for GHG Tracking.  ";
CM_ SG_ 2566585854 GHGTStd100HAttEStdwTAtvtCt "GHG Tracking Stored 100 Hour Automatic Engine Shutdown Technology Activation Count: Accumulated activation counts of the automatic engine [idle] shutdown (AES) system over the prior 100 hour period for GHG Tracking.  ";
CM_ SG_ 2566585854 GHGTStd100HStpSttTRT "GHG Tracking Stored 100 Hour Stop-Start Technology Run Time: Accumulated time where the stop start system is commanding the engine off over the prior 100 hour period for GHG Tracking.  ";
CM_ BO_ 2566586110 "GHG Tracking Active 100 Hour Array Data";
CM_ SG_ 2566586110 GHGTrkngAtv100HrEngnRnTm "GHG Tracking Active 100 Hour Engine Run Time: Accumulated engine run time over the current 100 hour period for GHG Tracking.  ";
CM_ SG_ 2566586110 GHGTrkngAtv100HrVhlDstn "GHG Tracking Active 100 Hour Vehicle Distance: Accumulated vehicle distance over the current 100 hour period for GHG Tracking.  ";
CM_ SG_ 2566586110 GHGTrkngAtv100HrVhlFlCnsmptn "GHG Tracking Active 100 Hour Vehicle Fuel Consumption: Accumulated vehicle fuel consumption over the current 100 hour period for GHG Tracking.  ";
CM_ SG_ 2566586110 GHGTrkngAtv100HrEngnFlCnsmptn "GHG Tracking Active 100 Hour Engine Fuel Consumption: Accumulated engine fuel consumption over the current 100 hour period for GHG Tracking.  ";
CM_ SG_ 2566586110 GHGTrkngAtv100HrEngnOtptEnrg "GHG Tracking Active 100 Hour Engine Output Energy: Accumulated engine output energy over the current 100 hour period for GHG Tracking.  ";
CM_ SG_ 2566586110 GHGTAtv100HPstvKtENt "GHG Tracking Active 100 Hour Positive Kinetic Energy Numerator: Accumulated positive kinetic energy numerator (as delta-V-squared) over the current 100 hour period for GHG Tracking.  The PKE denominator is GHG Tracking Active 100 Hour Vehicle Distanc...";
CM_ SG_ 2566586110 GHGTrkngAtv100HrUrnSpdRnTm "GHG Tracking Active 100 Hour Urban Speed Run Time: Accumulated time at urban vehicle speeds (1.6 km/h < v <= 60 km/h) over the current 100 hour period for GHG Tracking.";
CM_ SG_ 2566586110 GHGTrkngAtv100HrIdlRnTm "GHG Tracking Active 100 Hour Idle Run Time: Accumulated engine run time under idle conditions (v <= 1.6 km/h) over the current 100 hour period for GHG Tracking.";
CM_ SG_ 2566586110 GHGTAtv100HEIdFCspt "GHG Tracking Active 100 Hour Engine Idle Fuel Consumption: Accumulated fuel consumption under idle conditions (v <= 1.6 km/h) over the current 100 hour period for GHG Tracking.";
CM_ SG_ 2566586110 GHGTAtv100HEPwTORT "GHG Tracking Active 100 Hour Engine Power Take Off Run Time: Accumulated engine runtime under power take off [PTO] governor control over the current 100 hour period for GHG Tracking.  ";
CM_ SG_ 2566586110 GHGTAtv100HEPwTOFCspt "GHG Tracking Active 100 Hour Engine Power Take Off Fuel Consumption: Accumulated fuel consumption under power take off [PTO] governor control over the current 100 hour period for GHG Tracking.  ";
CM_ SG_ 2566586110 GHGTAtv100HAttEStdwTAtvtCt "GHG Tracking Active 100 Hour Automatic Engine Shutdown Technology Activation Count: Accumulated activation counts of the automatic engine [idle] shutdown (AES) system over the current 100 hour period for GHG Tracking.  ";
CM_ SG_ 2566586110 GHGTAtv100HStpSttTRT "GHG Tracking Active 100 Hour Stop-Start Technology Run Time: Accumulated time where the stop start system is commanding the engine off over the current 100 hour period for GHG Tracking.  ";
CM_ BO_ 2566587134 "NOx Tracking Engine Activity Lifetime Fuel Consumption Bins ";
CM_ SG_ 2566587134 NOxTEAtvtLtFCsptB1Tt "NOx Tracking Engine Activity Lifetime Fuel Consumption Bin 1 (Total): Accumulated Fuel consumption regardless of NOx sensor status over the lifetime of the vehicle for Bin 1 [Note Bin 1 is the total of Bins 2-14]";
CM_ SG_ 2566587134 NOxTEAtvtLtFCsptB2 "NOx Tracking Engine Activity Lifetime Fuel Consumption Bin 2 : Accumulated Fuel consumption regardless of NOx sensor status over the lifetime of the vehicle for Bin 2 [Note Bin 2 is the 'idle' bin]";
CM_ SG_ 2566587134 NOxTEAtvtLtFCsptB3 "NOx Tracking Engine Activity Lifetime Fuel Consumption Bin 3 : Accumulated Fuel consumption regardless of NOx sensor status over the lifetime of the vehicle for Bin 3. ";
CM_ SG_ 2566587134 NOxTEAtvtLtFCsptB4 "NOx Tracking Engine Activity Lifetime Fuel Consumption Bin 4: Accumulated Fuel consumption regardless of NOx sensor status over the lifetime of the vehicle for Bin 4. ";
CM_ SG_ 2566587134 NOxTEAtvtLtFCsptB5 "NOx Tracking Engine Activity Lifetime Fuel Consumption Bin 5: Accumulated Fuel consumption regardless of NOx sensor status over the lifetime of the vehicle for Bin 5.";
CM_ SG_ 2566587134 NOxTEAtvtLtFCsptB6 "NOx Tracking Engine Activity Lifetime Fuel Consumption Bin 6: Accumulated Fuel consumption regardless of NOx sensor status over the lifetime of the vehicle for Bin 6. ";
CM_ SG_ 2566587134 NOxTEAtvtLtFCsptB7 "NOx Tracking Engine Activity Lifetime Fuel Consumption Bin 7: Accumulated Fuel consumption regardless of NOx sensor status over the lifetime of the vehicle for Bin 7. ";
CM_ SG_ 2566587134 NOxTEAtvtLtFCsptB8 "NOx Tracking Engine Activity Lifetime Fuel Consumption Bin 8: Accumulated Fuel consumption regardless of NOx sensor status over the lifetime of the vehicle for Bin 8. ";
CM_ SG_ 2566587134 NOxTEAtvtLtFCsptB9 "NOx Tracking Engine Activity Lifetime Fuel Consumption Bin 9: Accumulated Fuel consumption regardless of NOx sensor status over the lifetime of the vehicle for Bin 9";
CM_ SG_ 2566587134 NOxTEAtvtLtFCsptB10 "NOx Tracking Engine Activity Lifetime Fuel Consumption Bin 10: Accumulated Fuel consumption regardless of NOx sensor status over the lifetime of the vehicle for Bin 10";
CM_ SG_ 2566587134 NOxTEAtvtLtFCsptB11 "NOx Tracking Engine Activity Lifetime Fuel Consumption Bin 11: Accumulated Fuel consumption regardless of NOx sensor status over the lifetime of the vehicle for Bin 11";
CM_ SG_ 2566587134 NOxTEAtvtLtFCsptB12 "NOx Tracking Engine Activity Lifetime Fuel Consumption Bin 12: Accumulated Fuel consumption regardless of NOx sensor status over the lifetime of the vehicle for Bin 12";
CM_ SG_ 2566587134 NOxTEAtvtLtFCsptB13 "NOx Tracking Engine Activity Lifetime Fuel Consumption Bin 13: Accumulated Fuel consumption regardless of NOx sensor status over the lifetime of the vehicle for Bin 13";
CM_ SG_ 2566587134 NOxTEAtvtLtFCsptB14 "NOx Tracking Engine Activity Lifetime Fuel Consumption Bin 14 : Accumulated Fuel consumption regardless of NOx sensor status over the lifetime of the vehicle for Bin 14";
CM_ SG_ 2566587134 NOxTEAtvtLtFCsptB15NTEBIN "NOx Tracking Engine Activity Lifetime Fuel Consumption Bin 15 (NTE BIN): Accumulated Fuel consumption regardless of NOx sensor status over the lifetime of the vehicle for Bin 15 [Note Bin 15 is the NTE Bin]";
CM_ SG_ 2566587134 NOxTEAtvtLtFCsptB16RB "NOx Tracking Engine Activity Lifetime Fuel Consumption Bin 16 (Regen Bin) : Accumulated Fuel consumption regardless of NOx sensor status over the lifetime of the vehicle for Bin 16 [Note Bin 16 is the Regen Bin]";
CM_ SG_ 2566587134 NOxTEAtvtLtFCsptB17MILOB "NOx Tracking Engine Activity Lifetime Fuel Consumption Bin 17 (MIL On Bin): Accumulated Fuel consumption regardless of NOx sensor status over the lifetime of the vehicle for Bin 17 [Note Bin 17 is the MIL On  bin].";
BA_DEF_ SG_  "SPN" INT 0 524287;
BA_DEF_ BO_  "VFrameFormat" ENUM  "StandardCAN","ExtendedCAN","reserved","J1939PG";
BA_DEF_DEF_  "SPN" 0;
BA_DEF_DEF_  "VFrameFormat" "J1939PG";
BA_ "SPN" SG_ 2364660734 HVESP6DshrgPwrLmtDtSttfChrg 11618;
BA_ "SPN" SG_ 2364660734 HVESP6DshrgPwrLmtDtBttrTmprtr 11619;
BA_ "SPN" SG_ 2364660734 HVESP6DsPwLtDtBttDstCdt 11620;
BA_ "SPN" SG_ 2364660734 HVESP6DshrgPwrLmtDtBttrrCllVltg 11621;
BA_ "SPN" SG_ 2364660734 HVESP6DshrgPwrLmtDtBttrCrrnt 11622;
BA_ "SPN" SG_ 2364660734 HVESP6DshrgPwrLmtDtnUndfndCs 11623;
BA_ "SPN" SG_ 2364660734 HVESP6ChrgPwrLmtDtSttfChrg 11624;
BA_ "SPN" SG_ 2364660734 HVESP6ChrgPwrLmtDtBttrTmprtr 11625;
BA_ "SPN" SG_ 2364660734 HVESP6CPwLtDtBttDstCdt 11626;
BA_ "SPN" SG_ 2364660734 HVESP6ChrgPwrLmtDtBttrrCllVltg 11627;
BA_ "SPN" SG_ 2364660734 HVESP6ChrgPwrLmtDtBttrCrrnt 11628;
BA_ "SPN" SG_ 2364660734 HVESP6ChrgPwrLmtDtnUndfndCs 11629;
BA_ "SPN" SG_ 2364660990 HVESP6AvailableDischargePower 11630;
BA_ "SPN" SG_ 2364660990 HVESP6AvailableChargePower 11631;
BA_ "SPN" SG_ 2364660990 HVESP6VoltageLevel 11632;
BA_ "SPN" SG_ 2364660990 HVESP6Current 11633;
BA_ "SPN" SG_ 2364661246 HVESP6FastUpdateStateofCharge 11634;
BA_ "SPN" SG_ 2364661246 HVESP6HighestCellVoltage 11635;
BA_ "SPN" SG_ 2364661246 HVESP6LowestCellVoltage 11636;
BA_ "SPN" SG_ 2364661246 HVESP6CllVltgDffrntlStts 11637;
BA_ "SPN" SG_ 2364661502 HVESP6HighestCellTemperature 11638;
BA_ "SPN" SG_ 2364661502 HVESP6LowestCellTemperature 11639;
BA_ "SPN" SG_ 2364661502 HVESP6AverageCellTemperature 11640;
BA_ "SPN" SG_ 2364661502 HVESP6CllTmprtrDffrntlStts 11641;
BA_ "SPN" SG_ 2364661758 HVESP6DischargeCapacity 11642;
BA_ "SPN" SG_ 2364661758 HVESP6ChargeCapacity 11643;
BA_ "SPN" SG_ 2364661758 HVESP6CellBalancingCount 11644;
BA_ "SPN" SG_ 2364662014 HVESP6DischargeCurrentLimit 11645;
BA_ "SPN" SG_ 2364662014 HVESP6ChargeCurrentLimit 11646;
BA_ "SPN" SG_ 2364662014 HVESP6LowestCellStateofCharge 11647;
BA_ "SPN" SG_ 2364662014 HVESP6HighestCellStateofCharge 11648;
BA_ "SPN" SG_ 2364662270 HVESP6BusVoltage 11649;
BA_ "SPN" SG_ 2364662270 HVESP6IgnitionVoltage 11650;
BA_ "SPN" SG_ 2364662270 HVESP6IntakeCoolantTemperature 11651;
BA_ "SPN" SG_ 2364662270 HVESP6OutletCoolantTemperature 11652;
BA_ "SPN" SG_ 2364662270 HVESP6ElectronicsTemperature 11653;
BA_ "SPN" SG_ 2364662270 HVESP6Temperature 11654;
BA_ "SPN" SG_ 2364662526 HVESP6HghVltgBsPstvCnttrStt 11655;
BA_ "SPN" SG_ 2364662526 HVESP6HghVltgBsNgtvCnttrStt 11656;
BA_ "SPN" SG_ 2364662526 HVESP6HghVltgBsDsnntFrwrnng 11657;
BA_ "SPN" SG_ 2364662526 HVESP6HghVltgBsPrChrgRlStt 11658;
BA_ "SPN" SG_ 2364662526 HVESP6CntrfPkCnttrStt 11659;
BA_ "SPN" SG_ 2364662526 HVESP6HghVltgBsAtvIsltnTstStts 11660;
BA_ "SPN" SG_ 2364662526 HVESP6HghVltgBsPssvIsltnTstStts 11661;
BA_ "SPN" SG_ 2364662526 HVESP6HVILStatus 11662;
BA_ "SPN" SG_ 2364662526 HVESP6InertiaSwitchStatus 11663;
BA_ "SPN" SG_ 2364662526 HVESP6StateofChargeStatus 11664;
BA_ "SPN" SG_ 2364662526 HVESP6CellBalanceStatus 11665;
BA_ "SPN" SG_ 2364662526 HVESP6CellBalancingActive 11666;
BA_ "SPN" SG_ 2364662526 HVESP6InternalChargerStatus 11667;
BA_ "SPN" SG_ 2364662526 HVESP6HghVltgBsCnntnStts 11668;
BA_ "SPN" SG_ 2364662526 HVESP6OperationalStatus 11669;
BA_ "SPN" SG_ 2364662782 HVESP6DischargeEnergyCapacity 11670;
BA_ "SPN" SG_ 2364662782 HVESP6ChargeEnergyCapacity 11671;
BA_ "SPN" SG_ 2364662782 HVESP6MaximumChargeVoltageLimit 11672;
BA_ "SPN" SG_ 2364663038 HVESP6Module1OperationalStatus 11673;
BA_ "SPN" SG_ 2364663038 HVESP6Module2OperationalStatus 11674;
BA_ "SPN" SG_ 2364663038 HVESP6Module3OperationalStatus 11675;
BA_ "SPN" SG_ 2364663038 HVESP6Module4OperationalStatus 11676;
BA_ "SPN" SG_ 2364663038 HVESP6Module5OperationalStatus 11677;
BA_ "SPN" SG_ 2364663038 HVESP6Module6OperationalStatus 11678;
BA_ "SPN" SG_ 2364663038 HVESP6Module7OperationalStatus 11679;
BA_ "SPN" SG_ 2364663038 HVESP6Module8OperationalStatus 11680;
BA_ "SPN" SG_ 2364663038 HVESP6Module9OperationalStatus 11681;
BA_ "SPN" SG_ 2364663038 HVESP6Module10OperationalStatus 11682;
BA_ "SPN" SG_ 2364663038 HVESP6Module11OperationalStatus 11683;
BA_ "SPN" SG_ 2364663038 HVESP6Module12OperationalStatus 11684;
BA_ "SPN" SG_ 2364663038 HVESP6Module13OperationalStatus 11685;
BA_ "SPN" SG_ 2364663038 HVESP6Module14OperationalStatus 11686;
BA_ "SPN" SG_ 2364663038 HVESP6Module15OperationalStatus 11687;
BA_ "SPN" SG_ 2364663038 HVESP6Module16OperationalStatus 11688;
BA_ "SPN" SG_ 2364663294 HVESP6ThrmlMngmntSstmSLIInptPwr 11689;
BA_ "SPN" SG_ 2364663294 HVESP6TMtSstHVtIptPw 11690;
BA_ "SPN" SG_ 2364663294 HVESP6ThrmlMngmntSstmCmprssrSpd 11691;
BA_ "SPN" SG_ 2364663294 HVESP6ThrmlMngmntSstmRltvHmdt 11692;
BA_ "SPN" SG_ 2364663294 HVESP6ThrmlMngmntSstmHtrStts 11693;
BA_ "SPN" SG_ 2364663294 HVESP6ThrmlMngmntSstmHVILStts 12814;
BA_ "SPN" SG_ 2364663294 HVESP6ThrmlMngmntSstmMd 11694;
BA_ "SPN" SG_ 2364663294 HVESP6ThrmlMngmntSstmClntLvl 12903;
BA_ "SPN" SG_ 2364663550 HVESP6HghstCllVltgMdlNmr 11695;
BA_ "SPN" SG_ 2364663550 HVESP6HghstCllVltgCllNmr 11696;
BA_ "SPN" SG_ 2364663550 HVESP6LwstCllVltgMdlNmr 11697;
BA_ "SPN" SG_ 2364663550 HVESP6LwstCllVltgCllNmr 11698;
BA_ "SPN" SG_ 2364663550 HVESP6AverageCellVoltage 11699;
BA_ "SPN" SG_ 2364663806 HVESP6HghstCllTmprtrMdlNmr 11700;
BA_ "SPN" SG_ 2364663806 HVESP6HghstCllTmprtrCllNmr 11701;
BA_ "SPN" SG_ 2364663806 HVESP6LwstCllTmprtrMdlNmr 11702;
BA_ "SPN" SG_ 2364663806 HVESP6LwstCllTmprtrCllNmr 11703;
BA_ "SPN" SG_ 2364664062 HVESP6HghstCllSttfChrgMdlNmr 11704;
BA_ "SPN" SG_ 2364664062 HVESP6HghstCllSttfChrgCllNmr 11705;
BA_ "SPN" SG_ 2364664062 HVESP6LwstCllSttfChrgMdlNmr 11706;
BA_ "SPN" SG_ 2364664062 HVESP6LwstCllSttfChrgCllNmr 11707;
BA_ "SPN" SG_ 2364664062 HVESP6HghVltgBsAtvIsltnTstRslts 11708;
BA_ "SPN" SG_ 2364664062 HVESP6HVtBsPssvIstTstRsts 11709;
BA_ "SPN" SG_ 2364664318 HVESP6BsVltgNgtvtChsssGrndVltg 11710;
BA_ "SPN" SG_ 2364664318 HVESP6VltgLvlNgtvtChsssGrndVltg 11711;
BA_ "SPN" SG_ 2364664574 MtrGnrtr3InvrtrMdFdk1CRC 11815;
BA_ "SPN" SG_ 2364664574 MtrGnrtr3InvrtrMdFdk1Cntr 11816;
BA_ "SPN" SG_ 2364664574 MtrGnrtr3InvrtrCntrlLmtsOvrrdMd 11817;
BA_ "SPN" SG_ 2364664574 MtrGnrtr3InvrtrCntrlStpntMd 11818;
BA_ "SPN" SG_ 2364664574 MtrGnrtr3InvrtrHVILStts 11805;
BA_ "SPN" SG_ 2565991422 MtrGnrtr3InvrtrLmtsAtvPwrCRC 11833;
BA_ "SPN" SG_ 2565991422 MtrGnrtr3InvrtrLmtsAtvPwrCntr 11834;
BA_ "SPN" SG_ 2565991422 MtGt3IvtLtsAtvMPwMx 11835;
BA_ "SPN" SG_ 2565991422 MtGt3IvtLtsAtvMPwM 11836;
BA_ "SPN" SG_ 2565991422 MtGt3IvtLtsAtvDCSdPwMx 11837;
BA_ "SPN" SG_ 2565991422 MtGt3IvtLtsAtvDCSdPwM 11838;
BA_ "SPN" SG_ 2565991678 MtrGnrtr3InvrtrLmtsAtvMhnlCRC 11845;
BA_ "SPN" SG_ 2565991678 MtrGnrtr3InvrtrLmtsAtvMhnlCntr 11846;
BA_ "SPN" SG_ 2565991678 MtrGnrtr3InvrtrLmtsAtvTrqMxmm 11847;
BA_ "SPN" SG_ 2565991678 MtrGnrtr3InvrtrLmtsAtvTrqMnmm 11848;
BA_ "SPN" SG_ 2565991678 MtrGnrtr3InvrtrLmtsAtvSpdMxmm 11849;
BA_ "SPN" SG_ 2565991678 MtrGnrtr3InvrtrLmtsAtvSpdMnmm 11850;
BA_ "SPN" SG_ 2565991934 MtrGnrtr3InvrtrLmtsAtvDCSdCRC 11861;
BA_ "SPN" SG_ 2565991934 MtrGnrtr3InvrtrLmtsAtvDCSdCntr 11862;
BA_ "SPN" SG_ 2565991934 MtGt3IvtLtsAtvDCSdVtMx 11863;
BA_ "SPN" SG_ 2565991934 MtGt3IvtLtsAtvDCSdVtM 11864;
BA_ "SPN" SG_ 2565991934 MtGt3IvtLtsAtvDCSdCtMx 11865;
BA_ "SPN" SG_ 2565991934 MtGt3IvtLtsAtvDCSdCtM 11866;
BA_ "SPN" SG_ 2565992190 MtrGnrtr3InvrtrSwthdIgntnVltg 11806;
BA_ "SPN" SG_ 2565992190 MtrGnrtr3InvrtrUnswthdSLIVltg 11807;
BA_ "SPN" SG_ 2565992446 MtrGnrtr3InvrtrStts2CRC 11874;
BA_ "SPN" SG_ 2565992446 MtrGnrtr3InvrtrStts2Cntr 11875;
BA_ "SPN" SG_ 2565992446 MtrGnrtr3AvllMxmmTrq 11876;
BA_ "SPN" SG_ 2565992446 MtrGnrtr3AvllMnmmTrq 11877;
BA_ "SPN" SG_ 2565992702 MtrGnrtr3InvrtrRtLmtsAtv1CRC 11908;
BA_ "SPN" SG_ 2565992702 MtrGnrtr3InvrtrRtLmtsAtv1Cntr 11909;
BA_ "SPN" SG_ 2565992702 MtGt3IvtRtLtsAtvAstSpdRtLt 11910;
BA_ "SPN" SG_ 2565992702 MtGt3IvtRtLtsAtvAstTqRtLt 11911;
BA_ "SPN" SG_ 2364666366 MtrGnrtr4InvrtrMdFdk1CRC 11933;
BA_ "SPN" SG_ 2364666366 MtrGnrtr4InvrtrMdFdk1Cntr 11934;
BA_ "SPN" SG_ 2364666366 MtrGnrtr4InvrtrCntrlLmtsOvrrdMd 11935;
BA_ "SPN" SG_ 2364666366 MtrGnrtr4InvrtrCntrlStpntMd 11936;
BA_ "SPN" SG_ 2364666366 MtrGnrtr4InvrtrHVILStts 11923;
BA_ "SPN" SG_ 2565993214 MtrGnrtr4InvrtrLmtsAtvPwrCRC 11951;
BA_ "SPN" SG_ 2565993214 MtrGnrtr4InvrtrLmtsAtvPwrCntr 11952;
BA_ "SPN" SG_ 2565993214 MtGt4IvtLtsAtvMPwMx 11953;
BA_ "SPN" SG_ 2565993214 MtGt4IvtLtsAtvMPwM 11954;
BA_ "SPN" SG_ 2565993214 MtGt4IvtLtsAtvDCSdPwMx 11955;
BA_ "SPN" SG_ 2565993214 MtGt4IvtLtsAtvDCSdPwM 11956;
BA_ "SPN" SG_ 2565993470 MtrGnrtr4InvrtrLmtsAtvMhnlCRC 11963;
BA_ "SPN" SG_ 2565993470 MtrGnrtr4InvrtrLmtsAtvMhnlCntr 11964;
BA_ "SPN" SG_ 2565993470 MtrGnrtr4InvrtrLmtsAtvTrqMxmm 11965;
BA_ "SPN" SG_ 2565993470 MtrGnrtr4InvrtrLmtsAtvTrqMnmm 11966;
BA_ "SPN" SG_ 2565993470 MtrGnrtr4InvrtrLmtsAtvSpdMxmm 11967;
BA_ "SPN" SG_ 2565993470 MtrGnrtr4InvrtrLmtsAtvSpdMnmm 11968;
BA_ "SPN" SG_ 2565993726 MtrGnrtr4InvrtrLmtsAtvDCSdCRC 11979;
BA_ "SPN" SG_ 2565993726 MtrGnrtr4InvrtrLmtsAtvDCSdCntr 11980;
BA_ "SPN" SG_ 2565993726 MtGt4IvtLtsAtvDCSdVtMx 11981;
BA_ "SPN" SG_ 2565993726 MtGt4IvtLtsAtvDCSdVtM 11982;
BA_ "SPN" SG_ 2565993726 MtGt4IvtLtsAtvDCSdCtMx 11983;
BA_ "SPN" SG_ 2565993726 MtGt4IvtLtsAtvDCSdCtM 11984;
BA_ "SPN" SG_ 2565993982 MtrGnrtr4InvrtrSwthdIgntnVltg 11924;
BA_ "SPN" SG_ 2565993982 MtrGnrtr4InvrtrUnswthdSLIVltg 11925;
BA_ "SPN" SG_ 2565994238 MtrGnrtr4InvrtrStts2CRC 11992;
BA_ "SPN" SG_ 2565994238 MtrGnrtr4InvrtrStts2Cntr 11993;
BA_ "SPN" SG_ 2565994238 MtrGnrtr4AvllMxmmTrq 11994;
BA_ "SPN" SG_ 2565994238 MtrGnrtr4AvllMnmmTrq 11995;
BA_ "SPN" SG_ 2565994494 MtrGnrtr4InvrtrRtLmtsAtv1CRC 12026;
BA_ "SPN" SG_ 2565994494 MtrGnrtr4InvrtrRtLmtsAtv1Cntr 12027;
BA_ "SPN" SG_ 2565994494 MtGt4IvtRtLtsAtvAstSpdRtLt 12028;
BA_ "SPN" SG_ 2565994494 MtGt4IvtRtLtsAtvAstTqRtLt 12029;
BA_ "SPN" SG_ 2364668158 MtrGnrtr5InvrtrMdFdk1CRC 12051;
BA_ "SPN" SG_ 2364668158 MtrGnrtr5InvrtrMdFdk1Cntr 12052;
BA_ "SPN" SG_ 2364668158 MtrGnrtr5InvrtrCntrlLmtsOvrrdMd 12053;
BA_ "SPN" SG_ 2364668158 MtrGnrtr5InvrtrCntrlStpntMd 12054;
BA_ "SPN" SG_ 2364668158 MtrGnrtr5InvrtrHVILStts 12041;
BA_ "SPN" SG_ 2565995006 MtrGnrtr5InvrtrLmtsAtvPwrCRC 12069;
BA_ "SPN" SG_ 2565995006 MtrGnrtr5InvrtrLmtsAtvPwrCntr 12070;
BA_ "SPN" SG_ 2565995006 MtGt5IvtLtsAtvMPwMx 12071;
BA_ "SPN" SG_ 2565995006 MtGt5IvtLtsAtvMPwM 12072;
BA_ "SPN" SG_ 2565995006 MtGt5IvtLtsAtvDCSdPwMx 12073;
BA_ "SPN" SG_ 2565995006 MtGt5IvtLtsAtvDCSdPwM 12074;
BA_ "SPN" SG_ 2565995262 MtrGnrtr5InvrtrLmtsAtvMhnlCRC 12081;
BA_ "SPN" SG_ 2565995262 MtrGnrtr5InvrtrLmtsAtvMhnlCntr 12082;
BA_ "SPN" SG_ 2565995262 MtrGnrtr5InvrtrLmtsAtvTrqMxmm 12083;
BA_ "SPN" SG_ 2565995262 MtrGnrtr5InvrtrLmtsAtvTrqMnmm 12084;
BA_ "SPN" SG_ 2565995262 MtrGnrtr5InvrtrLmtsAtvSpdMxmm 12085;
BA_ "SPN" SG_ 2565995262 MtrGnrtr5InvrtrLmtsAtvSpdMnmm 12086;
BA_ "SPN" SG_ 2565995518 MtrGnrtr5InvrtrLmtsAtvDCSdCRC 12097;
BA_ "SPN" SG_ 2565995518 MtrGnrtr5InvrtrLmtsAtvDCSdCntr 12098;
BA_ "SPN" SG_ 2565995518 MtGt5IvtLtsAtvDCSdVtMx 12099;
BA_ "SPN" SG_ 2565995518 MtGt5IvtLtsAtvDCSdVtM 12100;
BA_ "SPN" SG_ 2565995518 MtGt5IvtLtsAtvDCSdCtMx 12101;
BA_ "SPN" SG_ 2565995518 MtGt5IvtLtsAtvDCSdCtM 12102;
BA_ "SPN" SG_ 2565995774 MtrGnrtr5InvrtrSwthdIgntnVltg 12042;
BA_ "SPN" SG_ 2565995774 MtrGnrtr5InvrtrUnswthdSLIVltg 12043;
BA_ "SPN" SG_ 2565996030 MtrGnrtr5InvrtrStts2CRC 12110;
BA_ "SPN" SG_ 2565996030 MtrGnrtr5InvrtrStts2Cntr 12111;
BA_ "SPN" SG_ 2565996030 MtrGnrtr5AvllMxmmTrq 12112;
BA_ "SPN" SG_ 2565996030 MtrGnrtr5AvllMnmmTrq 12113;
BA_ "SPN" SG_ 2565996286 MtrGnrtr5InvrtrRtLmtsAtv1CRC 12144;
BA_ "SPN" SG_ 2565996286 MtrGnrtr5InvrtrRtLmtsAtv1Cntr 12145;
BA_ "SPN" SG_ 2565996286 MtGt5IvtRtLtsAtvAstSpdRtLt 12146;
BA_ "SPN" SG_ 2565996286 MtGt5IvtRtLtsAtvAstTqRtLt 12147;
BA_ "SPN" SG_ 2364669950 MtrGnrtr6InvrtrMdFdk1CRC 12169;
BA_ "SPN" SG_ 2364669950 MtrGnrtr6InvrtrMdFdk1Cntr 12170;
BA_ "SPN" SG_ 2364669950 MtrGnrtr6InvrtrCntrlLmtsOvrrdMd 12171;
BA_ "SPN" SG_ 2364669950 MtrGnrtr6InvrtrCntrlStpntMd 12172;
BA_ "SPN" SG_ 2364669950 MtrGnrtr6InvrtrHVILStts 12159;
BA_ "SPN" SG_ 2565996798 MtrGnrtr6InvrtrLmtsAtvPwrCRC 12187;
BA_ "SPN" SG_ 2565996798 MtrGnrtr6InvrtrLmtsAtvPwrCntr 12188;
BA_ "SPN" SG_ 2565996798 MtGt6IvtLtsAtvMPwMx 12189;
BA_ "SPN" SG_ 2565996798 MtGt6IvtLtsAtvMPwM 12190;
BA_ "SPN" SG_ 2565996798 MtGt6IvtLtsAtvDCSdPwMx 12191;
BA_ "SPN" SG_ 2565996798 MtGt6IvtLtsAtvDCSdPwM 12192;
BA_ "SPN" SG_ 2565997054 MtrGnrtr6InvrtrLmtsAtvMhnlCRC 12199;
BA_ "SPN" SG_ 2565997054 MtrGnrtr6InvrtrLmtsAtvMhnlCntr 12200;
BA_ "SPN" SG_ 2565997054 MtrGnrtr6InvrtrLmtsAtvTrqMxmm 12201;
BA_ "SPN" SG_ 2565997054 MtrGnrtr6InvrtrLmtsAtvTrqMnmm 12202;
BA_ "SPN" SG_ 2565997054 MtrGnrtr6InvrtrLmtsAtvSpdMxmm 12203;
BA_ "SPN" SG_ 2565997054 MtrGnrtr6InvrtrLmtsAtvSpdMnmm 12204;
BA_ "SPN" SG_ 2565997310 MtrGnrtr6InvrtrLmtsAtvDCSdCRC 12215;
BA_ "SPN" SG_ 2565997310 MtrGnrtr6InvrtrLmtsAtvDCSdCntr 12216;
BA_ "SPN" SG_ 2565997310 MtGt6IvtLtsAtvDCSdVtMx 12217;
BA_ "SPN" SG_ 2565997310 MtGt6IvtLtsAtvDCSdVtM 12218;
BA_ "SPN" SG_ 2565997310 MtGt6IvtLtsAtvDCSdCtMx 12219;
BA_ "SPN" SG_ 2565997310 MtGt6IvtLtsAtvDCSdCtM 12220;
BA_ "SPN" SG_ 2565997566 MtrGnrtr6InvrtrSwthdIgntnVltg 12160;
BA_ "SPN" SG_ 2565997566 MtrGnrtr6InvrtrUnswthdSLIVltg 12161;
BA_ "SPN" SG_ 2565997822 MtrGnrtr6InvrtrStts2CRC 12228;
BA_ "SPN" SG_ 2565997822 MtrGnrtr6InvrtrStts2Cntr 12229;
BA_ "SPN" SG_ 2565997822 MtrGnrtr6AvllMxmmTrq 12230;
BA_ "SPN" SG_ 2565997822 MtrGnrtr6AvllMnmmTrq 12231;
BA_ "SPN" SG_ 2565998078 MtrGnrtr6InvrtrRtLmtsAtv1CRC 12262;
BA_ "SPN" SG_ 2565998078 MtrGnrtr6InvrtrRtLmtsAtv1Cntr 12263;
BA_ "SPN" SG_ 2565998078 MtGt6IvtRtLtsAtvAstSpdRtLt 12264;
BA_ "SPN" SG_ 2565998078 MtGt6IvtRtLtsAtvAstTqRtLt 12265;
BA_ "SPN" SG_ 2364671742 BlindSpotDetectionState 12286;
BA_ "SPN" SG_ 2364671742 BlindSpotCollisionWarningLevel 12287;
BA_ "SPN" SG_ 2364671742 BlndSptWrnngRlvntOjtDttd 12288;
BA_ "SPN" SG_ 2364671742 BndOffPrltfMstImprtntOjt 12289;
BA_ "SPN" SG_ 2364671742 BlndSptDttnLftSdMntrd 12290;
BA_ "SPN" SG_ 2364671742 BlndSptDttnRghtSdMntrd 12291;
BA_ "SPN" SG_ 2364671742 BlndSptDttnFrntMntrd 12292;
BA_ "SPN" SG_ 2364671742 BlindSpotDetectionRearMonitored 12293;
BA_ "SPN" SG_ 2364671998 WinchMotorEncoderPosition 12309;
BA_ "SPN" SG_ 2364671998 WinchRevolutionCounter 12310;
BA_ "SPN" SG_ 2364672254 MtrGnrtr3InvrtrCntrlCRC 11808;
BA_ "SPN" SG_ 2364672254 MtrGnrtr3InvrtrCntrlCntr 11809;
BA_ "SPN" SG_ 2364672254 MtGt3IvtCtLtsRqstOvdMd 11810;
BA_ "SPN" SG_ 2364672254 MtGt3IvtCtLtsRqstOvdMx 11811;
BA_ "SPN" SG_ 2364672254 MtGt3IvtCtLtsRqstOvdM 11812;
BA_ "SPN" SG_ 2364672254 MtrGnrtr3InvrtrCntrlStpntMdRqst 11813;
BA_ "SPN" SG_ 2364672254 MtrGnrtr3InvrtrCntrlStpntRqst 11814;
BA_ "SPN" SG_ 2565999102 MtrGnrtr3InvrtrRtLmtsRqst1CRC 11904;
BA_ "SPN" SG_ 2565999102 MtrGnrtr3InvrtrRtLmtsRqst1Cntr 11905;
BA_ "SPN" SG_ 2565999102 MtGt3IvtRtLtsRqstAstSpdRtLt 11906;
BA_ "SPN" SG_ 2565999102 MtGt3IvtRtLtsRqstAstTqRtLt 11907;
BA_ "SPN" SG_ 2364672766 MtrGnrtr4InvrtrCntrlCRC 11926;
BA_ "SPN" SG_ 2364672766 MtrGnrtr4InvrtrCntrlCntr 11927;
BA_ "SPN" SG_ 2364672766 MtGt4IvtCtLtsRqstOvdMd 11928;
BA_ "SPN" SG_ 2364672766 MtGt4IvtCtLtsRqstOvdMx 11929;
BA_ "SPN" SG_ 2364672766 MtGt4IvtCtLtsRqstOvdM 11930;
BA_ "SPN" SG_ 2364672766 MtrGnrtr4InvrtrCntrlStpntMdRqst 11931;
BA_ "SPN" SG_ 2364672766 MtrGnrtr4InvrtrCntrlStpntRqst 11932;
BA_ "SPN" SG_ 2565999614 MtrGnrtr4InvrtrRtLmtsRqst1CRC 12022;
BA_ "SPN" SG_ 2565999614 MtrGnrtr4InvrtrRtLmtsRqst1Cntr 12023;
BA_ "SPN" SG_ 2565999614 MtGt4IvtRtLtsRqstAstSpdRtLt 12024;
BA_ "SPN" SG_ 2565999614 MtGt4IvtRtLtsRqstAstTqRtLt 12025;
BA_ "SPN" SG_ 2364673278 MtrGnrtr5InvrtrCntrlCRC 12044;
BA_ "SPN" SG_ 2364673278 MtrGnrtr5InvrtrCntrlCntr 12045;
BA_ "SPN" SG_ 2364673278 MtGt5IvtCtLtsRqstOvdMd 12046;
BA_ "SPN" SG_ 2364673278 MtGt5IvtCtLtsRqstOvdMx 12047;
BA_ "SPN" SG_ 2364673278 MtGt5IvtCtLtsRqstOvdM 12048;
BA_ "SPN" SG_ 2364673278 MtrGnrtr5InvrtrCntrlStpntMdRqst 12049;
BA_ "SPN" SG_ 2364673278 MtrGnrtr5InvrtrCntrlStpntRqst 12050;
BA_ "SPN" SG_ 2566000126 MtrGnrtr5InvrtrRtLmtsRqst1CRC 12140;
BA_ "SPN" SG_ 2566000126 MtrGnrtr5InvrtrRtLmtsRqst1Cntr 12141;
BA_ "SPN" SG_ 2566000126 MtGt5IvtRtLtsRqstAstSpdRtLt 12142;
BA_ "SPN" SG_ 2566000126 MtGt5IvtRtLtsRqstAstTqRtLt 12143;
BA_ "SPN" SG_ 2364673790 MtrGnrtr6InvrtrCntrlCRC 12162;
BA_ "SPN" SG_ 2364673790 MtrGnrtr6InvrtrCntrlCntr 12163;
BA_ "SPN" SG_ 2364673790 MtGt6IvtCtLtsRqstOvdMd 12164;
BA_ "SPN" SG_ 2364673790 MtGt6IvtCtLtsRqstOvdMx 12165;
BA_ "SPN" SG_ 2364673790 MtGt6IvtCtLtsRqstOvdM 12166;
BA_ "SPN" SG_ 2364673790 MtrGnrtr6InvrtrCntrlStpntMdRqst 12167;
BA_ "SPN" SG_ 2364673790 MtrGnrtr6InvrtrCntrlStpntRqst 12168;
BA_ "SPN" SG_ 2566000638 MtrGnrtr6InvrtrRtLmtsRqst1CRC 12258;
BA_ "SPN" SG_ 2566000638 MtrGnrtr6InvrtrRtLmtsRqst1Cntr 12259;
BA_ "SPN" SG_ 2566000638 MtGt6IvtRtLtsRqstAstSpdRtLt 12260;
BA_ "SPN" SG_ 2566000638 MtGt6IvtRtLtsRqstAstTqRtLt 12261;
BA_ "SPN" SG_ 2566574078 EVCC1ControlPilotmaximumvoltage 12927;
BA_ "SPN" SG_ 2566574078 EVCC1ControlPilotminimumvoltage 12928;
BA_ "SPN" SG_ 2566574078 EVCC1ControlPilotPWMfrequency 12929;
BA_ "SPN" SG_ 2566574078 EVCC1ControlPilotDutyCycle 12930;
BA_ "SPN" SG_ 2566574078 EVCC1ControlPilotState 12931;
BA_ "SPN" SG_ 2566574078 EVCC1ControlPilotSubState 12932;
BA_ "SPN" SG_ 2566574078 EVCC1Proximitycircuitvoltage 12933;
BA_ "SPN" SG_ 2566574078 EVCC1Inletconnectortemperature 12934;
BA_ "SPN" SG_ 2566574078 EVCC1CompatibilityCode 12935;
BA_ "SPN" SG_ 2499465470 Mirror1LeftRightSelection 12923;
BA_ "SPN" SG_ 2499465470 Mirror2LeftRightSelection 12924;
BA_ "SPN" SG_ 2499465470 MirrorPrimarySecondarySelection 12925;
BA_ "SPN" SG_ 2499465726 EngnClndrTmprtrAvrg 12894;
BA_ "SPN" SG_ 2499465726 EngnClndrBnk1TmprtrAvrg 12895;
BA_ "SPN" SG_ 2499465726 EngnClndrBnk2TmprtrAvrg 12896;
BA_ "SPN" SG_ 2566574846 EngnTrhrgr3OlTmprtr 12889;
BA_ "SPN" SG_ 2566574846 EngnTrhrgr4OlTmprtr 12890;
BA_ "SPN" SG_ 2566574846 EngnTrhrgr5OlTmprtr 12891;
BA_ "SPN" SG_ 2566574846 EngnTrhrgr6OlTmprtr 12892;
BA_ "SPN" SG_ 2566575102 TSC1CntrlPrpsP7InhtCmmnd 12868;
BA_ "SPN" SG_ 2566575358 EVSE1ACRMSCurrent 12866;
BA_ "SPN" SG_ 2566575358 EVSE1ACRMSVoltage 12867;
BA_ "SPN" SG_ 2566575614 EVSE1ACRMSCurrentLimit 12865;
BA_ "SPN" SG_ 2566575870 EVSE1ConnectorReleaseLatch 12861;
BA_ "SPN" SG_ 2566575870 EVSE1ManualOverride 12862;
BA_ "SPN" SG_ 2566575870 EVSE1ConnectorLockState 12863;
BA_ "SPN" SG_ 2566581758 TmprtrSnsngMdl1PrlmnrFMI 12820;
BA_ "SPN" SG_ 2566581758 TmprtrSnsngMdl2PrlmnrFMI 12821;
BA_ "SPN" SG_ 2566581758 TmprtrSnsngMdl3PrlmnrFMI 12822;
BA_ "SPN" SG_ 2566581758 TmprtrSnsngMdl4PrlmnrFMI 12823;
BA_ "SPN" SG_ 2566581758 TmprtrSnsngMdl5PrlmnrFMI 12824;
BA_ "SPN" SG_ 2566581758 TmprtrSnsngMdl6PrlmnrFMI 12825;
BA_ "SPN" SG_ 2566581758 TmprtrSnsngMdl7PrlmnrFMI 12826;
BA_ "SPN" SG_ 2566581758 TmprtrSnsngMdl8PrlmnrFMI 12827;
BA_ "SPN" SG_ 2566582014 TmprtrSnsngMdl9PrlmnrFMI 12828;
BA_ "SPN" SG_ 2566582014 TmprtrSnsngMdl10PrlmnrFMI 12829;
BA_ "SPN" SG_ 2566582014 TmprtrSnsngMdl11PrlmnrFMI 12830;
BA_ "SPN" SG_ 2566582014 TmprtrSnsngMdl12PrlmnrFMI 12831;
BA_ "SPN" SG_ 2566582014 TmprtrSnsngMdl13PrlmnrFMI 12832;
BA_ "SPN" SG_ 2566582014 TmprtrSnsngMdl14PrlmnrFMI 12833;
BA_ "SPN" SG_ 2566582014 TmprtrSnsngMdl15PrlmnrFMI 12834;
BA_ "SPN" SG_ 2566582014 TmprtrSnsngMdl16PrlmnrFMI 12835;
BA_ "SPN" SG_ 2566582270 Aftrtrtmnt2SCRNrmlzdCnvrsnEffn 12860;
BA_ "SPN" SG_ 2566582526 Aftrtrtmnt1SCRNrmlzdCnvrsnEffn 12859;
BA_ "SPN" SG_ 2566582782 HrdLftmPrplsnSstmAtvTm 12797;
BA_ "SPN" SG_ 2566582782 HrdLftmIdlPrplsnSstmAtvTm 12798;
BA_ "SPN" SG_ 2566582782 HrdLftmUrnPrplsnSstmAtvTm 12799;
BA_ "SPN" SG_ 2566583038 HrdStrd100HrRntPrplsnSstmAtvTm 12794;
BA_ "SPN" SG_ 2566583038 HrdStrd100HrIdlPrplsnSstmAtvTm 12795;
BA_ "SPN" SG_ 2566583038 HrdStrd100HrUrnPrplsnSstmAtvTm 12796;
BA_ "SPN" SG_ 2566583294 HrdAtv100HrPrplsnSstmAtvTm 12791;
BA_ "SPN" SG_ 2566583294 HrdAtv100HrIdlPrplsnSstmAtvTm 12792;
BA_ "SPN" SG_ 2566583294 HrdAtv100HrUrnPrplsnSstmAtvTm 12793;
BA_ "SPN" SG_ 2566583550 HdLtDstTvdCDptOptwtE 12783;
BA_ "SPN" SG_ 2566583550 HdLtDstTvdCDptOptwtER 12784;
BA_ "SPN" SG_ 2566583550 HdLtDstTvdDvStCIsOpt 12785;
BA_ "SPN" SG_ 2566583550 HrdLftmFlCnsmdnChrgDpltngOprtn 12786;
BA_ "SPN" SG_ 2566583550 HdLtFCsdDvStCIsOpt 12787;
BA_ "SPN" SG_ 2566583550 HdLtGdECsdCDptOptwtE 12788;
BA_ "SPN" SG_ 2566583550 HdLtGdECsdCDptOptwtER 12789;
BA_ "SPN" SG_ 2566583550 HrdLftmGrdEnrgntthBttr 12790;
BA_ "SPN" SG_ 2566583806 HdStd100HDstTvdCDptOptwtE 12775;
BA_ "SPN" SG_ 2566583806 HdStd100HDstTvdCDptOptwtER 12776;
BA_ "SPN" SG_ 2566583806 HdStd100HDstTvdDvStCIsOpt 12777;
BA_ "SPN" SG_ 2566583806 HdStd100HFCsdCDptOpt 12778;
BA_ "SPN" SG_ 2566583806 HdStd100HFCsdDvStCIsOpt 12779;
BA_ "SPN" SG_ 2566583806 HdStd100HGdECsdCDptOptwtE 12780;
BA_ "SPN" SG_ 2566583806 HdStd100HGdECsdCDptOptwtER 12781;
BA_ "SPN" SG_ 2566583806 HrdStrd100HrGrdEnrgntthBttr 12782;
BA_ "SPN" SG_ 2566584062 HdAtv100HDstTvdCDptOptwtE 12767;
BA_ "SPN" SG_ 2566584062 HdAtv100HDstTvdCDptOptwtER 12768;
BA_ "SPN" SG_ 2566584062 HdAtv100HDstTvdDvStCIsOpt 12769;
BA_ "SPN" SG_ 2566584062 HdAtv100HFCsdCDptOpt 12770;
BA_ "SPN" SG_ 2566584062 HdAtv100HFCsdDvStCIsOpt 12771;
BA_ "SPN" SG_ 2566584062 HdAtv100HGdECsdCDptOptwtE 12772;
BA_ "SPN" SG_ 2566584062 HdAtv100HGdECsdCDptOptwtER 12773;
BA_ "SPN" SG_ 2566584062 HrdAtv100HrGrdEnrgntthBttr 12774;
BA_ "SPN" SG_ 2566584318 Atttt1DPFRCptSttEVDst1 12759;
BA_ "SPN" SG_ 2566584318 Atttt1DPFRCptEdEVDst1 12760;
BA_ "SPN" SG_ 2566584318 Atttt1DPFRCptSttEVDst2 12761;
BA_ "SPN" SG_ 2566584318 Atttt1DPFRCptEdEVDst2 12762;
BA_ "SPN" SG_ 2566584318 Atttt1DPFRCptSttEVDst3 12763;
BA_ "SPN" SG_ 2566584318 Atttt1DPFRCptEdEVDst3 12764;
BA_ "SPN" SG_ 2566584318 Atttt1TtERtWtNDEFDv 12765;
BA_ "SPN" SG_ 2566584318 Atttt1TtTSCRItBw200Css 12766;
BA_ "SPN" SG_ 2566584830 Aftrtrtmnt1SCR2InltNOxMssFlw 12754;
BA_ "SPN" SG_ 2566584830 Aftrtrtmnt1SCR2OtltNOxMssFlw 12755;
BA_ "SPN" SG_ 2566584830 Aftrtrtmnt1SCR2MdldNH3StrgLvl 12756;
BA_ "SPN" SG_ 2566584830 Aftrtrtmnt1SCR2TrgtNH3StrgLvl 12757;
BA_ "SPN" SG_ 2566585086 Atttt1SCR1EExstNOxMssFw 12750;
BA_ "SPN" SG_ 2566585086 Aftrtrtmnt1SCR1TlppNOxMssFlw 12751;
BA_ "SPN" SG_ 2566585086 Aftrtrtmnt1SCR1MdldAtlStrgLvl 12752;
BA_ "SPN" SG_ 2566585086 Aftrtrtmnt1SCR1TrgtNH3StrgLvl 12753;
BA_ "SPN" SG_ 2566585342 EVAPSystemPurgePressure 12744;
BA_ "SPN" SG_ 2566585342 EVAPSystemVaporPressure 12745;
BA_ "SPN" SG_ 2566585342 EVAPSystemPurgeValveCommand 12746;
BA_ "SPN" SG_ 2566585342 EVAPSystemPurgeValvePosition 12747;
BA_ "SPN" SG_ 2566585598 GHGTrkngLftmEngnRnTm 12730;
BA_ "SPN" SG_ 2566585598 GHGTrkngLftmVhlDstn 12731;
BA_ "SPN" SG_ 2566585598 GHGTrkngLftmVhlFlCnsmptn 12732;
BA_ "SPN" SG_ 2566585598 GHGTrkngLftmEngnFlCnsmptn 12733;
BA_ "SPN" SG_ 2566585598 GHGTrkngLftmEngnOtptEnrg 12734;
BA_ "SPN" SG_ 2566585598 GHGTrkngLftmPstvKntEnrgNmrtr 12735;
BA_ "SPN" SG_ 2566585598 GHGTrkngLftmUrnSpdRnTm 12736;
BA_ "SPN" SG_ 2566585598 GHGTrackingLifetimeIdleRunTime 12737;
BA_ "SPN" SG_ 2566585598 GHGTrkngLftmEngnIdlFlCnsmptn 12738;
BA_ "SPN" SG_ 2566585598 GHGTrkngLftmEngnPwrTkOffRnTm 12739;
BA_ "SPN" SG_ 2566585598 GHGTLtEPwTOFCspt 12740;
BA_ "SPN" SG_ 2566585598 GHGTLtAttEStdwTAtvtCt 12741;
BA_ "SPN" SG_ 2566585598 GHGTrkngLftmStpStrtThnlgRnTm 12742;
BA_ "SPN" SG_ 2566585854 GHGTrkngStrd100HrEngnRnTm 12715;
BA_ "SPN" SG_ 2566585854 GHGTrkngStrd100HrVhlDstn 12716;
BA_ "SPN" SG_ 2566585854 GHGTrkngStrd100HrVhlFlCnsmptn 12717;
BA_ "SPN" SG_ 2566585854 GHGTrkngStrd100HrEngnFlCnsmptn 12718;
BA_ "SPN" SG_ 2566585854 GHGTrkngStrd100HrEngnOtptEnrg 12719;
BA_ "SPN" SG_ 2566585854 GHGTStd100HPstvKtENt 12720;
BA_ "SPN" SG_ 2566585854 GHGTrkngStrd100HrUrnSpdRnTm 12721;
BA_ "SPN" SG_ 2566585854 GHGTrkngStrd100HrIdlRnTm 12722;
BA_ "SPN" SG_ 2566585854 GHGTStd100HEIdFCspt 12723;
BA_ "SPN" SG_ 2566585854 GHGTStd100HEPwTORT 12724;
BA_ "SPN" SG_ 2566585854 GHGTStd100HEPwTOFCspt 12725;
BA_ "SPN" SG_ 2566585854 GHGTStd100HAttEStdwTAtvtCt 12726;
BA_ "SPN" SG_ 2566585854 GHGTStd100HStpSttTRT 12727;
BA_ "SPN" SG_ 2566586110 GHGTrkngAtv100HrEngnRnTm 12700;
BA_ "SPN" SG_ 2566586110 GHGTrkngAtv100HrVhlDstn 12701;
BA_ "SPN" SG_ 2566586110 GHGTrkngAtv100HrVhlFlCnsmptn 12702;
BA_ "SPN" SG_ 2566586110 GHGTrkngAtv100HrEngnFlCnsmptn 12703;
BA_ "SPN" SG_ 2566586110 GHGTrkngAtv100HrEngnOtptEnrg 12704;
BA_ "SPN" SG_ 2566586110 GHGTAtv100HPstvKtENt 12705;
BA_ "SPN" SG_ 2566586110 GHGTrkngAtv100HrUrnSpdRnTm 12706;
BA_ "SPN" SG_ 2566586110 GHGTrkngAtv100HrIdlRnTm 12707;
BA_ "SPN" SG_ 2566586110 GHGTAtv100HEIdFCspt 12708;
BA_ "SPN" SG_ 2566586110 GHGTAtv100HEPwTORT 12709;
BA_ "SPN" SG_ 2566586110 GHGTAtv100HEPwTOFCspt 12710;
BA_ "SPN" SG_ 2566586110 GHGTAtv100HAttEStdwTAtvtCt 12711;
BA_ "SPN" SG_ 2566586110 GHGTAtv100HStpSttTRT 12712;
BA_ "SPN" SG_ 2566587134 NOxTEAtvtLtFCsptB1Tt 12675;
BA_ "SPN" SG_ 2566587134 NOxTEAtvtLtFCsptB2 12676;
BA_ "SPN" SG_ 2566587134 NOxTEAtvtLtFCsptB3 12677;
BA_ "SPN" SG_ 2566587134 NOxTEAtvtLtFCsptB4 12678;
BA_ "SPN" SG_ 2566587134 NOxTEAtvtLtFCsptB5 12679;
BA_ "SPN" SG_ 2566587134 NOxTEAtvtLtFCsptB6 12680;
BA_ "SPN" SG_ 2566587134 NOxTEAtvtLtFCsptB7 12681;
BA_ "SPN" SG_ 2566587134 NOxTEAtvtLtFCsptB8 12682;
BA_ "SPN" SG_ 2566587134 NOxTEAtvtLtFCsptB9 12683;
BA_ "SPN" SG_ 2566587134 NOxTEAtvtLtFCsptB10 12684;
BA_ "SPN" SG_ 2566587134 NOxTEAtvtLtFCsptB11 12685;
BA_ "SPN" SG_ 2566587134 NOxTEAtvtLtFCsptB12 12686;
BA_ "SPN" SG_ 2566587134 NOxTEAtvtLtFCsptB13 12687;
BA_ "SPN" SG_ 2566587134 NOxTEAtvtLtFCsptB14 12688;
BA_ "SPN" SG_ 2566587134 NOxTEAtvtLtFCsptB15NTEBIN 12689;
BA_ "SPN" SG_ 2566587134 NOxTEAtvtLtFCsptB16RB 12690;
BA_ "SPN" SG_ 2566587134 NOxTEAtvtLtFCsptB17MILOB 12713;
